VERSION "AgOpen Rate CAN ECU DBC with S0-S3 banks, 16 nodes, and service CAN"

NS_ :

BS_:

BU_: MASTER TOOL NODE1 NODE2 NODE3 NODE4 NODE5 NODE6 NODE7 NODE8 NODE9 NODE10 NODE11 NODE12 NODE13 NODE14 NODE15 NODE16

VAL_TABLE_ VT_system_mode 0 "OFF" 1 "MANUAL" 2 "AUTO" 3 "CALIBRATION" 4 "FAULT_HOLD";
VAL_TABLE_ VT_node_command 0 "NOP" 1 "ENABLE" 2 "DISABLE" 3 "ZERO_POS" 4 "CLEAR_FAULT";
VAL_TABLE_ VT_estop_cmd 165 "EMERGENCY_STOP";
VAL_TABLE_ VT_estop_reason 0 "manual" 1 "comm_fault" 2 "master_fault";
VAL_TABLE_ VT_srv_ack_result 0 "OK" 1 "unknown_command" 2 "bad_payload" 3 "wrong_uid" 4 "busy" 5 "save_failed" 6 "not_supported";
VAL_TABLE_ VT_srv_ident_mode 0 "LED_BLINK" 1 "SHORT_JOG";
VAL_TABLE_ VT_srv_test_mode 0 "RUN" 1 "COAST" 2 "BRAKE";

BO_ 128 S0_GLOBAL_CONTROL: 8 MASTER
 SG_ system_mode : 0|8@1+ (1,0) [0|255] ""  MASTER,NODE1,NODE2,NODE3,NODE4,NODE5,NODE6,NODE7,NODE8,NODE9,NODE10,NODE11,NODE12,NODE13,NODE14,NODE15,NODE16,TOOL
 SG_ control_flags : 8|8@1+ (1,0) [0|255] "bitfield"  MASTER,NODE1,NODE2,NODE3,NODE4,NODE5,NODE6,NODE7,NODE8,NODE9,NODE10,NODE11,NODE12,NODE13,NODE14,NODE15,NODE16,TOOL
 SG_ base_rpm : 16|16@1- (0.1,0) [-3276.8|3276.7] "rpm"  MASTER,NODE1,NODE2,NODE3,NODE4,NODE5,NODE6,NODE7,NODE8,NODE9,NODE10,NODE11,NODE12,NODE13,NODE14,NODE15,NODE16,TOOL
 SG_ sync_pos : 32|16@1+ (1.52587890625e-05,0) [0|0.9999847412109375] "rev"  MASTER,NODE1,NODE2,NODE3,NODE4,NODE5,NODE6,NODE7,NODE8,NODE9,NODE10,NODE11,NODE12,NODE13,NODE14,NODE15,NODE16,TOOL
 SG_ sequence : 48|8@1+ (1,0) [0|255] ""  MASTER,NODE1,NODE2,NODE3,NODE4,NODE5,NODE6,NODE7,NODE8,NODE9,NODE10,NODE11,NODE12,NODE13,NODE14,NODE15,NODE16,TOOL
 SG_ reserved : 56|8@1+ (1,0) [0|255] ""  MASTER,NODE1,NODE2,NODE3,NODE4,NODE5,NODE6,NODE7,NODE8,NODE9,NODE10,NODE11,NODE12,NODE13,NODE14,NODE15,NODE16,TOOL

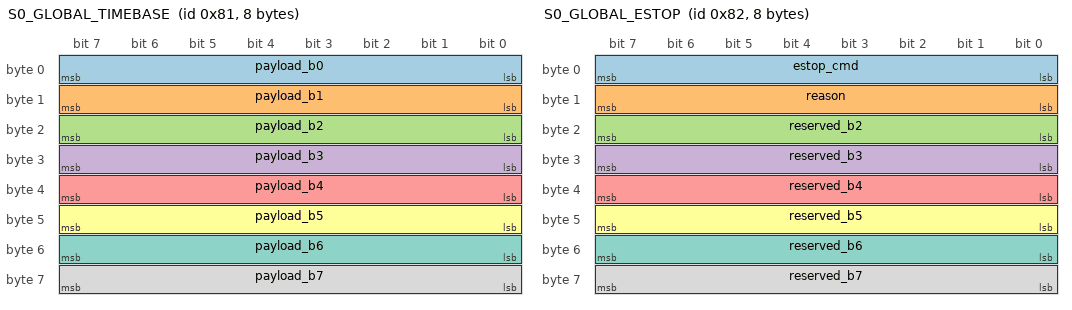
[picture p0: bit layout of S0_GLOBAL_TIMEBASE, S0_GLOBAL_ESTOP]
BO_ 129 S0_GLOBAL_TIMEBASE: 8 MASTER
 SG_ payload_b0 : 0|8@1+ (1,0) [0|255] "raw"  MASTER,NODE1,NODE2,NODE3,NODE4,NODE5,NODE6,NODE7,NODE8,NODE9,NODE10,NODE11,NODE12,NODE13,NODE14,NODE15,NODE16,TOOL
 SG_ payload_b1 : 8|8@1+ (1,0) [0|255] "raw"  MASTER,NODE1,NODE2,NODE3,NODE4,NODE5,NODE6,NODE7,NODE8,NODE9,NODE10,NODE11,NODE12,NODE13,NODE14,NODE15,NODE16,TOOL
 SG_ payload_b2 : 16|8@1+ (1,0) [0|255] "raw"  MASTER,NODE1,NODE2,NODE3,NODE4,NODE5,NODE6,NODE7,NODE8,NODE9,NODE10,NODE11,NODE12,NODE13,NODE14,NODE15,NODE16,TOOL
 SG_ payload_b3 : 24|8@1+ (1,0) [0|255] "raw"  MASTER,NODE1,NODE2,NODE3,NODE4,NODE5,NODE6,NODE7,NODE8,NODE9,NODE10,NODE11,NODE12,NODE13,NODE14,NODE15,NODE16,TOOL
 SG_ payload_b4 : 32|8@1+ (1,0) [0|255] "raw"  MASTER,NODE1,NODE2,NODE3,NODE4,NODE5,NODE6,NODE7,NODE8,NODE9,NODE10,NODE11,NODE12,NODE13,NODE14,NODE15,NODE16,TOOL
 SG_ payload_b5 : 40|8@1+ (1,0) [0|255] "raw"  MASTER,NODE1,NODE2,NODE3,NODE4,NODE5,NODE6,NODE7,NODE8,NODE9,NODE10,NODE11,NODE12,NODE13,NODE14,NODE15,NODE16,TOOL
 SG_ payload_b6 : 48|8@1+ (1,0) [0|255] "raw"  MASTER,NODE1,NODE2,NODE3,NODE4,NODE5,NODE6,NODE7,NODE8,NODE9,NODE10,NODE11,NODE12,NODE13,NODE14,NODE15,NODE16,TOOL
 SG_ payload_b7 : 56|8@1+ (1,0) [0|255] "raw"  MASTER,NODE1,NODE2,NODE3,NODE4,NODE5,NODE6,NODE7,NODE8,NODE9,NODE10,NODE11,NODE12,NODE13,NODE14,NODE15,NODE16,TOOL

BO_ 130 S0_GLOBAL_ESTOP: 8 MASTER
 SG_ estop_cmd : 0|8@1+ (1,0) [0|255] ""  MASTER,NODE1,NODE2,NODE3,NODE4,NODE5,NODE6,NODE7,NODE8,NODE9,NODE10,NODE11,NODE12,NODE13,NODE14,NODE15,NODE16,TOOL
 SG_ reason : 8|8@1+ (1,0) [0|255] ""  MASTER,NODE1,NODE2,NODE3,NODE4,NODE5,NODE6,NODE7,NODE8,NODE9,NODE10,NODE11,NODE12,NODE13,NODE14,NODE15,NODE16,TOOL
 SG_ reserved_b2 : 16|8@1+ (1,0) [0|255] ""  MASTER,NODE1,NODE2,NODE3,NODE4,NODE5,NODE6,NODE7,NODE8,NODE9,NODE10,NODE11,NODE12,NODE13,NODE14,NODE15,NODE16,TOOL
 SG_ reserved_b3 : 24|8@1+ (1,0) [0|255] ""  MASTER,NODE1,NODE2,NODE3,NODE4,NODE5,NODE6,NODE7,NODE8,NODE9,NODE10,NODE11,NODE12,NODE13,NODE14,NODE15,NODE16,TOOL
 SG_ reserved_b4 : 32|8@1+ (1,0) [0|255] ""  MASTER,NODE1,NODE2,NODE3,NODE4,NODE5,NODE6,NODE7,NODE8,NODE9,NODE10,NODE11,NODE12,NODE13,NODE14,NODE15,NODE16,TOOL
 SG_ reserved_b5 : 40|8@1+ (1,0) [0|255] ""  MASTER,NODE1,NODE2,NODE3,NODE4,NODE5,NODE6,NODE7,NODE8,NODE9,NODE10,NODE11,NODE12,NODE13,NODE14,NODE15,NODE16,TOOL
 SG_ reserved_b6 : 48|8@1+ (1,0) [0|255] ""  MASTER,NODE1,NODE2,NODE3,NODE4,NODE5,NODE6,NODE7,NODE8,NODE9,NODE10,NODE11,NODE12,NODE13,NODE14,NODE15,NODE16,TOOL
 SG_ reserved_b7 : 56|8@1+ (1,0) [0|255] ""  MASTER,NODE1,NODE2,NODE3,NODE4,NODE5,NODE6,NODE7,NODE8,NODE9,NODE10,NODE11,NODE12,NODE13,NODE14,NODE15,NODE16,TOOL

BO_ 257 S0_NODE_CMD_1: 8 MASTER
 SG_ node_command : 0|8@1+ (1,0) [0|255] ""  MASTER,NODE1,NODE2,NODE3,NODE4,NODE5,NODE6,NODE7,NODE8,NODE9,NODE10,NODE11,NODE12,NODE13,NODE14,NODE15,NODE16,TOOL
 SG_ node_flags : 8|8@1+ (1,0) [0|255] "bitfield"  MASTER,NODE1,NODE2,NODE3,NODE4,NODE5,NODE6,NODE7,NODE8,NODE9,NODE10,NODE11,NODE12,NODE13,NODE14,NODE15,NODE16,TOOL
 SG_ trim_rpm : 16|16@1- (0.1,0) [-3276.8|3276.7] "rpm"  MASTER,NODE1,NODE2,NODE3,NODE4,NODE5,NODE6,NODE7,NODE8,NODE9,NODE10,NODE11,NODE12,NODE13,NODE14,NODE15,NODE16,TOOL
 SG_ section_mask : 32|16@1+ (1,0) [0|65535] "bitmask"  MASTER,NODE1,NODE2,NODE3,NODE4,NODE5,NODE6,NODE7,NODE8,NODE9,NODE10,NODE11,NODE12,NODE13,NODE14,NODE15,NODE16,TOOL
 SG_ seq : 48|8@1+ (1,0) [0|255] ""  MASTER,NODE1,NODE2,NODE3,NODE4,NODE5,NODE6,NODE7,NODE8,NODE9,NODE10,NODE11,NODE12,NODE13,NODE14,NODE15,NODE16,TOOL
 SG_ reserved : 56|8@1+ (1,0) [0|255] ""  MASTER,NODE1,NODE2,NODE3,NODE4,NODE5,NODE6,NODE7,NODE8,NODE9,NODE10,NODE11,NODE12,NODE13,NODE14,NODE15,NODE16,TOOL

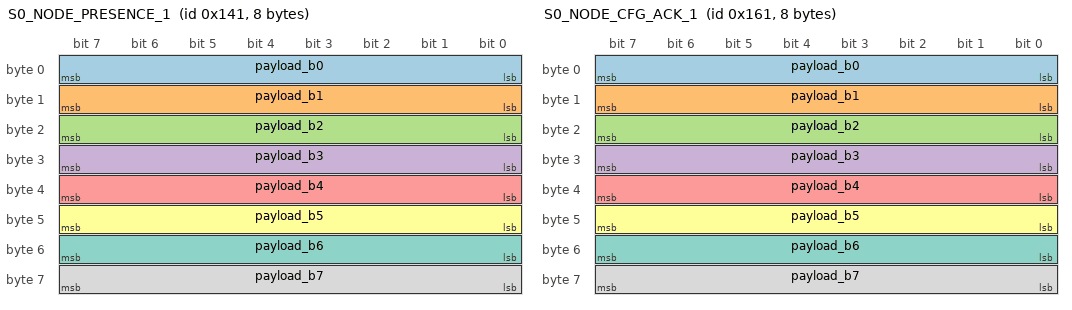
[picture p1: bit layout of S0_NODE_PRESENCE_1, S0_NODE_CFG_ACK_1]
BO_ 321 S0_NODE_PRESENCE_1: 8 NODE1
 SG_ payload_b0 : 0|8@1+ (1,0) [0|255] "raw"  MASTER,NODE1,NODE2,NODE3,NODE4,NODE5,NODE6,NODE7,NODE8,NODE9,NODE10,NODE11,NODE12,NODE13,NODE14,NODE15,NODE16,TOOL
 SG_ payload_b1 : 8|8@1+ (1,0) [0|255] "raw"  MASTER,NODE1,NODE2,NODE3,NODE4,NODE5,NODE6,NODE7,NODE8,NODE9,NODE10,NODE11,NODE12,NODE13,NODE14,NODE15,NODE16,TOOL
 SG_ payload_b2 : 16|8@1+ (1,0) [0|255] "raw"  MASTER,NODE1,NODE2,NODE3,NODE4,NODE5,NODE6,NODE7,NODE8,NODE9,NODE10,NODE11,NODE12,NODE13,NODE14,NODE15,NODE16,TOOL
 SG_ payload_b3 : 24|8@1+ (1,0) [0|255] "raw"  MASTER,NODE1,NODE2,NODE3,NODE4,NODE5,NODE6,NODE7,NODE8,NODE9,NODE10,NODE11,NODE12,NODE13,NODE14,NODE15,NODE16,TOOL
 SG_ payload_b4 : 32|8@1+ (1,0) [0|255] "raw"  MASTER,NODE1,NODE2,NODE3,NODE4,NODE5,NODE6,NODE7,NODE8,NODE9,NODE10,NODE11,NODE12,NODE13,NODE14,NODE15,NODE16,TOOL
 SG_ payload_b5 : 40|8@1+ (1,0) [0|255] "raw"  MASTER,NODE1,NODE2,NODE3,NODE4,NODE5,NODE6,NODE7,NODE8,NODE9,NODE10,NODE11,NODE12,NODE13,NODE14,NODE15,NODE16,TOOL
 SG_ payload_b6 : 48|8@1+ (1,0) [0|255] "raw"  MASTER,NODE1,NODE2,NODE3,NODE4,NODE5,NODE6,NODE7,NODE8,NODE9,NODE10,NODE11,NODE12,NODE13,NODE14,NODE15,NODE16,TOOL
 SG_ payload_b7 : 56|8@1+ (1,0) [0|255] "raw"  MASTER,NODE1,NODE2,NODE3,NODE4,NODE5,NODE6,NODE7,NODE8,NODE9,NODE10,NODE11,NODE12,NODE13,NODE14,NODE15,NODE16,TOOL

BO_ 353 S0_NODE_CFG_ACK_1: 8 NODE1
 SG_ payload_b0 : 0|8@1+ (1,0) [0|255] "raw"  MASTER,NODE1,NODE2,NODE3,NODE4,NODE5,NODE6,NODE7,NODE8,NODE9,NODE10,NODE11,NODE12,NODE13,NODE14,NODE15,NODE16,TOOL
 SG_ payload_b1 : 8|8@1+ (1,0) [0|255] "raw"  MASTER,NODE1,NODE2,NODE3,NODE4,NODE5,NODE6,NODE7,NODE8,NODE9,NODE10,NODE11,NODE12,NODE13,NODE14,NODE15,NODE16,TOOL
 SG_ payload_b2 : 16|8@1+ (1,0) [0|255] "raw"  MASTER,NODE1,NODE2,NODE3,NODE4,NODE5,NODE6,NODE7,NODE8,NODE9,NODE10,NODE11,NODE12,NODE13,NODE14,NODE15,NODE16,TOOL
 SG_ payload_b3 : 24|8@1+ (1,0) [0|255] "raw"  MASTER,NODE1,NODE2,NODE3,NODE4,NODE5,NODE6,NODE7,NODE8,NODE9,NODE10,NODE11,NODE12,NODE13,NODE14,NODE15,NODE16,TOOL
 SG_ payload_b4 : 32|8@1+ (1,0) [0|255] "raw"  MASTER,NODE1,NODE2,NODE3,NODE4,NODE5,NODE6,NODE7,NODE8,NODE9,NODE10,NODE11,NODE12,NODE13,NODE14,NODE15,NODE16,TOOL
 SG_ payload_b5 : 40|8@1+ (1,0) [0|255] "raw"  MASTER,NODE1,NODE2,NODE3,NODE4,NODE5,NODE6,NODE7,NODE8,NODE9,NODE10,NODE11,NODE12,NODE13,NODE14,NODE15,NODE16,TOOL
 SG_ payload_b6 : 48|8@1+ (1,0) [0|255] "raw"  MASTER,NODE1,NODE2,NODE3,NODE4,NODE5,NODE6,NODE7,NODE8,NODE9,NODE10,NODE11,NODE12,NODE13,NODE14,NODE15,NODE16,TOOL
 SG_ payload_b7 : 56|8@1+ (1,0) [0|255] "raw"  MASTER,NODE1,NODE2,NODE3,NODE4,NODE5,NODE6,NODE7,NODE8,NODE9,NODE10,NODE11,NODE12,NODE13,NODE14,NODE15,NODE16,TOOL

BO_ 385 S0_NODE_STATUS_FAST_1: 8 NODE1
 SG_ status_flags : 0|8@1+ (1,0) [0|255] "bitfield"  MASTER,NODE1,NODE2,NODE3,NODE4,NODE5,NODE6,NODE7,NODE8,NODE9,NODE10,NODE11,NODE12,NODE13,NODE14,NODE15,NODE16,TOOL
 SG_ error_code : 8|8@1+ (1,0) [0|255] ""  MASTER,NODE1,NODE2,NODE3,NODE4,NODE5,NODE6,NODE7,NODE8,NODE9,NODE10,NODE11,NODE12,NODE13,NODE14,NODE15,NODE16,TOOL
 SG_ actual_rpm : 16|16@1- (0.1,0) [-3276.8|3276.7] "rpm"  MASTER,NODE1,NODE2,NODE3,NODE4,NODE5,NODE6,NODE7,NODE8,NODE9,NODE10,NODE11,NODE12,NODE13,NODE14,NODE15,NODE16,TOOL
 SG_ actual_pos : 32|16@1+ (1.52587890625e-05,0) [0|0.9999847412109375] "rev"  MASTER,NODE1,NODE2,NODE3,NODE4,NODE5,NODE6,NODE7,NODE8,NODE9,NODE10,NODE11,NODE12,NODE13,NODE14,NODE15,NODE16,TOOL
 SG_ alive_counter : 48|8@1+ (1,0) [0|255] ""  MASTER,NODE1,NODE2,NODE3,NODE4,NODE5,NODE6,NODE7,NODE8,NODE9,NODE10,NODE11,NODE12,NODE13,NODE14,NODE15,NODE16,TOOL
 SG_ sync_error : 56|8@1- (0.00390625,0) [-0.5|0.49609375] "rev"  MASTER,NODE1,NODE2,NODE3,NODE4,NODE5,NODE6,NODE7,NODE8,NODE9,NODE10,NODE11,NODE12,NODE13,NODE14,NODE15,NODE16,TOOL

BO_ 449 S0_NODE_DIAG_1: 8 NODE1
 SG_ bus_voltage : 0|16@1+ (0.1,0) [0|6553.5] "V"  MASTER,NODE1,NODE2,NODE3,NODE4,NODE5,NODE6,NODE7,NODE8,NODE9,NODE10,NODE11,NODE12,NODE13,NODE14,NODE15,NODE16,TOOL
 SG_ motor_current : 16|16@1- (0.1,0) [-3276.8|3276.7] "A"  MASTER,NODE1,NODE2,NODE3,NODE4,NODE5,NODE6,NODE7,NODE8,NODE9,NODE10,NODE11,NODE12,NODE13,NODE14,NODE15,NODE16,TOOL
 SG_ controller_temp : 32|8@1- (1,0) [-128|127] "degC"  MASTER,NODE1,NODE2,NODE3,NODE4,NODE5,NODE6,NODE7,NODE8,NODE9,NODE10,NODE11,NODE12,NODE13,NODE14,NODE15,NODE16,TOOL
 SG_ motor_temp : 40|8@1- (1,0) [-128|127] "degC"  MASTER,NODE1,NODE2,NODE3,NODE4,NODE5,NODE6,NODE7,NODE8,NODE9,NODE10,NODE11,NODE12,NODE13,NODE14,NODE15,NODE16,TOOL
 SG_ fault_flags : 48|8@1+ (1,0) [0|255] "bitfield"  MASTER,NODE1,NODE2,NODE3,NODE4,NODE5,NODE6,NODE7,NODE8,NODE9,NODE10,NODE11,NODE12,NODE13,NODE14,NODE15,NODE16,TOOL
 SG_ warning_flags : 56|8@1+ (1,0) [0|255] "bitfield"  MASTER,NODE1,NODE2,NODE3,NODE4,NODE5,NODE6,NODE7,NODE8,NODE9,NODE10,NODE11,NODE12,NODE13,NODE14,NODE15,NODE16,TOOL

BO_ 258 S0_NODE_CMD_2: 8 MASTER
 SG_ node_command : 0|8@1+ (1,0) [0|255] ""  MASTER,NODE1,NODE2,NODE3,NODE4,NODE5,NODE6,NODE7,NODE8,NODE9,NODE10,NODE11,NODE12,NODE13,NODE14,NODE15,NODE16,TOOL
 SG_ node_flags : 8|8@1+ (1,0) [0|255] "bitfield"  MASTER,NODE1,NODE2,NODE3,NODE4,NODE5,NODE6,NODE7,NODE8,NODE9,NODE10,NODE11,NODE12,NODE13,NODE14,NODE15,NODE16,TOOL
 SG_ trim_rpm : 16|16@1- (0.1,0) [-3276.8|3276.7] "rpm"  MASTER,NODE1,NODE2,NODE3,NODE4,NODE5,NODE6,NODE7,NODE8,NODE9,NODE10,NODE11,NODE12,NODE13,NODE14,NODE15,NODE16,TOOL
 SG_ section_mask : 32|16@1+ (1,0) [0|65535] "bitmask"  MASTER,NODE1,NODE2,NODE3,NODE4,NODE5,NODE6,NODE7,NODE8,NODE9,NODE10,NODE11,NODE12,NODE13,NODE14,NODE15,NODE16,TOOL
 SG_ seq : 48|8@1+ (1,0) [0|255] ""  MASTER,NODE1,NODE2,NODE3,NODE4,NODE5,NODE6,NODE7,NODE8,NODE9,NODE10,NODE11,NODE12,NODE13,NODE14,NODE15,NODE16,TOOL
 SG_ reserved : 56|8@1+ (1,0) [0|255] ""  MASTER,NODE1,NODE2,NODE3,NODE4,NODE5,NODE6,NODE7,NODE8,NODE9,NODE10,NODE11,NODE12,NODE13,NODE14,NODE15,NODE16,TOOL

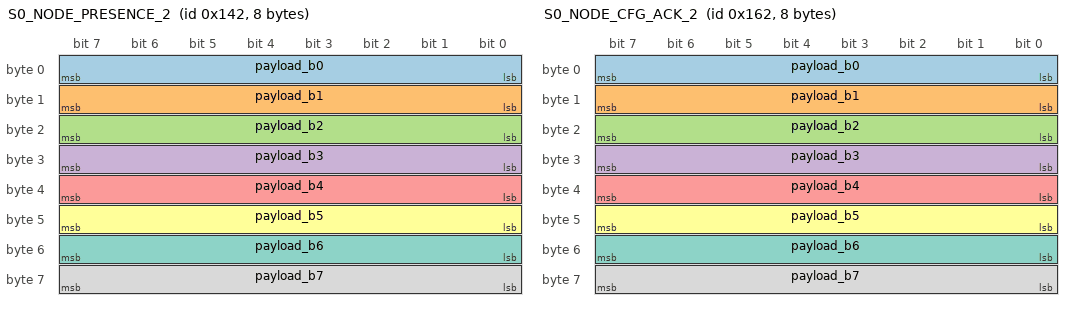
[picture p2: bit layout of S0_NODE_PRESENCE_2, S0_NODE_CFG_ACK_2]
BO_ 322 S0_NODE_PRESENCE_2: 8 NODE2
 SG_ payload_b0 : 0|8@1+ (1,0) [0|255] "raw"  MASTER,NODE1,NODE2,NODE3,NODE4,NODE5,NODE6,NODE7,NODE8,NODE9,NODE10,NODE11,NODE12,NODE13,NODE14,NODE15,NODE16,TOOL
 SG_ payload_b1 : 8|8@1+ (1,0) [0|255] "raw"  MASTER,NODE1,NODE2,NODE3,NODE4,NODE5,NODE6,NODE7,NODE8,NODE9,NODE10,NODE11,NODE12,NODE13,NODE14,NODE15,NODE16,TOOL
 SG_ payload_b2 : 16|8@1+ (1,0) [0|255] "raw"  MASTER,NODE1,NODE2,NODE3,NODE4,NODE5,NODE6,NODE7,NODE8,NODE9,NODE10,NODE11,NODE12,NODE13,NODE14,NODE15,NODE16,TOOL
 SG_ payload_b3 : 24|8@1+ (1,0) [0|255] "raw"  MASTER,NODE1,NODE2,NODE3,NODE4,NODE5,NODE6,NODE7,NODE8,NODE9,NODE10,NODE11,NODE12,NODE13,NODE14,NODE15,NODE16,TOOL
 SG_ payload_b4 : 32|8@1+ (1,0) [0|255] "raw"  MASTER,NODE1,NODE2,NODE3,NODE4,NODE5,NODE6,NODE7,NODE8,NODE9,NODE10,NODE11,NODE12,NODE13,NODE14,NODE15,NODE16,TOOL
 SG_ payload_b5 : 40|8@1+ (1,0) [0|255] "raw"  MASTER,NODE1,NODE2,NODE3,NODE4,NODE5,NODE6,NODE7,NODE8,NODE9,NODE10,NODE11,NODE12,NODE13,NODE14,NODE15,NODE16,TOOL
 SG_ payload_b6 : 48|8@1+ (1,0) [0|255] "raw"  MASTER,NODE1,NODE2,NODE3,NODE4,NODE5,NODE6,NODE7,NODE8,NODE9,NODE10,NODE11,NODE12,NODE13,NODE14,NODE15,NODE16,TOOL
 SG_ payload_b7 : 56|8@1+ (1,0) [0|255] "raw"  MASTER,NODE1,NODE2,NODE3,NODE4,NODE5,NODE6,NODE7,NODE8,NODE9,NODE10,NODE11,NODE12,NODE13,NODE14,NODE15,NODE16,TOOL

BO_ 354 S0_NODE_CFG_ACK_2: 8 NODE2
 SG_ payload_b0 : 0|8@1+ (1,0) [0|255] "raw"  MASTER,NODE1,NODE2,NODE3,NODE4,NODE5,NODE6,NODE7,NODE8,NODE9,NODE10,NODE11,NODE12,NODE13,NODE14,NODE15,NODE16,TOOL
 SG_ payload_b1 : 8|8@1+ (1,0) [0|255] "raw"  MASTER,NODE1,NODE2,NODE3,NODE4,NODE5,NODE6,NODE7,NODE8,NODE9,NODE10,NODE11,NODE12,NODE13,NODE14,NODE15,NODE16,TOOL
 SG_ payload_b2 : 16|8@1+ (1,0) [0|255] "raw"  MASTER,NODE1,NODE2,NODE3,NODE4,NODE5,NODE6,NODE7,NODE8,NODE9,NODE10,NODE11,NODE12,NODE13,NODE14,NODE15,NODE16,TOOL
 SG_ payload_b3 : 24|8@1+ (1,0) [0|255] "raw"  MASTER,NODE1,NODE2,NODE3,NODE4,NODE5,NODE6,NODE7,NODE8,NODE9,NODE10,NODE11,NODE12,NODE13,NODE14,NODE15,NODE16,TOOL
 SG_ payload_b4 : 32|8@1+ (1,0) [0|255] "raw"  MASTER,NODE1,NODE2,NODE3,NODE4,NODE5,NODE6,NODE7,NODE8,NODE9,NODE10,NODE11,NODE12,NODE13,NODE14,NODE15,NODE16,TOOL
 SG_ payload_b5 : 40|8@1+ (1,0) [0|255] "raw"  MASTER,NODE1,NODE2,NODE3,NODE4,NODE5,NODE6,NODE7,NODE8,NODE9,NODE10,NODE11,NODE12,NODE13,NODE14,NODE15,NODE16,TOOL
 SG_ payload_b6 : 48|8@1+ (1,0) [0|255] "raw"  MASTER,NODE1,NODE2,NODE3,NODE4,NODE5,NODE6,NODE7,NODE8,NODE9,NODE10,NODE11,NODE12,NODE13,NODE14,NODE15,NODE16,TOOL
 SG_ payload_b7 : 56|8@1+ (1,0) [0|255] "raw"  MASTER,NODE1,NODE2,NODE3,NODE4,NODE5,NODE6,NODE7,NODE8,NODE9,NODE10,NODE11,NODE12,NODE13,NODE14,NODE15,NODE16,TOOL

BO_ 386 S0_NODE_STATUS_FAST_2: 8 NODE2
 SG_ status_flags : 0|8@1+ (1,0) [0|255] "bitfield"  MASTER,NODE1,NODE2,NODE3,NODE4,NODE5,NODE6,NODE7,NODE8,NODE9,NODE10,NODE11,NODE12,NODE13,NODE14,NODE15,NODE16,TOOL
 SG_ error_code : 8|8@1+ (1,0) [0|255] ""  MASTER,NODE1,NODE2,NODE3,NODE4,NODE5,NODE6,NODE7,NODE8,NODE9,NODE10,NODE11,NODE12,NODE13,NODE14,NODE15,NODE16,TOOL
 SG_ actual_rpm : 16|16@1- (0.1,0) [-3276.8|3276.7] "rpm"  MASTER,NODE1,NODE2,NODE3,NODE4,NODE5,NODE6,NODE7,NODE8,NODE9,NODE10,NODE11,NODE12,NODE13,NODE14,NODE15,NODE16,TOOL
 SG_ actual_pos : 32|16@1+ (1.52587890625e-05,0) [0|0.9999847412109375] "rev"  MASTER,NODE1,NODE2,NODE3,NODE4,NODE5,NODE6,NODE7,NODE8,NODE9,NODE10,NODE11,NODE12,NODE13,NODE14,NODE15,NODE16,TOOL
 SG_ alive_counter : 48|8@1+ (1,0) [0|255] ""  MASTER,NODE1,NODE2,NODE3,NODE4,NODE5,NODE6,NODE7,NODE8,NODE9,NODE10,NODE11,NODE12,NODE13,NODE14,NODE15,NODE16,TOOL
 SG_ sync_error : 56|8@1- (0.00390625,0) [-0.5|0.49609375] "rev"  MASTER,NODE1,NODE2,NODE3,NODE4,NODE5,NODE6,NODE7,NODE8,NODE9,NODE10,NODE11,NODE12,NODE13,NODE14,NODE15,NODE16,TOOL

BO_ 450 S0_NODE_DIAG_2: 8 NODE2
 SG_ bus_voltage : 0|16@1+ (0.1,0) [0|6553.5] "V"  MASTER,NODE1,NODE2,NODE3,NODE4,NODE5,NODE6,NODE7,NODE8,NODE9,NODE10,NODE11,NODE12,NODE13,NODE14,NODE15,NODE16,TOOL
 SG_ motor_current : 16|16@1- (0.1,0) [-3276.8|3276.7] "A"  MASTER,NODE1,NODE2,NODE3,NODE4,NODE5,NODE6,NODE7,NODE8,NODE9,NODE10,NODE11,NODE12,NODE13,NODE14,NODE15,NODE16,TOOL
 SG_ controller_temp : 32|8@1- (1,0) [-128|127] "degC"  MASTER,NODE1,NODE2,NODE3,NODE4,NODE5,NODE6,NODE7,NODE8,NODE9,NODE10,NODE11,NODE12,NODE13,NODE14,NODE15,NODE16,TOOL
 SG_ motor_temp : 40|8@1- (1,0) [-128|127] "degC"  MASTER,NODE1,NODE2,NODE3,NODE4,NODE5,NODE6,NODE7,NODE8,NODE9,NODE10,NODE11,NODE12,NODE13,NODE14,NODE15,NODE16,TOOL
 SG_ fault_flags : 48|8@1+ (1,0) [0|255] "bitfield"  MASTER,NODE1,NODE2,NODE3,NODE4,NODE5,NODE6,NODE7,NODE8,NODE9,NODE10,NODE11,NODE12,NODE13,NODE14,NODE15,NODE16,TOOL
 SG_ warning_flags : 56|8@1+ (1,0) [0|255] "bitfield"  MASTER,NODE1,NODE2,NODE3,NODE4,NODE5,NODE6,NODE7,NODE8,NODE9,NODE10,NODE11,NODE12,NODE13,NODE14,NODE15,NODE16,TOOL

BO_ 259 S0_NODE_CMD_3: 8 MASTER
 SG_ node_command : 0|8@1+ (1,0) [0|255] ""  MASTER,NODE1,NODE2,NODE3,NODE4,NODE5,NODE6,NODE7,NODE8,NODE9,NODE10,NODE11,NODE12,NODE13,NODE14,NODE15,NODE16,TOOL
 SG_ node_flags : 8|8@1+ (1,0) [0|255] "bitfield"  MASTER,NODE1,NODE2,NODE3,NODE4,NODE5,NODE6,NODE7,NODE8,NODE9,NODE10,NODE11,NODE12,NODE13,NODE14,NODE15,NODE16,TOOL
 SG_ trim_rpm : 16|16@1- (0.1,0) [-3276.8|3276.7] "rpm"  MASTER,NODE1,NODE2,NODE3,NODE4,NODE5,NODE6,NODE7,NODE8,NODE9,NODE10,NODE11,NODE12,NODE13,NODE14,NODE15,NODE16,TOOL
 SG_ section_mask : 32|16@1+ (1,0) [0|65535] "bitmask"  MASTER,NODE1,NODE2,NODE3,NODE4,NODE5,NODE6,NODE7,NODE8,NODE9,NODE10,NODE11,NODE12,NODE13,NODE14,NODE15,NODE16,TOOL
 SG_ seq : 48|8@1+ (1,0) [0|255] ""  MASTER,NODE1,NODE2,NODE3,NODE4,NODE5,NODE6,NODE7,NODE8,NODE9,NODE10,NODE11,NODE12,NODE13,NODE14,NODE15,NODE16,TOOL
 SG_ reserved : 56|8@1+ (1,0) [0|255] ""  MASTER,NODE1,NODE2,NODE3,NODE4,NODE5,NODE6,NODE7,NODE8,NODE9,NODE10,NODE11,NODE12,NODE13,NODE14,NODE15,NODE16,TOOL

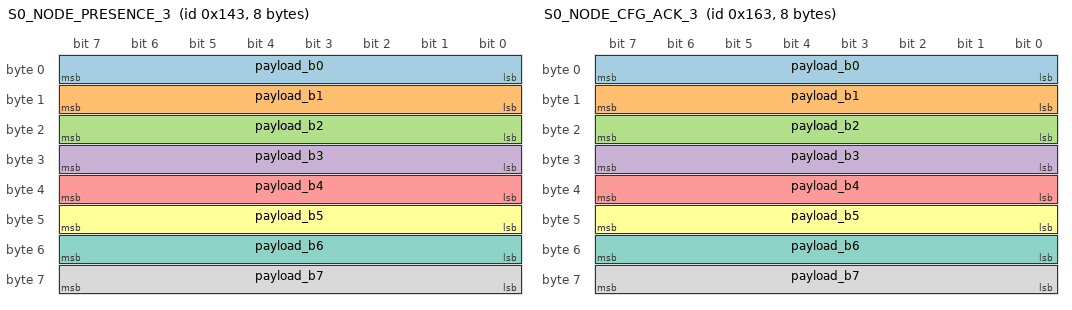
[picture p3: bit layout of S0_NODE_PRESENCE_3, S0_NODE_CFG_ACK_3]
BO_ 323 S0_NODE_PRESENCE_3: 8 NODE3
 SG_ payload_b0 : 0|8@1+ (1,0) [0|255] "raw"  MASTER,NODE1,NODE2,NODE3,NODE4,NODE5,NODE6,NODE7,NODE8,NODE9,NODE10,NODE11,NODE12,NODE13,NODE14,NODE15,NODE16,TOOL
 SG_ payload_b1 : 8|8@1+ (1,0) [0|255] "raw"  MASTER,NODE1,NODE2,NODE3,NODE4,NODE5,NODE6,NODE7,NODE8,NODE9,NODE10,NODE11,NODE12,NODE13,NODE14,NODE15,NODE16,TOOL
 SG_ payload_b2 : 16|8@1+ (1,0) [0|255] "raw"  MASTER,NODE1,NODE2,NODE3,NODE4,NODE5,NODE6,NODE7,NODE8,NODE9,NODE10,NODE11,NODE12,NODE13,NODE14,NODE15,NODE16,TOOL
 SG_ payload_b3 : 24|8@1+ (1,0) [0|255] "raw"  MASTER,NODE1,NODE2,NODE3,NODE4,NODE5,NODE6,NODE7,NODE8,NODE9,NODE10,NODE11,NODE12,NODE13,NODE14,NODE15,NODE16,TOOL
 SG_ payload_b4 : 32|8@1+ (1,0) [0|255] "raw"  MASTER,NODE1,NODE2,NODE3,NODE4,NODE5,NODE6,NODE7,NODE8,NODE9,NODE10,NODE11,NODE12,NODE13,NODE14,NODE15,NODE16,TOOL
 SG_ payload_b5 : 40|8@1+ (1,0) [0|255] "raw"  MASTER,NODE1,NODE2,NODE3,NODE4,NODE5,NODE6,NODE7,NODE8,NODE9,NODE10,NODE11,NODE12,NODE13,NODE14,NODE15,NODE16,TOOL
 SG_ payload_b6 : 48|8@1+ (1,0) [0|255] "raw"  MASTER,NODE1,NODE2,NODE3,NODE4,NODE5,NODE6,NODE7,NODE8,NODE9,NODE10,NODE11,NODE12,NODE13,NODE14,NODE15,NODE16,TOOL
 SG_ payload_b7 : 56|8@1+ (1,0) [0|255] "raw"  MASTER,NODE1,NODE2,NODE3,NODE4,NODE5,NODE6,NODE7,NODE8,NODE9,NODE10,NODE11,NODE12,NODE13,NODE14,NODE15,NODE16,TOOL

BO_ 355 S0_NODE_CFG_ACK_3: 8 NODE3
 SG_ payload_b0 : 0|8@1+ (1,0) [0|255] "raw"  MASTER,NODE1,NODE2,NODE3,NODE4,NODE5,NODE6,NODE7,NODE8,NODE9,NODE10,NODE11,NODE12,NODE13,NODE14,NODE15,NODE16,TOOL
 SG_ payload_b1 : 8|8@1+ (1,0) [0|255] "raw"  MASTER,NODE1,NODE2,NODE3,NODE4,NODE5,NODE6,NODE7,NODE8,NODE9,NODE10,NODE11,NODE12,NODE13,NODE14,NODE15,NODE16,TOOL
 SG_ payload_b2 : 16|8@1+ (1,0) [0|255] "raw"  MASTER,NODE1,NODE2,NODE3,NODE4,NODE5,NODE6,NODE7,NODE8,NODE9,NODE10,NODE11,NODE12,NODE13,NODE14,NODE15,NODE16,TOOL
 SG_ payload_b3 : 24|8@1+ (1,0) [0|255] "raw"  MASTER,NODE1,NODE2,NODE3,NODE4,NODE5,NODE6,NODE7,NODE8,NODE9,NODE10,NODE11,NODE12,NODE13,NODE14,NODE15,NODE16,TOOL
 SG_ payload_b4 : 32|8@1+ (1,0) [0|255] "raw"  MASTER,NODE1,NODE2,NODE3,NODE4,NODE5,NODE6,NODE7,NODE8,NODE9,NODE10,NODE11,NODE12,NODE13,NODE14,NODE15,NODE16,TOOL
 SG_ payload_b5 : 40|8@1+ (1,0) [0|255] "raw"  MASTER,NODE1,NODE2,NODE3,NODE4,NODE5,NODE6,NODE7,NODE8,NODE9,NODE10,NODE11,NODE12,NODE13,NODE14,NODE15,NODE16,TOOL
 SG_ payload_b6 : 48|8@1+ (1,0) [0|255] "raw"  MASTER,NODE1,NODE2,NODE3,NODE4,NODE5,NODE6,NODE7,NODE8,NODE9,NODE10,NODE11,NODE12,NODE13,NODE14,NODE15,NODE16,TOOL
 SG_ payload_b7 : 56|8@1+ (1,0) [0|255] "raw"  MASTER,NODE1,NODE2,NODE3,NODE4,NODE5,NODE6,NODE7,NODE8,NODE9,NODE10,NODE11,NODE12,NODE13,NODE14,NODE15,NODE16,TOOL

BO_ 387 S0_NODE_STATUS_FAST_3: 8 NODE3
 SG_ status_flags : 0|8@1+ (1,0) [0|255] "bitfield"  MASTER,NODE1,NODE2,NODE3,NODE4,NODE5,NODE6,NODE7,NODE8,NODE9,NODE10,NODE11,NODE12,NODE13,NODE14,NODE15,NODE16,TOOL
 SG_ error_code : 8|8@1+ (1,0) [0|255] ""  MASTER,NODE1,NODE2,NODE3,NODE4,NODE5,NODE6,NODE7,NODE8,NODE9,NODE10,NODE11,NODE12,NODE13,NODE14,NODE15,NODE16,TOOL
 SG_ actual_rpm : 16|16@1- (0.1,0) [-3276.8|3276.7] "rpm"  MASTER,NODE1,NODE2,NODE3,NODE4,NODE5,NODE6,NODE7,NODE8,NODE9,NODE10,NODE11,NODE12,NODE13,NODE14,NODE15,NODE16,TOOL
 SG_ actual_pos : 32|16@1+ (1.52587890625e-05,0) [0|0.9999847412109375] "rev"  MASTER,NODE1,NODE2,NODE3,NODE4,NODE5,NODE6,NODE7,NODE8,NODE9,NODE10,NODE11,NODE12,NODE13,NODE14,NODE15,NODE16,TOOL
 SG_ alive_counter : 48|8@1+ (1,0) [0|255] ""  MASTER,NODE1,NODE2,NODE3,NODE4,NODE5,NODE6,NODE7,NODE8,NODE9,NODE10,NODE11,NODE12,NODE13,NODE14,NODE15,NODE16,TOOL
 SG_ sync_error : 56|8@1- (0.00390625,0) [-0.5|0.49609375] "rev"  MASTER,NODE1,NODE2,NODE3,NODE4,NODE5,NODE6,NODE7,NODE8,NODE9,NODE10,NODE11,NODE12,NODE13,NODE14,NODE15,NODE16,TOOL

BO_ 451 S0_NODE_DIAG_3: 8 NODE3
 SG_ bus_voltage : 0|16@1+ (0.1,0) [0|6553.5] "V"  MASTER,NODE1,NODE2,NODE3,NODE4,NODE5,NODE6,NODE7,NODE8,NODE9,NODE10,NODE11,NODE12,NODE13,NODE14,NODE15,NODE16,TOOL
 SG_ motor_current : 16|16@1- (0.1,0) [-3276.8|3276.7] "A"  MASTER,NODE1,NODE2,NODE3,NODE4,NODE5,NODE6,NODE7,NODE8,NODE9,NODE10,NODE11,NODE12,NODE13,NODE14,NODE15,NODE16,TOOL
 SG_ controller_temp : 32|8@1- (1,0) [-128|127] "degC"  MASTER,NODE1,NODE2,NODE3,NODE4,NODE5,NODE6,NODE7,NODE8,NODE9,NODE10,NODE11,NODE12,NODE13,NODE14,NODE15,NODE16,TOOL
 SG_ motor_temp : 40|8@1- (1,0) [-128|127] "degC"  MASTER,NODE1,NODE2,NODE3,NODE4,NODE5,NODE6,NODE7,NODE8,NODE9,NODE10,NODE11,NODE12,NODE13,NODE14,NODE15,NODE16,TOOL
 SG_ fault_flags : 48|8@1+ (1,0) [0|255] "bitfield"  MASTER,NODE1,NODE2,NODE3,NODE4,NODE5,NODE6,NODE7,NODE8,NODE9,NODE10,NODE11,NODE12,NODE13,NODE14,NODE15,NODE16,TOOL
 SG_ warning_flags : 56|8@1+ (1,0) [0|255] "bitfield"  MASTER,NODE1,NODE2,NODE3,NODE4,NODE5,NODE6,NODE7,NODE8,NODE9,NODE10,NODE11,NODE12,NODE13,NODE14,NODE15,NODE16,TOOL

BO_ 260 S0_NODE_CMD_4: 8 MASTER
 SG_ node_command : 0|8@1+ (1,0) [0|255] ""  MASTER,NODE1,NODE2,NODE3,NODE4,NODE5,NODE6,NODE7,NODE8,NODE9,NODE10,NODE11,NODE12,NODE13,NODE14,NODE15,NODE16,TOOL
 SG_ node_flags : 8|8@1+ (1,0) [0|255] "bitfield"  MASTER,NODE1,NODE2,NODE3,NODE4,NODE5,NODE6,NODE7,NODE8,NODE9,NODE10,NODE11,NODE12,NODE13,NODE14,NODE15,NODE16,TOOL
 SG_ trim_rpm : 16|16@1- (0.1,0) [-3276.8|3276.7] "rpm"  MASTER,NODE1,NODE2,NODE3,NODE4,NODE5,NODE6,NODE7,NODE8,NODE9,NODE10,NODE11,NODE12,NODE13,NODE14,NODE15,NODE16,TOOL
 SG_ section_mask : 32|16@1+ (1,0) [0|65535] "bitmask"  MASTER,NODE1,NODE2,NODE3,NODE4,NODE5,NODE6,NODE7,NODE8,NODE9,NODE10,NODE11,NODE12,NODE13,NODE14,NODE15,NODE16,TOOL
 SG_ seq : 48|8@1+ (1,0) [0|255] ""  MASTER,NODE1,NODE2,NODE3,NODE4,NODE5,NODE6,NODE7,NODE8,NODE9,NODE10,NODE11,NODE12,NODE13,NODE14,NODE15,NODE16,TOOL
 SG_ reserved : 56|8@1+ (1,0) [0|255] ""  MASTER,NODE1,NODE2,NODE3,NODE4,NODE5,NODE6,NODE7,NODE8,NODE9,NODE10,NODE11,NODE12,NODE13,NODE14,NODE15,NODE16,TOOL

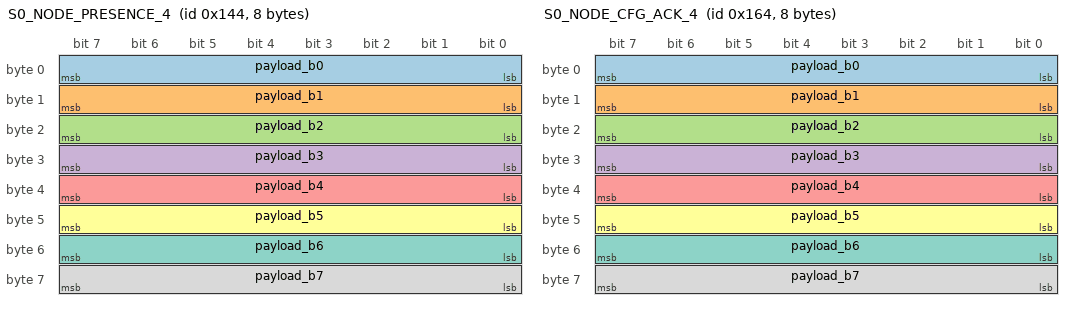
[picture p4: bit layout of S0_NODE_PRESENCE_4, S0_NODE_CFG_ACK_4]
BO_ 324 S0_NODE_PRESENCE_4: 8 NODE4
 SG_ payload_b0 : 0|8@1+ (1,0) [0|255] "raw"  MASTER,NODE1,NODE2,NODE3,NODE4,NODE5,NODE6,NODE7,NODE8,NODE9,NODE10,NODE11,NODE12,NODE13,NODE14,NODE15,NODE16,TOOL
 SG_ payload_b1 : 8|8@1+ (1,0) [0|255] "raw"  MASTER,NODE1,NODE2,NODE3,NODE4,NODE5,NODE6,NODE7,NODE8,NODE9,NODE10,NODE11,NODE12,NODE13,NODE14,NODE15,NODE16,TOOL
 SG_ payload_b2 : 16|8@1+ (1,0) [0|255] "raw"  MASTER,NODE1,NODE2,NODE3,NODE4,NODE5,NODE6,NODE7,NODE8,NODE9,NODE10,NODE11,NODE12,NODE13,NODE14,NODE15,NODE16,TOOL
 SG_ payload_b3 : 24|8@1+ (1,0) [0|255] "raw"  MASTER,NODE1,NODE2,NODE3,NODE4,NODE5,NODE6,NODE7,NODE8,NODE9,NODE10,NODE11,NODE12,NODE13,NODE14,NODE15,NODE16,TOOL
 SG_ payload_b4 : 32|8@1+ (1,0) [0|255] "raw"  MASTER,NODE1,NODE2,NODE3,NODE4,NODE5,NODE6,NODE7,NODE8,NODE9,NODE10,NODE11,NODE12,NODE13,NODE14,NODE15,NODE16,TOOL
 SG_ payload_b5 : 40|8@1+ (1,0) [0|255] "raw"  MASTER,NODE1,NODE2,NODE3,NODE4,NODE5,NODE6,NODE7,NODE8,NODE9,NODE10,NODE11,NODE12,NODE13,NODE14,NODE15,NODE16,TOOL
 SG_ payload_b6 : 48|8@1+ (1,0) [0|255] "raw"  MASTER,NODE1,NODE2,NODE3,NODE4,NODE5,NODE6,NODE7,NODE8,NODE9,NODE10,NODE11,NODE12,NODE13,NODE14,NODE15,NODE16,TOOL
 SG_ payload_b7 : 56|8@1+ (1,0) [0|255] "raw"  MASTER,NODE1,NODE2,NODE3,NODE4,NODE5,NODE6,NODE7,NODE8,NODE9,NODE10,NODE11,NODE12,NODE13,NODE14,NODE15,NODE16,TOOL

BO_ 356 S0_NODE_CFG_ACK_4: 8 NODE4
 SG_ payload_b0 : 0|8@1+ (1,0) [0|255] "raw"  MASTER,NODE1,NODE2,NODE3,NODE4,NODE5,NODE6,NODE7,NODE8,NODE9,NODE10,NODE11,NODE12,NODE13,NODE14,NODE15,NODE16,TOOL
 SG_ payload_b1 : 8|8@1+ (1,0) [0|255] "raw"  MASTER,NODE1,NODE2,NODE3,NODE4,NODE5,NODE6,NODE7,NODE8,NODE9,NODE10,NODE11,NODE12,NODE13,NODE14,NODE15,NODE16,TOOL
 SG_ payload_b2 : 16|8@1+ (1,0) [0|255] "raw"  MASTER,NODE1,NODE2,NODE3,NODE4,NODE5,NODE6,NODE7,NODE8,NODE9,NODE10,NODE11,NODE12,NODE13,NODE14,NODE15,NODE16,TOOL
 SG_ payload_b3 : 24|8@1+ (1,0) [0|255] "raw"  MASTER,NODE1,NODE2,NODE3,NODE4,NODE5,NODE6,NODE7,NODE8,NODE9,NODE10,NODE11,NODE12,NODE13,NODE14,NODE15,NODE16,TOOL
 SG_ payload_b4 : 32|8@1+ (1,0) [0|255] "raw"  MASTER,NODE1,NODE2,NODE3,NODE4,NODE5,NODE6,NODE7,NODE8,NODE9,NODE10,NODE11,NODE12,NODE13,NODE14,NODE15,NODE16,TOOL
 SG_ payload_b5 : 40|8@1+ (1,0) [0|255] "raw"  MASTER,NODE1,NODE2,NODE3,NODE4,NODE5,NODE6,NODE7,NODE8,NODE9,NODE10,NODE11,NODE12,NODE13,NODE14,NODE15,NODE16,TOOL
 SG_ payload_b6 : 48|8@1+ (1,0) [0|255] "raw"  MASTER,NODE1,NODE2,NODE3,NODE4,NODE5,NODE6,NODE7,NODE8,NODE9,NODE10,NODE11,NODE12,NODE13,NODE14,NODE15,NODE16,TOOL
 SG_ payload_b7 : 56|8@1+ (1,0) [0|255] "raw"  MASTER,NODE1,NODE2,NODE3,NODE4,NODE5,NODE6,NODE7,NODE8,NODE9,NODE10,NODE11,NODE12,NODE13,NODE14,NODE15,NODE16,TOOL

BO_ 388 S0_NODE_STATUS_FAST_4: 8 NODE4
 SG_ status_flags : 0|8@1+ (1,0) [0|255] "bitfield"  MASTER,NODE1,NODE2,NODE3,NODE4,NODE5,NODE6,NODE7,NODE8,NODE9,NODE10,NODE11,NODE12,NODE13,NODE14,NODE15,NODE16,TOOL
 SG_ error_code : 8|8@1+ (1,0) [0|255] ""  MASTER,NODE1,NODE2,NODE3,NODE4,NODE5,NODE6,NODE7,NODE8,NODE9,NODE10,NODE11,NODE12,NODE13,NODE14,NODE15,NODE16,TOOL
 SG_ actual_rpm : 16|16@1- (0.1,0) [-3276.8|3276.7] "rpm"  MASTER,NODE1,NODE2,NODE3,NODE4,NODE5,NODE6,NODE7,NODE8,NODE9,NODE10,NODE11,NODE12,NODE13,NODE14,NODE15,NODE16,TOOL
 SG_ actual_pos : 32|16@1+ (1.52587890625e-05,0) [0|0.9999847412109375] "rev"  MASTER,NODE1,NODE2,NODE3,NODE4,NODE5,NODE6,NODE7,NODE8,NODE9,NODE10,NODE11,NODE12,NODE13,NODE14,NODE15,NODE16,TOOL
 SG_ alive_counter : 48|8@1+ (1,0) [0|255] ""  MASTER,NODE1,NODE2,NODE3,NODE4,NODE5,NODE6,NODE7,NODE8,NODE9,NODE10,NODE11,NODE12,NODE13,NODE14,NODE15,NODE16,TOOL
 SG_ sync_error : 56|8@1- (0.00390625,0) [-0.5|0.49609375] "rev"  MASTER,NODE1,NODE2,NODE3,NODE4,NODE5,NODE6,NODE7,NODE8,NODE9,NODE10,NODE11,NODE12,NODE13,NODE14,NODE15,NODE16,TOOL

BO_ 452 S0_NODE_DIAG_4: 8 NODE4
 SG_ bus_voltage : 0|16@1+ (0.1,0) [0|6553.5] "V"  MASTER,NODE1,NODE2,NODE3,NODE4,NODE5,NODE6,NODE7,NODE8,NODE9,NODE10,NODE11,NODE12,NODE13,NODE14,NODE15,NODE16,TOOL
 SG_ motor_current : 16|16@1- (0.1,0) [-3276.8|3276.7] "A"  MASTER,NODE1,NODE2,NODE3,NODE4,NODE5,NODE6,NODE7,NODE8,NODE9,NODE10,NODE11,NODE12,NODE13,NODE14,NODE15,NODE16,TOOL
 SG_ controller_temp : 32|8@1- (1,0) [-128|127] "degC"  MASTER,NODE1,NODE2,NODE3,NODE4,NODE5,NODE6,NODE7,NODE8,NODE9,NODE10,NODE11,NODE12,NODE13,NODE14,NODE15,NODE16,TOOL
 SG_ motor_temp : 40|8@1- (1,0) [-128|127] "degC"  MASTER,NODE1,NODE2,NODE3,NODE4,NODE5,NODE6,NODE7,NODE8,NODE9,NODE10,NODE11,NODE12,NODE13,NODE14,NODE15,NODE16,TOOL
 SG_ fault_flags : 48|8@1+ (1,0) [0|255] "bitfield"  MASTER,NODE1,NODE2,NODE3,NODE4,NODE5,NODE6,NODE7,NODE8,NODE9,NODE10,NODE11,NODE12,NODE13,NODE14,NODE15,NODE16,TOOL
 SG_ warning_flags : 56|8@1+ (1,0) [0|255] "bitfield"  MASTER,NODE1,NODE2,NODE3,NODE4,NODE5,NODE6,NODE7,NODE8,NODE9,NODE10,NODE11,NODE12,NODE13,NODE14,NODE15,NODE16,TOOL

BO_ 261 S0_NODE_CMD_5: 8 MASTER
 SG_ node_command : 0|8@1+ (1,0) [0|255] ""  MASTER,NODE1,NODE2,NODE3,NODE4,NODE5,NODE6,NODE7,NODE8,NODE9,NODE10,NODE11,NODE12,NODE13,NODE14,NODE15,NODE16,TOOL
 SG_ node_flags : 8|8@1+ (1,0) [0|255] "bitfield"  MASTER,NODE1,NODE2,NODE3,NODE4,NODE5,NODE6,NODE7,NODE8,NODE9,NODE10,NODE11,NODE12,NODE13,NODE14,NODE15,NODE16,TOOL
 SG_ trim_rpm : 16|16@1- (0.1,0) [-3276.8|3276.7] "rpm"  MASTER,NODE1,NODE2,NODE3,NODE4,NODE5,NODE6,NODE7,NODE8,NODE9,NODE10,NODE11,NODE12,NODE13,NODE14,NODE15,NODE16,TOOL
 SG_ section_mask : 32|16@1+ (1,0) [0|65535] "bitmask"  MASTER,NODE1,NODE2,NODE3,NODE4,NODE5,NODE6,NODE7,NODE8,NODE9,NODE10,NODE11,NODE12,NODE13,NODE14,NODE15,NODE16,TOOL
 SG_ seq : 48|8@1+ (1,0) [0|255] ""  MASTER,NODE1,NODE2,NODE3,NODE4,NODE5,NODE6,NODE7,NODE8,NODE9,NODE10,NODE11,NODE12,NODE13,NODE14,NODE15,NODE16,TOOL
 SG_ reserved : 56|8@1+ (1,0) [0|255] ""  MASTER,NODE1,NODE2,NODE3,NODE4,NODE5,NODE6,NODE7,NODE8,NODE9,NODE10,NODE11,NODE12,NODE13,NODE14,NODE15,NODE16,TOOL

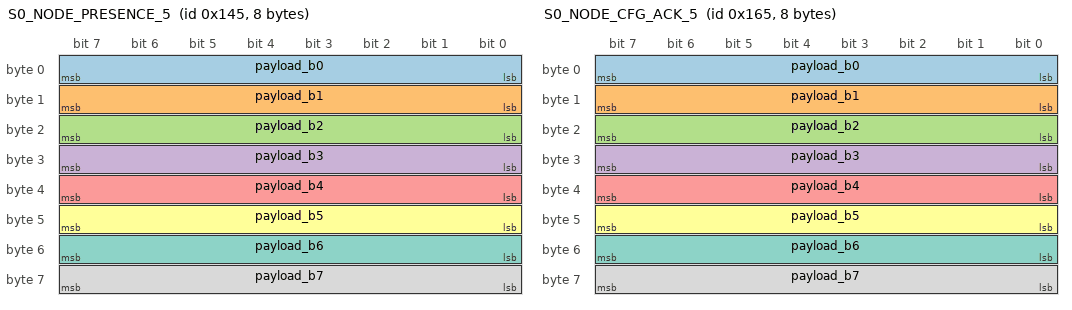
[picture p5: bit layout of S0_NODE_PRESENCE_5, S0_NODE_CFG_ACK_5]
BO_ 325 S0_NODE_PRESENCE_5: 8 NODE5
 SG_ payload_b0 : 0|8@1+ (1,0) [0|255] "raw"  MASTER,NODE1,NODE2,NODE3,NODE4,NODE5,NODE6,NODE7,NODE8,NODE9,NODE10,NODE11,NODE12,NODE13,NODE14,NODE15,NODE16,TOOL
 SG_ payload_b1 : 8|8@1+ (1,0) [0|255] "raw"  MASTER,NODE1,NODE2,NODE3,NODE4,NODE5,NODE6,NODE7,NODE8,NODE9,NODE10,NODE11,NODE12,NODE13,NODE14,NODE15,NODE16,TOOL
 SG_ payload_b2 : 16|8@1+ (1,0) [0|255] "raw"  MASTER,NODE1,NODE2,NODE3,NODE4,NODE5,NODE6,NODE7,NODE8,NODE9,NODE10,NODE11,NODE12,NODE13,NODE14,NODE15,NODE16,TOOL
 SG_ payload_b3 : 24|8@1+ (1,0) [0|255] "raw"  MASTER,NODE1,NODE2,NODE3,NODE4,NODE5,NODE6,NODE7,NODE8,NODE9,NODE10,NODE11,NODE12,NODE13,NODE14,NODE15,NODE16,TOOL
 SG_ payload_b4 : 32|8@1+ (1,0) [0|255] "raw"  MASTER,NODE1,NODE2,NODE3,NODE4,NODE5,NODE6,NODE7,NODE8,NODE9,NODE10,NODE11,NODE12,NODE13,NODE14,NODE15,NODE16,TOOL
 SG_ payload_b5 : 40|8@1+ (1,0) [0|255] "raw"  MASTER,NODE1,NODE2,NODE3,NODE4,NODE5,NODE6,NODE7,NODE8,NODE9,NODE10,NODE11,NODE12,NODE13,NODE14,NODE15,NODE16,TOOL
 SG_ payload_b6 : 48|8@1+ (1,0) [0|255] "raw"  MASTER,NODE1,NODE2,NODE3,NODE4,NODE5,NODE6,NODE7,NODE8,NODE9,NODE10,NODE11,NODE12,NODE13,NODE14,NODE15,NODE16,TOOL
 SG_ payload_b7 : 56|8@1+ (1,0) [0|255] "raw"  MASTER,NODE1,NODE2,NODE3,NODE4,NODE5,NODE6,NODE7,NODE8,NODE9,NODE10,NODE11,NODE12,NODE13,NODE14,NODE15,NODE16,TOOL

BO_ 357 S0_NODE_CFG_ACK_5: 8 NODE5
 SG_ payload_b0 : 0|8@1+ (1,0) [0|255] "raw"  MASTER,NODE1,NODE2,NODE3,NODE4,NODE5,NODE6,NODE7,NODE8,NODE9,NODE10,NODE11,NODE12,NODE13,NODE14,NODE15,NODE16,TOOL
 SG_ payload_b1 : 8|8@1+ (1,0) [0|255] "raw"  MASTER,NODE1,NODE2,NODE3,NODE4,NODE5,NODE6,NODE7,NODE8,NODE9,NODE10,NODE11,NODE12,NODE13,NODE14,NODE15,NODE16,TOOL
 SG_ payload_b2 : 16|8@1+ (1,0) [0|255] "raw"  MASTER,NODE1,NODE2,NODE3,NODE4,NODE5,NODE6,NODE7,NODE8,NODE9,NODE10,NODE11,NODE12,NODE13,NODE14,NODE15,NODE16,TOOL
 SG_ payload_b3 : 24|8@1+ (1,0) [0|255] "raw"  MASTER,NODE1,NODE2,NODE3,NODE4,NODE5,NODE6,NODE7,NODE8,NODE9,NODE10,NODE11,NODE12,NODE13,NODE14,NODE15,NODE16,TOOL
 SG_ payload_b4 : 32|8@1+ (1,0) [0|255] "raw"  MASTER,NODE1,NODE2,NODE3,NODE4,NODE5,NODE6,NODE7,NODE8,NODE9,NODE10,NODE11,NODE12,NODE13,NODE14,NODE15,NODE16,TOOL
 SG_ payload_b5 : 40|8@1+ (1,0) [0|255] "raw"  MASTER,NODE1,NODE2,NODE3,NODE4,NODE5,NODE6,NODE7,NODE8,NODE9,NODE10,NODE11,NODE12,NODE13,NODE14,NODE15,NODE16,TOOL
 SG_ payload_b6 : 48|8@1+ (1,0) [0|255] "raw"  MASTER,NODE1,NODE2,NODE3,NODE4,NODE5,NODE6,NODE7,NODE8,NODE9,NODE10,NODE11,NODE12,NODE13,NODE14,NODE15,NODE16,TOOL
 SG_ payload_b7 : 56|8@1+ (1,0) [0|255] "raw"  MASTER,NODE1,NODE2,NODE3,NODE4,NODE5,NODE6,NODE7,NODE8,NODE9,NODE10,NODE11,NODE12,NODE13,NODE14,NODE15,NODE16,TOOL

BO_ 389 S0_NODE_STATUS_FAST_5: 8 NODE5
 SG_ status_flags : 0|8@1+ (1,0) [0|255] "bitfield"  MASTER,NODE1,NODE2,NODE3,NODE4,NODE5,NODE6,NODE7,NODE8,NODE9,NODE10,NODE11,NODE12,NODE13,NODE14,NODE15,NODE16,TOOL
 SG_ error_code : 8|8@1+ (1,0) [0|255] ""  MASTER,NODE1,NODE2,NODE3,NODE4,NODE5,NODE6,NODE7,NODE8,NODE9,NODE10,NODE11,NODE12,NODE13,NODE14,NODE15,NODE16,TOOL
 SG_ actual_rpm : 16|16@1- (0.1,0) [-3276.8|3276.7] "rpm"  MASTER,NODE1,NODE2,NODE3,NODE4,NODE5,NODE6,NODE7,NODE8,NODE9,NODE10,NODE11,NODE12,NODE13,NODE14,NODE15,NODE16,TOOL
 SG_ actual_pos : 32|16@1+ (1.52587890625e-05,0) [0|0.9999847412109375] "rev"  MASTER,NODE1,NODE2,NODE3,NODE4,NODE5,NODE6,NODE7,NODE8,NODE9,NODE10,NODE11,NODE12,NODE13,NODE14,NODE15,NODE16,TOOL
 SG_ alive_counter : 48|8@1+ (1,0) [0|255] ""  MASTER,NODE1,NODE2,NODE3,NODE4,NODE5,NODE6,NODE7,NODE8,NODE9,NODE10,NODE11,NODE12,NODE13,NODE14,NODE15,NODE16,TOOL
 SG_ sync_error : 56|8@1- (0.00390625,0) [-0.5|0.49609375] "rev"  MASTER,NODE1,NODE2,NODE3,NODE4,NODE5,NODE6,NODE7,NODE8,NODE9,NODE10,NODE11,NODE12,NODE13,NODE14,NODE15,NODE16,TOOL

BO_ 453 S0_NODE_DIAG_5: 8 NODE5
 SG_ bus_voltage : 0|16@1+ (0.1,0) [0|6553.5] "V"  MASTER,NODE1,NODE2,NODE3,NODE4,NODE5,NODE6,NODE7,NODE8,NODE9,NODE10,NODE11,NODE12,NODE13,NODE14,NODE15,NODE16,TOOL
 SG_ motor_current : 16|16@1- (0.1,0) [-3276.8|3276.7] "A"  MASTER,NODE1,NODE2,NODE3,NODE4,NODE5,NODE6,NODE7,NODE8,NODE9,NODE10,NODE11,NODE12,NODE13,NODE14,NODE15,NODE16,TOOL
 SG_ controller_temp : 32|8@1- (1,0) [-128|127] "degC"  MASTER,NODE1,NODE2,NODE3,NODE4,NODE5,NODE6,NODE7,NODE8,NODE9,NODE10,NODE11,NODE12,NODE13,NODE14,NODE15,NODE16,TOOL
 SG_ motor_temp : 40|8@1- (1,0) [-128|127] "degC"  MASTER,NODE1,NODE2,NODE3,NODE4,NODE5,NODE6,NODE7,NODE8,NODE9,NODE10,NODE11,NODE12,NODE13,NODE14,NODE15,NODE16,TOOL
 SG_ fault_flags : 48|8@1+ (1,0) [0|255] "bitfield"  MASTER,NODE1,NODE2,NODE3,NODE4,NODE5,NODE6,NODE7,NODE8,NODE9,NODE10,NODE11,NODE12,NODE13,NODE14,NODE15,NODE16,TOOL
 SG_ warning_flags : 56|8@1+ (1,0) [0|255] "bitfield"  MASTER,NODE1,NODE2,NODE3,NODE4,NODE5,NODE6,NODE7,NODE8,NODE9,NODE10,NODE11,NODE12,NODE13,NODE14,NODE15,NODE16,TOOL

BO_ 262 S0_NODE_CMD_6: 8 MASTER
 SG_ node_command : 0|8@1+ (1,0) [0|255] ""  MASTER,NODE1,NODE2,NODE3,NODE4,NODE5,NODE6,NODE7,NODE8,NODE9,NODE10,NODE11,NODE12,NODE13,NODE14,NODE15,NODE16,TOOL
 SG_ node_flags : 8|8@1+ (1,0) [0|255] "bitfield"  MASTER,NODE1,NODE2,NODE3,NODE4,NODE5,NODE6,NODE7,NODE8,NODE9,NODE10,NODE11,NODE12,NODE13,NODE14,NODE15,NODE16,TOOL
 SG_ trim_rpm : 16|16@1- (0.1,0) [-3276.8|3276.7] "rpm"  MASTER,NODE1,NODE2,NODE3,NODE4,NODE5,NODE6,NODE7,NODE8,NODE9,NODE10,NODE11,NODE12,NODE13,NODE14,NODE15,NODE16,TOOL
 SG_ section_mask : 32|16@1+ (1,0) [0|65535] "bitmask"  MASTER,NODE1,NODE2,NODE3,NODE4,NODE5,NODE6,NODE7,NODE8,NODE9,NODE10,NODE11,NODE12,NODE13,NODE14,NODE15,NODE16,TOOL
 SG_ seq : 48|8@1+ (1,0) [0|255] ""  MASTER,NODE1,NODE2,NODE3,NODE4,NODE5,NODE6,NODE7,NODE8,NODE9,NODE10,NODE11,NODE12,NODE13,NODE14,NODE15,NODE16,TOOL
 SG_ reserved : 56|8@1+ (1,0) [0|255] ""  MASTER,NODE1,NODE2,NODE3,NODE4,NODE5,NODE6,NODE7,NODE8,NODE9,NODE10,NODE11,NODE12,NODE13,NODE14,NODE15,NODE16,TOOL

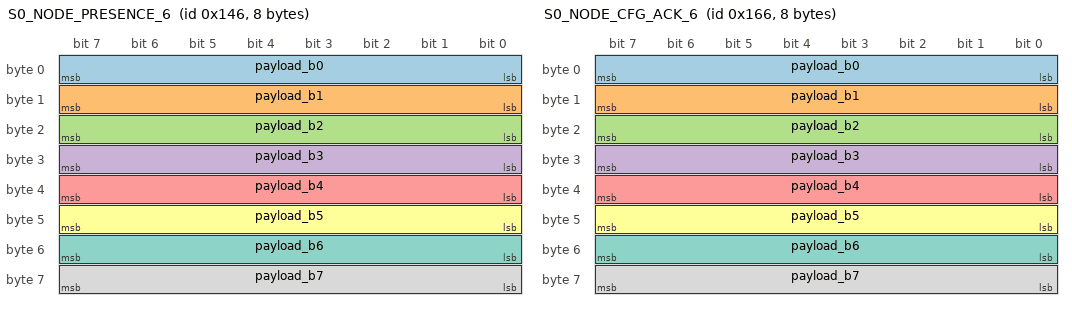
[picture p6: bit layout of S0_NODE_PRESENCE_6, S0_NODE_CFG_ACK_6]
BO_ 326 S0_NODE_PRESENCE_6: 8 NODE6
 SG_ payload_b0 : 0|8@1+ (1,0) [0|255] "raw"  MASTER,NODE1,NODE2,NODE3,NODE4,NODE5,NODE6,NODE7,NODE8,NODE9,NODE10,NODE11,NODE12,NODE13,NODE14,NODE15,NODE16,TOOL
 SG_ payload_b1 : 8|8@1+ (1,0) [0|255] "raw"  MASTER,NODE1,NODE2,NODE3,NODE4,NODE5,NODE6,NODE7,NODE8,NODE9,NODE10,NODE11,NODE12,NODE13,NODE14,NODE15,NODE16,TOOL
 SG_ payload_b2 : 16|8@1+ (1,0) [0|255] "raw"  MASTER,NODE1,NODE2,NODE3,NODE4,NODE5,NODE6,NODE7,NODE8,NODE9,NODE10,NODE11,NODE12,NODE13,NODE14,NODE15,NODE16,TOOL
 SG_ payload_b3 : 24|8@1+ (1,0) [0|255] "raw"  MASTER,NODE1,NODE2,NODE3,NODE4,NODE5,NODE6,NODE7,NODE8,NODE9,NODE10,NODE11,NODE12,NODE13,NODE14,NODE15,NODE16,TOOL
 SG_ payload_b4 : 32|8@1+ (1,0) [0|255] "raw"  MASTER,NODE1,NODE2,NODE3,NODE4,NODE5,NODE6,NODE7,NODE8,NODE9,NODE10,NODE11,NODE12,NODE13,NODE14,NODE15,NODE16,TOOL
 SG_ payload_b5 : 40|8@1+ (1,0) [0|255] "raw"  MASTER,NODE1,NODE2,NODE3,NODE4,NODE5,NODE6,NODE7,NODE8,NODE9,NODE10,NODE11,NODE12,NODE13,NODE14,NODE15,NODE16,TOOL
 SG_ payload_b6 : 48|8@1+ (1,0) [0|255] "raw"  MASTER,NODE1,NODE2,NODE3,NODE4,NODE5,NODE6,NODE7,NODE8,NODE9,NODE10,NODE11,NODE12,NODE13,NODE14,NODE15,NODE16,TOOL
 SG_ payload_b7 : 56|8@1+ (1,0) [0|255] "raw"  MASTER,NODE1,NODE2,NODE3,NODE4,NODE5,NODE6,NODE7,NODE8,NODE9,NODE10,NODE11,NODE12,NODE13,NODE14,NODE15,NODE16,TOOL

BO_ 358 S0_NODE_CFG_ACK_6: 8 NODE6
 SG_ payload_b0 : 0|8@1+ (1,0) [0|255] "raw"  MASTER,NODE1,NODE2,NODE3,NODE4,NODE5,NODE6,NODE7,NODE8,NODE9,NODE10,NODE11,NODE12,NODE13,NODE14,NODE15,NODE16,TOOL
 SG_ payload_b1 : 8|8@1+ (1,0) [0|255] "raw"  MASTER,NODE1,NODE2,NODE3,NODE4,NODE5,NODE6,NODE7,NODE8,NODE9,NODE10,NODE11,NODE12,NODE13,NODE14,NODE15,NODE16,TOOL
 SG_ payload_b2 : 16|8@1+ (1,0) [0|255] "raw"  MASTER,NODE1,NODE2,NODE3,NODE4,NODE5,NODE6,NODE7,NODE8,NODE9,NODE10,NODE11,NODE12,NODE13,NODE14,NODE15,NODE16,TOOL
 SG_ payload_b3 : 24|8@1+ (1,0) [0|255] "raw"  MASTER,NODE1,NODE2,NODE3,NODE4,NODE5,NODE6,NODE7,NODE8,NODE9,NODE10,NODE11,NODE12,NODE13,NODE14,NODE15,NODE16,TOOL
 SG_ payload_b4 : 32|8@1+ (1,0) [0|255] "raw"  MASTER,NODE1,NODE2,NODE3,NODE4,NODE5,NODE6,NODE7,NODE8,NODE9,NODE10,NODE11,NODE12,NODE13,NODE14,NODE15,NODE16,TOOL
 SG_ payload_b5 : 40|8@1+ (1,0) [0|255] "raw"  MASTER,NODE1,NODE2,NODE3,NODE4,NODE5,NODE6,NODE7,NODE8,NODE9,NODE10,NODE11,NODE12,NODE13,NODE14,NODE15,NODE16,TOOL
 SG_ payload_b6 : 48|8@1+ (1,0) [0|255] "raw"  MASTER,NODE1,NODE2,NODE3,NODE4,NODE5,NODE6,NODE7,NODE8,NODE9,NODE10,NODE11,NODE12,NODE13,NODE14,NODE15,NODE16,TOOL
 SG_ payload_b7 : 56|8@1+ (1,0) [0|255] "raw"  MASTER,NODE1,NODE2,NODE3,NODE4,NODE5,NODE6,NODE7,NODE8,NODE9,NODE10,NODE11,NODE12,NODE13,NODE14,NODE15,NODE16,TOOL

BO_ 390 S0_NODE_STATUS_FAST_6: 8 NODE6
 SG_ status_flags : 0|8@1+ (1,0) [0|255] "bitfield"  MASTER,NODE1,NODE2,NODE3,NODE4,NODE5,NODE6,NODE7,NODE8,NODE9,NODE10,NODE11,NODE12,NODE13,NODE14,NODE15,NODE16,TOOL
 SG_ error_code : 8|8@1+ (1,0) [0|255] ""  MASTER,NODE1,NODE2,NODE3,NODE4,NODE5,NODE6,NODE7,NODE8,NODE9,NODE10,NODE11,NODE12,NODE13,NODE14,NODE15,NODE16,TOOL
 SG_ actual_rpm : 16|16@1- (0.1,0) [-3276.8|3276.7] "rpm"  MASTER,NODE1,NODE2,NODE3,NODE4,NODE5,NODE6,NODE7,NODE8,NODE9,NODE10,NODE11,NODE12,NODE13,NODE14,NODE15,NODE16,TOOL
 SG_ actual_pos : 32|16@1+ (1.52587890625e-05,0) [0|0.9999847412109375] "rev"  MASTER,NODE1,NODE2,NODE3,NODE4,NODE5,NODE6,NODE7,NODE8,NODE9,NODE10,NODE11,NODE12,NODE13,NODE14,NODE15,NODE16,TOOL
 SG_ alive_counter : 48|8@1+ (1,0) [0|255] ""  MASTER,NODE1,NODE2,NODE3,NODE4,NODE5,NODE6,NODE7,NODE8,NODE9,NODE10,NODE11,NODE12,NODE13,NODE14,NODE15,NODE16,TOOL
 SG_ sync_error : 56|8@1- (0.00390625,0) [-0.5|0.49609375] "rev"  MASTER,NODE1,NODE2,NODE3,NODE4,NODE5,NODE6,NODE7,NODE8,NODE9,NODE10,NODE11,NODE12,NODE13,NODE14,NODE15,NODE16,TOOL

BO_ 454 S0_NODE_DIAG_6: 8 NODE6
 SG_ bus_voltage : 0|16@1+ (0.1,0) [0|6553.5] "V"  MASTER,NODE1,NODE2,NODE3,NODE4,NODE5,NODE6,NODE7,NODE8,NODE9,NODE10,NODE11,NODE12,NODE13,NODE14,NODE15,NODE16,TOOL
 SG_ motor_current : 16|16@1- (0.1,0) [-3276.8|3276.7] "A"  MASTER,NODE1,NODE2,NODE3,NODE4,NODE5,NODE6,NODE7,NODE8,NODE9,NODE10,NODE11,NODE12,NODE13,NODE14,NODE15,NODE16,TOOL
 SG_ controller_temp : 32|8@1- (1,0) [-128|127] "degC"  MASTER,NODE1,NODE2,NODE3,NODE4,NODE5,NODE6,NODE7,NODE8,NODE9,NODE10,NODE11,NODE12,NODE13,NODE14,NODE15,NODE16,TOOL
 SG_ motor_temp : 40|8@1- (1,0) [-128|127] "degC"  MASTER,NODE1,NODE2,NODE3,NODE4,NODE5,NODE6,NODE7,NODE8,NODE9,NODE10,NODE11,NODE12,NODE13,NODE14,NODE15,NODE16,TOOL
 SG_ fault_flags : 48|8@1+ (1,0) [0|255] "bitfield"  MASTER,NODE1,NODE2,NODE3,NODE4,NODE5,NODE6,NODE7,NODE8,NODE9,NODE10,NODE11,NODE12,NODE13,NODE14,NODE15,NODE16,TOOL
 SG_ warning_flags : 56|8@1+ (1,0) [0|255] "bitfield"  MASTER,NODE1,NODE2,NODE3,NODE4,NODE5,NODE6,NODE7,NODE8,NODE9,NODE10,NODE11,NODE12,NODE13,NODE14,NODE15,NODE16,TOOL

BO_ 263 S0_NODE_CMD_7: 8 MASTER
 SG_ node_command : 0|8@1+ (1,0) [0|255] ""  MASTER,NODE1,NODE2,NODE3,NODE4,NODE5,NODE6,NODE7,NODE8,NODE9,NODE10,NODE11,NODE12,NODE13,NODE14,NODE15,NODE16,TOOL
 SG_ node_flags : 8|8@1+ (1,0) [0|255] "bitfield"  MASTER,NODE1,NODE2,NODE3,NODE4,NODE5,NODE6,NODE7,NODE8,NODE9,NODE10,NODE11,NODE12,NODE13,NODE14,NODE15,NODE16,TOOL
 SG_ trim_rpm : 16|16@1- (0.1,0) [-3276.8|3276.7] "rpm"  MASTER,NODE1,NODE2,NODE3,NODE4,NODE5,NODE6,NODE7,NODE8,NODE9,NODE10,NODE11,NODE12,NODE13,NODE14,NODE15,NODE16,TOOL
 SG_ section_mask : 32|16@1+ (1,0) [0|65535] "bitmask"  MASTER,NODE1,NODE2,NODE3,NODE4,NODE5,NODE6,NODE7,NODE8,NODE9,NODE10,NODE11,NODE12,NODE13,NODE14,NODE15,NODE16,TOOL
 SG_ seq : 48|8@1+ (1,0) [0|255] ""  MASTER,NODE1,NODE2,NODE3,NODE4,NODE5,NODE6,NODE7,NODE8,NODE9,NODE10,NODE11,NODE12,NODE13,NODE14,NODE15,NODE16,TOOL
 SG_ reserved : 56|8@1+ (1,0) [0|255] ""  MASTER,NODE1,NODE2,NODE3,NODE4,NODE5,NODE6,NODE7,NODE8,NODE9,NODE10,NODE11,NODE12,NODE13,NODE14,NODE15,NODE16,TOOL

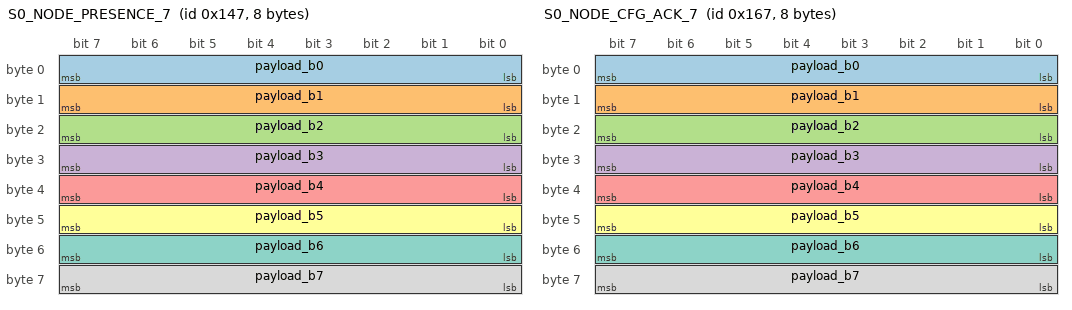
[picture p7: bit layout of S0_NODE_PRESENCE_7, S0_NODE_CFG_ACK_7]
BO_ 327 S0_NODE_PRESENCE_7: 8 NODE7
 SG_ payload_b0 : 0|8@1+ (1,0) [0|255] "raw"  MASTER,NODE1,NODE2,NODE3,NODE4,NODE5,NODE6,NODE7,NODE8,NODE9,NODE10,NODE11,NODE12,NODE13,NODE14,NODE15,NODE16,TOOL
 SG_ payload_b1 : 8|8@1+ (1,0) [0|255] "raw"  MASTER,NODE1,NODE2,NODE3,NODE4,NODE5,NODE6,NODE7,NODE8,NODE9,NODE10,NODE11,NODE12,NODE13,NODE14,NODE15,NODE16,TOOL
 SG_ payload_b2 : 16|8@1+ (1,0) [0|255] "raw"  MASTER,NODE1,NODE2,NODE3,NODE4,NODE5,NODE6,NODE7,NODE8,NODE9,NODE10,NODE11,NODE12,NODE13,NODE14,NODE15,NODE16,TOOL
 SG_ payload_b3 : 24|8@1+ (1,0) [0|255] "raw"  MASTER,NODE1,NODE2,NODE3,NODE4,NODE5,NODE6,NODE7,NODE8,NODE9,NODE10,NODE11,NODE12,NODE13,NODE14,NODE15,NODE16,TOOL
 SG_ payload_b4 : 32|8@1+ (1,0) [0|255] "raw"  MASTER,NODE1,NODE2,NODE3,NODE4,NODE5,NODE6,NODE7,NODE8,NODE9,NODE10,NODE11,NODE12,NODE13,NODE14,NODE15,NODE16,TOOL
 SG_ payload_b5 : 40|8@1+ (1,0) [0|255] "raw"  MASTER,NODE1,NODE2,NODE3,NODE4,NODE5,NODE6,NODE7,NODE8,NODE9,NODE10,NODE11,NODE12,NODE13,NODE14,NODE15,NODE16,TOOL
 SG_ payload_b6 : 48|8@1+ (1,0) [0|255] "raw"  MASTER,NODE1,NODE2,NODE3,NODE4,NODE5,NODE6,NODE7,NODE8,NODE9,NODE10,NODE11,NODE12,NODE13,NODE14,NODE15,NODE16,TOOL
 SG_ payload_b7 : 56|8@1+ (1,0) [0|255] "raw"  MASTER,NODE1,NODE2,NODE3,NODE4,NODE5,NODE6,NODE7,NODE8,NODE9,NODE10,NODE11,NODE12,NODE13,NODE14,NODE15,NODE16,TOOL

BO_ 359 S0_NODE_CFG_ACK_7: 8 NODE7
 SG_ payload_b0 : 0|8@1+ (1,0) [0|255] "raw"  MASTER,NODE1,NODE2,NODE3,NODE4,NODE5,NODE6,NODE7,NODE8,NODE9,NODE10,NODE11,NODE12,NODE13,NODE14,NODE15,NODE16,TOOL
 SG_ payload_b1 : 8|8@1+ (1,0) [0|255] "raw"  MASTER,NODE1,NODE2,NODE3,NODE4,NODE5,NODE6,NODE7,NODE8,NODE9,NODE10,NODE11,NODE12,NODE13,NODE14,NODE15,NODE16,TOOL
 SG_ payload_b2 : 16|8@1+ (1,0) [0|255] "raw"  MASTER,NODE1,NODE2,NODE3,NODE4,NODE5,NODE6,NODE7,NODE8,NODE9,NODE10,NODE11,NODE12,NODE13,NODE14,NODE15,NODE16,TOOL
 SG_ payload_b3 : 24|8@1+ (1,0) [0|255] "raw"  MASTER,NODE1,NODE2,NODE3,NODE4,NODE5,NODE6,NODE7,NODE8,NODE9,NODE10,NODE11,NODE12,NODE13,NODE14,NODE15,NODE16,TOOL
 SG_ payload_b4 : 32|8@1+ (1,0) [0|255] "raw"  MASTER,NODE1,NODE2,NODE3,NODE4,NODE5,NODE6,NODE7,NODE8,NODE9,NODE10,NODE11,NODE12,NODE13,NODE14,NODE15,NODE16,TOOL
 SG_ payload_b5 : 40|8@1+ (1,0) [0|255] "raw"  MASTER,NODE1,NODE2,NODE3,NODE4,NODE5,NODE6,NODE7,NODE8,NODE9,NODE10,NODE11,NODE12,NODE13,NODE14,NODE15,NODE16,TOOL
 SG_ payload_b6 : 48|8@1+ (1,0) [0|255] "raw"  MASTER,NODE1,NODE2,NODE3,NODE4,NODE5,NODE6,NODE7,NODE8,NODE9,NODE10,NODE11,NODE12,NODE13,NODE14,NODE15,NODE16,TOOL
 SG_ payload_b7 : 56|8@1+ (1,0) [0|255] "raw"  MASTER,NODE1,NODE2,NODE3,NODE4,NODE5,NODE6,NODE7,NODE8,NODE9,NODE10,NODE11,NODE12,NODE13,NODE14,NODE15,NODE16,TOOL

BO_ 391 S0_NODE_STATUS_FAST_7: 8 NODE7
 SG_ status_flags : 0|8@1+ (1,0) [0|255] "bitfield"  MASTER,NODE1,NODE2,NODE3,NODE4,NODE5,NODE6,NODE7,NODE8,NODE9,NODE10,NODE11,NODE12,NODE13,NODE14,NODE15,NODE16,TOOL
 SG_ error_code : 8|8@1+ (1,0) [0|255] ""  MASTER,NODE1,NODE2,NODE3,NODE4,NODE5,NODE6,NODE7,NODE8,NODE9,NODE10,NODE11,NODE12,NODE13,NODE14,NODE15,NODE16,TOOL
 SG_ actual_rpm : 16|16@1- (0.1,0) [-3276.8|3276.7] "rpm"  MASTER,NODE1,NODE2,NODE3,NODE4,NODE5,NODE6,NODE7,NODE8,NODE9,NODE10,NODE11,NODE12,NODE13,NODE14,NODE15,NODE16,TOOL
 SG_ actual_pos : 32|16@1+ (1.52587890625e-05,0) [0|0.9999847412109375] "rev"  MASTER,NODE1,NODE2,NODE3,NODE4,NODE5,NODE6,NODE7,NODE8,NODE9,NODE10,NODE11,NODE12,NODE13,NODE14,NODE15,NODE16,TOOL
 SG_ alive_counter : 48|8@1+ (1,0) [0|255] ""  MASTER,NODE1,NODE2,NODE3,NODE4,NODE5,NODE6,NODE7,NODE8,NODE9,NODE10,NODE11,NODE12,NODE13,NODE14,NODE15,NODE16,TOOL
 SG_ sync_error : 56|8@1- (0.00390625,0) [-0.5|0.49609375] "rev"  MASTER,NODE1,NODE2,NODE3,NODE4,NODE5,NODE6,NODE7,NODE8,NODE9,NODE10,NODE11,NODE12,NODE13,NODE14,NODE15,NODE16,TOOL

BO_ 455 S0_NODE_DIAG_7: 8 NODE7
 SG_ bus_voltage : 0|16@1+ (0.1,0) [0|6553.5] "V"  MASTER,NODE1,NODE2,NODE3,NODE4,NODE5,NODE6,NODE7,NODE8,NODE9,NODE10,NODE11,NODE12,NODE13,NODE14,NODE15,NODE16,TOOL
 SG_ motor_current : 16|16@1- (0.1,0) [-3276.8|3276.7] "A"  MASTER,NODE1,NODE2,NODE3,NODE4,NODE5,NODE6,NODE7,NODE8,NODE9,NODE10,NODE11,NODE12,NODE13,NODE14,NODE15,NODE16,TOOL
 SG_ controller_temp : 32|8@1- (1,0) [-128|127] "degC"  MASTER,NODE1,NODE2,NODE3,NODE4,NODE5,NODE6,NODE7,NODE8,NODE9,NODE10,NODE11,NODE12,NODE13,NODE14,NODE15,NODE16,TOOL
 SG_ motor_temp : 40|8@1- (1,0) [-128|127] "degC"  MASTER,NODE1,NODE2,NODE3,NODE4,NODE5,NODE6,NODE7,NODE8,NODE9,NODE10,NODE11,NODE12,NODE13,NODE14,NODE15,NODE16,TOOL
 SG_ fault_flags : 48|8@1+ (1,0) [0|255] "bitfield"  MASTER,NODE1,NODE2,NODE3,NODE4,NODE5,NODE6,NODE7,NODE8,NODE9,NODE10,NODE11,NODE12,NODE13,NODE14,NODE15,NODE16,TOOL
 SG_ warning_flags : 56|8@1+ (1,0) [0|255] "bitfield"  MASTER,NODE1,NODE2,NODE3,NODE4,NODE5,NODE6,NODE7,NODE8,NODE9,NODE10,NODE11,NODE12,NODE13,NODE14,NODE15,NODE16,TOOL

BO_ 264 S0_NODE_CMD_8: 8 MASTER
 SG_ node_command : 0|8@1+ (1,0) [0|255] ""  MASTER,NODE1,NODE2,NODE3,NODE4,NODE5,NODE6,NODE7,NODE8,NODE9,NODE10,NODE11,NODE12,NODE13,NODE14,NODE15,NODE16,TOOL
 SG_ node_flags : 8|8@1+ (1,0) [0|255] "bitfield"  MASTER,NODE1,NODE2,NODE3,NODE4,NODE5,NODE6,NODE7,NODE8,NODE9,NODE10,NODE11,NODE12,NODE13,NODE14,NODE15,NODE16,TOOL
 SG_ trim_rpm : 16|16@1- (0.1,0) [-3276.8|3276.7] "rpm"  MASTER,NODE1,NODE2,NODE3,NODE4,NODE5,NODE6,NODE7,NODE8,NODE9,NODE10,NODE11,NODE12,NODE13,NODE14,NODE15,NODE16,TOOL
 SG_ section_mask : 32|16@1+ (1,0) [0|65535] "bitmask"  MASTER,NODE1,NODE2,NODE3,NODE4,NODE5,NODE6,NODE7,NODE8,NODE9,NODE10,NODE11,NODE12,NODE13,NODE14,NODE15,NODE16,TOOL
 SG_ seq : 48|8@1+ (1,0) [0|255] ""  MASTER,NODE1,NODE2,NODE3,NODE4,NODE5,NODE6,NODE7,NODE8,NODE9,NODE10,NODE11,NODE12,NODE13,NODE14,NODE15,NODE16,TOOL
 SG_ reserved : 56|8@1+ (1,0) [0|255] ""  MASTER,NODE1,NODE2,NODE3,NODE4,NODE5,NODE6,NODE7,NODE8,NODE9,NODE10,NODE11,NODE12,NODE13,NODE14,NODE15,NODE16,TOOL

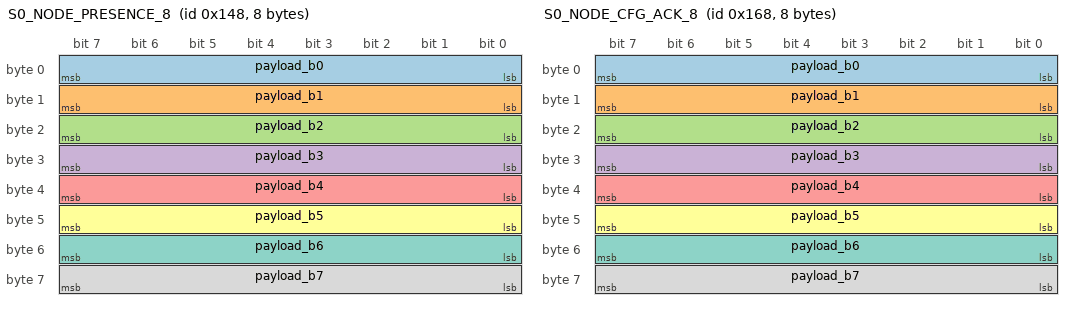
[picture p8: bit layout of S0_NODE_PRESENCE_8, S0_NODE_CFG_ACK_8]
BO_ 328 S0_NODE_PRESENCE_8: 8 NODE8
 SG_ payload_b0 : 0|8@1+ (1,0) [0|255] "raw"  MASTER,NODE1,NODE2,NODE3,NODE4,NODE5,NODE6,NODE7,NODE8,NODE9,NODE10,NODE11,NODE12,NODE13,NODE14,NODE15,NODE16,TOOL
 SG_ payload_b1 : 8|8@1+ (1,0) [0|255] "raw"  MASTER,NODE1,NODE2,NODE3,NODE4,NODE5,NODE6,NODE7,NODE8,NODE9,NODE10,NODE11,NODE12,NODE13,NODE14,NODE15,NODE16,TOOL
 SG_ payload_b2 : 16|8@1+ (1,0) [0|255] "raw"  MASTER,NODE1,NODE2,NODE3,NODE4,NODE5,NODE6,NODE7,NODE8,NODE9,NODE10,NODE11,NODE12,NODE13,NODE14,NODE15,NODE16,TOOL
 SG_ payload_b3 : 24|8@1+ (1,0) [0|255] "raw"  MASTER,NODE1,NODE2,NODE3,NODE4,NODE5,NODE6,NODE7,NODE8,NODE9,NODE10,NODE11,NODE12,NODE13,NODE14,NODE15,NODE16,TOOL
 SG_ payload_b4 : 32|8@1+ (1,0) [0|255] "raw"  MASTER,NODE1,NODE2,NODE3,NODE4,NODE5,NODE6,NODE7,NODE8,NODE9,NODE10,NODE11,NODE12,NODE13,NODE14,NODE15,NODE16,TOOL
 SG_ payload_b5 : 40|8@1+ (1,0) [0|255] "raw"  MASTER,NODE1,NODE2,NODE3,NODE4,NODE5,NODE6,NODE7,NODE8,NODE9,NODE10,NODE11,NODE12,NODE13,NODE14,NODE15,NODE16,TOOL
 SG_ payload_b6 : 48|8@1+ (1,0) [0|255] "raw"  MASTER,NODE1,NODE2,NODE3,NODE4,NODE5,NODE6,NODE7,NODE8,NODE9,NODE10,NODE11,NODE12,NODE13,NODE14,NODE15,NODE16,TOOL
 SG_ payload_b7 : 56|8@1+ (1,0) [0|255] "raw"  MASTER,NODE1,NODE2,NODE3,NODE4,NODE5,NODE6,NODE7,NODE8,NODE9,NODE10,NODE11,NODE12,NODE13,NODE14,NODE15,NODE16,TOOL

BO_ 360 S0_NODE_CFG_ACK_8: 8 NODE8
 SG_ payload_b0 : 0|8@1+ (1,0) [0|255] "raw"  MASTER,NODE1,NODE2,NODE3,NODE4,NODE5,NODE6,NODE7,NODE8,NODE9,NODE10,NODE11,NODE12,NODE13,NODE14,NODE15,NODE16,TOOL
 SG_ payload_b1 : 8|8@1+ (1,0) [0|255] "raw"  MASTER,NODE1,NODE2,NODE3,NODE4,NODE5,NODE6,NODE7,NODE8,NODE9,NODE10,NODE11,NODE12,NODE13,NODE14,NODE15,NODE16,TOOL
 SG_ payload_b2 : 16|8@1+ (1,0) [0|255] "raw"  MASTER,NODE1,NODE2,NODE3,NODE4,NODE5,NODE6,NODE7,NODE8,NODE9,NODE10,NODE11,NODE12,NODE13,NODE14,NODE15,NODE16,TOOL
 SG_ payload_b3 : 24|8@1+ (1,0) [0|255] "raw"  MASTER,NODE1,NODE2,NODE3,NODE4,NODE5,NODE6,NODE7,NODE8,NODE9,NODE10,NODE11,NODE12,NODE13,NODE14,NODE15,NODE16,TOOL
 SG_ payload_b4 : 32|8@1+ (1,0) [0|255] "raw"  MASTER,NODE1,NODE2,NODE3,NODE4,NODE5,NODE6,NODE7,NODE8,NODE9,NODE10,NODE11,NODE12,NODE13,NODE14,NODE15,NODE16,TOOL
 SG_ payload_b5 : 40|8@1+ (1,0) [0|255] "raw"  MASTER,NODE1,NODE2,NODE3,NODE4,NODE5,NODE6,NODE7,NODE8,NODE9,NODE10,NODE11,NODE12,NODE13,NODE14,NODE15,NODE16,TOOL
 SG_ payload_b6 : 48|8@1+ (1,0) [0|255] "raw"  MASTER,NODE1,NODE2,NODE3,NODE4,NODE5,NODE6,NODE7,NODE8,NODE9,NODE10,NODE11,NODE12,NODE13,NODE14,NODE15,NODE16,TOOL
 SG_ payload_b7 : 56|8@1+ (1,0) [0|255] "raw"  MASTER,NODE1,NODE2,NODE3,NODE4,NODE5,NODE6,NODE7,NODE8,NODE9,NODE10,NODE11,NODE12,NODE13,NODE14,NODE15,NODE16,TOOL

BO_ 392 S0_NODE_STATUS_FAST_8: 8 NODE8
 SG_ status_flags : 0|8@1+ (1,0) [0|255] "bitfield"  MASTER,NODE1,NODE2,NODE3,NODE4,NODE5,NODE6,NODE7,NODE8,NODE9,NODE10,NODE11,NODE12,NODE13,NODE14,NODE15,NODE16,TOOL
 SG_ error_code : 8|8@1+ (1,0) [0|255] ""  MASTER,NODE1,NODE2,NODE3,NODE4,NODE5,NODE6,NODE7,NODE8,NODE9,NODE10,NODE11,NODE12,NODE13,NODE14,NODE15,NODE16,TOOL
 SG_ actual_rpm : 16|16@1- (0.1,0) [-3276.8|3276.7] "rpm"  MASTER,NODE1,NODE2,NODE3,NODE4,NODE5,NODE6,NODE7,NODE8,NODE9,NODE10,NODE11,NODE12,NODE13,NODE14,NODE15,NODE16,TOOL
 SG_ actual_pos : 32|16@1+ (1.52587890625e-05,0) [0|0.9999847412109375] "rev"  MASTER,NODE1,NODE2,NODE3,NODE4,NODE5,NODE6,NODE7,NODE8,NODE9,NODE10,NODE11,NODE12,NODE13,NODE14,NODE15,NODE16,TOOL
 SG_ alive_counter : 48|8@1+ (1,0) [0|255] ""  MASTER,NODE1,NODE2,NODE3,NODE4,NODE5,NODE6,NODE7,NODE8,NODE9,NODE10,NODE11,NODE12,NODE13,NODE14,NODE15,NODE16,TOOL
 SG_ sync_error : 56|8@1- (0.00390625,0) [-0.5|0.49609375] "rev"  MASTER,NODE1,NODE2,NODE3,NODE4,NODE5,NODE6,NODE7,NODE8,NODE9,NODE10,NODE11,NODE12,NODE13,NODE14,NODE15,NODE16,TOOL

BO_ 456 S0_NODE_DIAG_8: 8 NODE8
 SG_ bus_voltage : 0|16@1+ (0.1,0) [0|6553.5] "V"  MASTER,NODE1,NODE2,NODE3,NODE4,NODE5,NODE6,NODE7,NODE8,NODE9,NODE10,NODE11,NODE12,NODE13,NODE14,NODE15,NODE16,TOOL
 SG_ motor_current : 16|16@1- (0.1,0) [-3276.8|3276.7] "A"  MASTER,NODE1,NODE2,NODE3,NODE4,NODE5,NODE6,NODE7,NODE8,NODE9,NODE10,NODE11,NODE12,NODE13,NODE14,NODE15,NODE16,TOOL
 SG_ controller_temp : 32|8@1- (1,0) [-128|127] "degC"  MASTER,NODE1,NODE2,NODE3,NODE4,NODE5,NODE6,NODE7,NODE8,NODE9,NODE10,NODE11,NODE12,NODE13,NODE14,NODE15,NODE16,TOOL
 SG_ motor_temp : 40|8@1- (1,0) [-128|127] "degC"  MASTER,NODE1,NODE2,NODE3,NODE4,NODE5,NODE6,NODE7,NODE8,NODE9,NODE10,NODE11,NODE12,NODE13,NODE14,NODE15,NODE16,TOOL
 SG_ fault_flags : 48|8@1+ (1,0) [0|255] "bitfield"  MASTER,NODE1,NODE2,NODE3,NODE4,NODE5,NODE6,NODE7,NODE8,NODE9,NODE10,NODE11,NODE12,NODE13,NODE14,NODE15,NODE16,TOOL
 SG_ warning_flags : 56|8@1+ (1,0) [0|255] "bitfield"  MASTER,NODE1,NODE2,NODE3,NODE4,NODE5,NODE6,NODE7,NODE8,NODE9,NODE10,NODE11,NODE12,NODE13,NODE14,NODE15,NODE16,TOOL

BO_ 265 S0_NODE_CMD_9: 8 MASTER
 SG_ node_command : 0|8@1+ (1,0) [0|255] ""  MASTER,NODE1,NODE2,NODE3,NODE4,NODE5,NODE6,NODE7,NODE8,NODE9,NODE10,NODE11,NODE12,NODE13,NODE14,NODE15,NODE16,TOOL
 SG_ node_flags : 8|8@1+ (1,0) [0|255] "bitfield"  MASTER,NODE1,NODE2,NODE3,NODE4,NODE5,NODE6,NODE7,NODE8,NODE9,NODE10,NODE11,NODE12,NODE13,NODE14,NODE15,NODE16,TOOL
 SG_ trim_rpm : 16|16@1- (0.1,0) [-3276.8|3276.7] "rpm"  MASTER,NODE1,NODE2,NODE3,NODE4,NODE5,NODE6,NODE7,NODE8,NODE9,NODE10,NODE11,NODE12,NODE13,NODE14,NODE15,NODE16,TOOL
 SG_ section_mask : 32|16@1+ (1,0) [0|65535] "bitmask"  MASTER,NODE1,NODE2,NODE3,NODE4,NODE5,NODE6,NODE7,NODE8,NODE9,NODE10,NODE11,NODE12,NODE13,NODE14,NODE15,NODE16,TOOL
 SG_ seq : 48|8@1+ (1,0) [0|255] ""  MASTER,NODE1,NODE2,NODE3,NODE4,NODE5,NODE6,NODE7,NODE8,NODE9,NODE10,NODE11,NODE12,NODE13,NODE14,NODE15,NODE16,TOOL
 SG_ reserved : 56|8@1+ (1,0) [0|255] ""  MASTER,NODE1,NODE2,NODE3,NODE4,NODE5,NODE6,NODE7,NODE8,NODE9,NODE10,NODE11,NODE12,NODE13,NODE14,NODE15,NODE16,TOOL

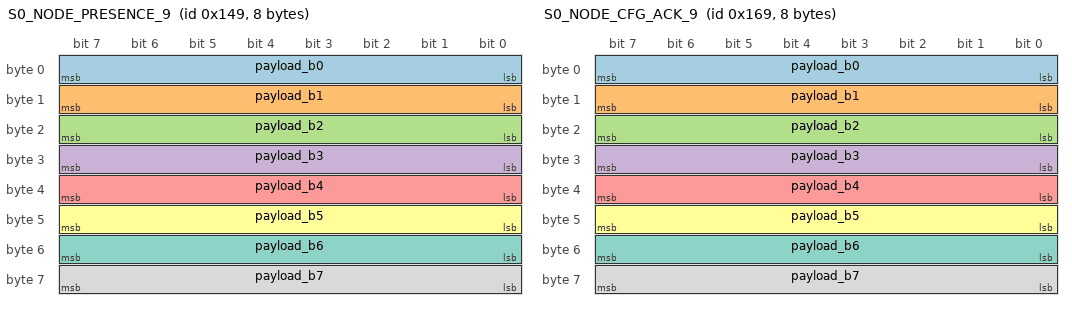
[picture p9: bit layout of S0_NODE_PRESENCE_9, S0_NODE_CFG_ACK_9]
BO_ 329 S0_NODE_PRESENCE_9: 8 NODE9
 SG_ payload_b0 : 0|8@1+ (1,0) [0|255] "raw"  MASTER,NODE1,NODE2,NODE3,NODE4,NODE5,NODE6,NODE7,NODE8,NODE9,NODE10,NODE11,NODE12,NODE13,NODE14,NODE15,NODE16,TOOL
 SG_ payload_b1 : 8|8@1+ (1,0) [0|255] "raw"  MASTER,NODE1,NODE2,NODE3,NODE4,NODE5,NODE6,NODE7,NODE8,NODE9,NODE10,NODE11,NODE12,NODE13,NODE14,NODE15,NODE16,TOOL
 SG_ payload_b2 : 16|8@1+ (1,0) [0|255] "raw"  MASTER,NODE1,NODE2,NODE3,NODE4,NODE5,NODE6,NODE7,NODE8,NODE9,NODE10,NODE11,NODE12,NODE13,NODE14,NODE15,NODE16,TOOL
 SG_ payload_b3 : 24|8@1+ (1,0) [0|255] "raw"  MASTER,NODE1,NODE2,NODE3,NODE4,NODE5,NODE6,NODE7,NODE8,NODE9,NODE10,NODE11,NODE12,NODE13,NODE14,NODE15,NODE16,TOOL
 SG_ payload_b4 : 32|8@1+ (1,0) [0|255] "raw"  MASTER,NODE1,NODE2,NODE3,NODE4,NODE5,NODE6,NODE7,NODE8,NODE9,NODE10,NODE11,NODE12,NODE13,NODE14,NODE15,NODE16,TOOL
 SG_ payload_b5 : 40|8@1+ (1,0) [0|255] "raw"  MASTER,NODE1,NODE2,NODE3,NODE4,NODE5,NODE6,NODE7,NODE8,NODE9,NODE10,NODE11,NODE12,NODE13,NODE14,NODE15,NODE16,TOOL
 SG_ payload_b6 : 48|8@1+ (1,0) [0|255] "raw"  MASTER,NODE1,NODE2,NODE3,NODE4,NODE5,NODE6,NODE7,NODE8,NODE9,NODE10,NODE11,NODE12,NODE13,NODE14,NODE15,NODE16,TOOL
 SG_ payload_b7 : 56|8@1+ (1,0) [0|255] "raw"  MASTER,NODE1,NODE2,NODE3,NODE4,NODE5,NODE6,NODE7,NODE8,NODE9,NODE10,NODE11,NODE12,NODE13,NODE14,NODE15,NODE16,TOOL

BO_ 361 S0_NODE_CFG_ACK_9: 8 NODE9
 SG_ payload_b0 : 0|8@1+ (1,0) [0|255] "raw"  MASTER,NODE1,NODE2,NODE3,NODE4,NODE5,NODE6,NODE7,NODE8,NODE9,NODE10,NODE11,NODE12,NODE13,NODE14,NODE15,NODE16,TOOL
 SG_ payload_b1 : 8|8@1+ (1,0) [0|255] "raw"  MASTER,NODE1,NODE2,NODE3,NODE4,NODE5,NODE6,NODE7,NODE8,NODE9,NODE10,NODE11,NODE12,NODE13,NODE14,NODE15,NODE16,TOOL
 SG_ payload_b2 : 16|8@1+ (1,0) [0|255] "raw"  MASTER,NODE1,NODE2,NODE3,NODE4,NODE5,NODE6,NODE7,NODE8,NODE9,NODE10,NODE11,NODE12,NODE13,NODE14,NODE15,NODE16,TOOL
 SG_ payload_b3 : 24|8@1+ (1,0) [0|255] "raw"  MASTER,NODE1,NODE2,NODE3,NODE4,NODE5,NODE6,NODE7,NODE8,NODE9,NODE10,NODE11,NODE12,NODE13,NODE14,NODE15,NODE16,TOOL
 SG_ payload_b4 : 32|8@1+ (1,0) [0|255] "raw"  MASTER,NODE1,NODE2,NODE3,NODE4,NODE5,NODE6,NODE7,NODE8,NODE9,NODE10,NODE11,NODE12,NODE13,NODE14,NODE15,NODE16,TOOL
 SG_ payload_b5 : 40|8@1+ (1,0) [0|255] "raw"  MASTER,NODE1,NODE2,NODE3,NODE4,NODE5,NODE6,NODE7,NODE8,NODE9,NODE10,NODE11,NODE12,NODE13,NODE14,NODE15,NODE16,TOOL
 SG_ payload_b6 : 48|8@1+ (1,0) [0|255] "raw"  MASTER,NODE1,NODE2,NODE3,NODE4,NODE5,NODE6,NODE7,NODE8,NODE9,NODE10,NODE11,NODE12,NODE13,NODE14,NODE15,NODE16,TOOL
 SG_ payload_b7 : 56|8@1+ (1,0) [0|255] "raw"  MASTER,NODE1,NODE2,NODE3,NODE4,NODE5,NODE6,NODE7,NODE8,NODE9,NODE10,NODE11,NODE12,NODE13,NODE14,NODE15,NODE16,TOOL

BO_ 393 S0_NODE_STATUS_FAST_9: 8 NODE9
 SG_ status_flags : 0|8@1+ (1,0) [0|255] "bitfield"  MASTER,NODE1,NODE2,NODE3,NODE4,NODE5,NODE6,NODE7,NODE8,NODE9,NODE10,NODE11,NODE12,NODE13,NODE14,NODE15,NODE16,TOOL
 SG_ error_code : 8|8@1+ (1,0) [0|255] ""  MASTER,NODE1,NODE2,NODE3,NODE4,NODE5,NODE6,NODE7,NODE8,NODE9,NODE10,NODE11,NODE12,NODE13,NODE14,NODE15,NODE16,TOOL
 SG_ actual_rpm : 16|16@1- (0.1,0) [-3276.8|3276.7] "rpm"  MASTER,NODE1,NODE2,NODE3,NODE4,NODE5,NODE6,NODE7,NODE8,NODE9,NODE10,NODE11,NODE12,NODE13,NODE14,NODE15,NODE16,TOOL
 SG_ actual_pos : 32|16@1+ (1.52587890625e-05,0) [0|0.9999847412109375] "rev"  MASTER,NODE1,NODE2,NODE3,NODE4,NODE5,NODE6,NODE7,NODE8,NODE9,NODE10,NODE11,NODE12,NODE13,NODE14,NODE15,NODE16,TOOL
 SG_ alive_counter : 48|8@1+ (1,0) [0|255] ""  MASTER,NODE1,NODE2,NODE3,NODE4,NODE5,NODE6,NODE7,NODE8,NODE9,NODE10,NODE11,NODE12,NODE13,NODE14,NODE15,NODE16,TOOL
 SG_ sync_error : 56|8@1- (0.00390625,0) [-0.5|0.49609375] "rev"  MASTER,NODE1,NODE2,NODE3,NODE4,NODE5,NODE6,NODE7,NODE8,NODE9,NODE10,NODE11,NODE12,NODE13,NODE14,NODE15,NODE16,TOOL

BO_ 457 S0_NODE_DIAG_9: 8 NODE9
 SG_ bus_voltage : 0|16@1+ (0.1,0) [0|6553.5] "V"  MASTER,NODE1,NODE2,NODE3,NODE4,NODE5,NODE6,NODE7,NODE8,NODE9,NODE10,NODE11,NODE12,NODE13,NODE14,NODE15,NODE16,TOOL
 SG_ motor_current : 16|16@1- (0.1,0) [-3276.8|3276.7] "A"  MASTER,NODE1,NODE2,NODE3,NODE4,NODE5,NODE6,NODE7,NODE8,NODE9,NODE10,NODE11,NODE12,NODE13,NODE14,NODE15,NODE16,TOOL
 SG_ controller_temp : 32|8@1- (1,0) [-128|127] "degC"  MASTER,NODE1,NODE2,NODE3,NODE4,NODE5,NODE6,NODE7,NODE8,NODE9,NODE10,NODE11,NODE12,NODE13,NODE14,NODE15,NODE16,TOOL
 SG_ motor_temp : 40|8@1- (1,0) [-128|127] "degC"  MASTER,NODE1,NODE2,NODE3,NODE4,NODE5,NODE6,NODE7,NODE8,NODE9,NODE10,NODE11,NODE12,NODE13,NODE14,NODE15,NODE16,TOOL
 SG_ fault_flags : 48|8@1+ (1,0) [0|255] "bitfield"  MASTER,NODE1,NODE2,NODE3,NODE4,NODE5,NODE6,NODE7,NODE8,NODE9,NODE10,NODE11,NODE12,NODE13,NODE14,NODE15,NODE16,TOOL
 SG_ warning_flags : 56|8@1+ (1,0) [0|255] "bitfield"  MASTER,NODE1,NODE2,NODE3,NODE4,NODE5,NODE6,NODE7,NODE8,NODE9,NODE10,NODE11,NODE12,NODE13,NODE14,NODE15,NODE16,TOOL

BO_ 266 S0_NODE_CMD_10: 8 MASTER
 SG_ node_command : 0|8@1+ (1,0) [0|255] ""  MASTER,NODE1,NODE2,NODE3,NODE4,NODE5,NODE6,NODE7,NODE8,NODE9,NODE10,NODE11,NODE12,NODE13,NODE14,NODE15,NODE16,TOOL
 SG_ node_flags : 8|8@1+ (1,0) [0|255] "bitfield"  MASTER,NODE1,NODE2,NODE3,NODE4,NODE5,NODE6,NODE7,NODE8,NODE9,NODE10,NODE11,NODE12,NODE13,NODE14,NODE15,NODE16,TOOL
 SG_ trim_rpm : 16|16@1- (0.1,0) [-3276.8|3276.7] "rpm"  MASTER,NODE1,NODE2,NODE3,NODE4,NODE5,NODE6,NODE7,NODE8,NODE9,NODE10,NODE11,NODE12,NODE13,NODE14,NODE15,NODE16,TOOL
 SG_ section_mask : 32|16@1+ (1,0) [0|65535] "bitmask"  MASTER,NODE1,NODE2,NODE3,NODE4,NODE5,NODE6,NODE7,NODE8,NODE9,NODE10,NODE11,NODE12,NODE13,NODE14,NODE15,NODE16,TOOL
 SG_ seq : 48|8@1+ (1,0) [0|255] ""  MASTER,NODE1,NODE2,NODE3,NODE4,NODE5,NODE6,NODE7,NODE8,NODE9,NODE10,NODE11,NODE12,NODE13,NODE14,NODE15,NODE16,TOOL
 SG_ reserved : 56|8@1+ (1,0) [0|255] ""  MASTER,NODE1,NODE2,NODE3,NODE4,NODE5,NODE6,NODE7,NODE8,NODE9,NODE10,NODE11,NODE12,NODE13,NODE14,NODE15,NODE16,TOOL

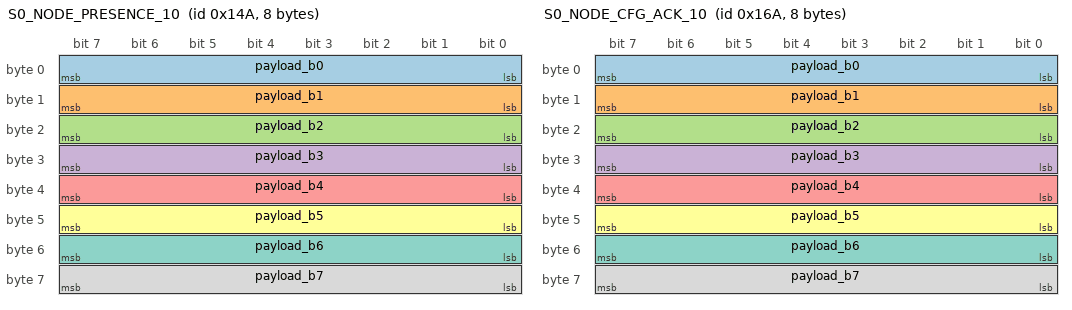
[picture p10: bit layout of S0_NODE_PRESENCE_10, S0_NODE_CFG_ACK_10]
BO_ 330 S0_NODE_PRESENCE_10: 8 NODE10
 SG_ payload_b0 : 0|8@1+ (1,0) [0|255] "raw"  MASTER,NODE1,NODE2,NODE3,NODE4,NODE5,NODE6,NODE7,NODE8,NODE9,NODE10,NODE11,NODE12,NODE13,NODE14,NODE15,NODE16,TOOL
 SG_ payload_b1 : 8|8@1+ (1,0) [0|255] "raw"  MASTER,NODE1,NODE2,NODE3,NODE4,NODE5,NODE6,NODE7,NODE8,NODE9,NODE10,NODE11,NODE12,NODE13,NODE14,NODE15,NODE16,TOOL
 SG_ payload_b2 : 16|8@1+ (1,0) [0|255] "raw"  MASTER,NODE1,NODE2,NODE3,NODE4,NODE5,NODE6,NODE7,NODE8,NODE9,NODE10,NODE11,NODE12,NODE13,NODE14,NODE15,NODE16,TOOL
 SG_ payload_b3 : 24|8@1+ (1,0) [0|255] "raw"  MASTER,NODE1,NODE2,NODE3,NODE4,NODE5,NODE6,NODE7,NODE8,NODE9,NODE10,NODE11,NODE12,NODE13,NODE14,NODE15,NODE16,TOOL
 SG_ payload_b4 : 32|8@1+ (1,0) [0|255] "raw"  MASTER,NODE1,NODE2,NODE3,NODE4,NODE5,NODE6,NODE7,NODE8,NODE9,NODE10,NODE11,NODE12,NODE13,NODE14,NODE15,NODE16,TOOL
 SG_ payload_b5 : 40|8@1+ (1,0) [0|255] "raw"  MASTER,NODE1,NODE2,NODE3,NODE4,NODE5,NODE6,NODE7,NODE8,NODE9,NODE10,NODE11,NODE12,NODE13,NODE14,NODE15,NODE16,TOOL
 SG_ payload_b6 : 48|8@1+ (1,0) [0|255] "raw"  MASTER,NODE1,NODE2,NODE3,NODE4,NODE5,NODE6,NODE7,NODE8,NODE9,NODE10,NODE11,NODE12,NODE13,NODE14,NODE15,NODE16,TOOL
 SG_ payload_b7 : 56|8@1+ (1,0) [0|255] "raw"  MASTER,NODE1,NODE2,NODE3,NODE4,NODE5,NODE6,NODE7,NODE8,NODE9,NODE10,NODE11,NODE12,NODE13,NODE14,NODE15,NODE16,TOOL

BO_ 362 S0_NODE_CFG_ACK_10: 8 NODE10
 SG_ payload_b0 : 0|8@1+ (1,0) [0|255] "raw"  MASTER,NODE1,NODE2,NODE3,NODE4,NODE5,NODE6,NODE7,NODE8,NODE9,NODE10,NODE11,NODE12,NODE13,NODE14,NODE15,NODE16,TOOL
 SG_ payload_b1 : 8|8@1+ (1,0) [0|255] "raw"  MASTER,NODE1,NODE2,NODE3,NODE4,NODE5,NODE6,NODE7,NODE8,NODE9,NODE10,NODE11,NODE12,NODE13,NODE14,NODE15,NODE16,TOOL
 SG_ payload_b2 : 16|8@1+ (1,0) [0|255] "raw"  MASTER,NODE1,NODE2,NODE3,NODE4,NODE5,NODE6,NODE7,NODE8,NODE9,NODE10,NODE11,NODE12,NODE13,NODE14,NODE15,NODE16,TOOL
 SG_ payload_b3 : 24|8@1+ (1,0) [0|255] "raw"  MASTER,NODE1,NODE2,NODE3,NODE4,NODE5,NODE6,NODE7,NODE8,NODE9,NODE10,NODE11,NODE12,NODE13,NODE14,NODE15,NODE16,TOOL
 SG_ payload_b4 : 32|8@1+ (1,0) [0|255] "raw"  MASTER,NODE1,NODE2,NODE3,NODE4,NODE5,NODE6,NODE7,NODE8,NODE9,NODE10,NODE11,NODE12,NODE13,NODE14,NODE15,NODE16,TOOL
 SG_ payload_b5 : 40|8@1+ (1,0) [0|255] "raw"  MASTER,NODE1,NODE2,NODE3,NODE4,NODE5,NODE6,NODE7,NODE8,NODE9,NODE10,NODE11,NODE12,NODE13,NODE14,NODE15,NODE16,TOOL
 SG_ payload_b6 : 48|8@1+ (1,0) [0|255] "raw"  MASTER,NODE1,NODE2,NODE3,NODE4,NODE5,NODE6,NODE7,NODE8,NODE9,NODE10,NODE11,NODE12,NODE13,NODE14,NODE15,NODE16,TOOL
 SG_ payload_b7 : 56|8@1+ (1,0) [0|255] "raw"  MASTER,NODE1,NODE2,NODE3,NODE4,NODE5,NODE6,NODE7,NODE8,NODE9,NODE10,NODE11,NODE12,NODE13,NODE14,NODE15,NODE16,TOOL

BO_ 394 S0_NODE_STATUS_FAST_10: 8 NODE10
 SG_ status_flags : 0|8@1+ (1,0) [0|255] "bitfield"  MASTER,NODE1,NODE2,NODE3,NODE4,NODE5,NODE6,NODE7,NODE8,NODE9,NODE10,NODE11,NODE12,NODE13,NODE14,NODE15,NODE16,TOOL
 SG_ error_code : 8|8@1+ (1,0) [0|255] ""  MASTER,NODE1,NODE2,NODE3,NODE4,NODE5,NODE6,NODE7,NODE8,NODE9,NODE10,NODE11,NODE12,NODE13,NODE14,NODE15,NODE16,TOOL
 SG_ actual_rpm : 16|16@1- (0.1,0) [-3276.8|3276.7] "rpm"  MASTER,NODE1,NODE2,NODE3,NODE4,NODE5,NODE6,NODE7,NODE8,NODE9,NODE10,NODE11,NODE12,NODE13,NODE14,NODE15,NODE16,TOOL
 SG_ actual_pos : 32|16@1+ (1.52587890625e-05,0) [0|0.9999847412109375] "rev"  MASTER,NODE1,NODE2,NODE3,NODE4,NODE5,NODE6,NODE7,NODE8,NODE9,NODE10,NODE11,NODE12,NODE13,NODE14,NODE15,NODE16,TOOL
 SG_ alive_counter : 48|8@1+ (1,0) [0|255] ""  MASTER,NODE1,NODE2,NODE3,NODE4,NODE5,NODE6,NODE7,NODE8,NODE9,NODE10,NODE11,NODE12,NODE13,NODE14,NODE15,NODE16,TOOL
 SG_ sync_error : 56|8@1- (0.00390625,0) [-0.5|0.49609375] "rev"  MASTER,NODE1,NODE2,NODE3,NODE4,NODE5,NODE6,NODE7,NODE8,NODE9,NODE10,NODE11,NODE12,NODE13,NODE14,NODE15,NODE16,TOOL

BO_ 458 S0_NODE_DIAG_10: 8 NODE10
 SG_ bus_voltage : 0|16@1+ (0.1,0) [0|6553.5] "V"  MASTER,NODE1,NODE2,NODE3,NODE4,NODE5,NODE6,NODE7,NODE8,NODE9,NODE10,NODE11,NODE12,NODE13,NODE14,NODE15,NODE16,TOOL
 SG_ motor_current : 16|16@1- (0.1,0) [-3276.8|3276.7] "A"  MASTER,NODE1,NODE2,NODE3,NODE4,NODE5,NODE6,NODE7,NODE8,NODE9,NODE10,NODE11,NODE12,NODE13,NODE14,NODE15,NODE16,TOOL
 SG_ controller_temp : 32|8@1- (1,0) [-128|127] "degC"  MASTER,NODE1,NODE2,NODE3,NODE4,NODE5,NODE6,NODE7,NODE8,NODE9,NODE10,NODE11,NODE12,NODE13,NODE14,NODE15,NODE16,TOOL
 SG_ motor_temp : 40|8@1- (1,0) [-128|127] "degC"  MASTER,NODE1,NODE2,NODE3,NODE4,NODE5,NODE6,NODE7,NODE8,NODE9,NODE10,NODE11,NODE12,NODE13,NODE14,NODE15,NODE16,TOOL
 SG_ fault_flags : 48|8@1+ (1,0) [0|255] "bitfield"  MASTER,NODE1,NODE2,NODE3,NODE4,NODE5,NODE6,NODE7,NODE8,NODE9,NODE10,NODE11,NODE12,NODE13,NODE14,NODE15,NODE16,TOOL
 SG_ warning_flags : 56|8@1+ (1,0) [0|255] "bitfield"  MASTER,NODE1,NODE2,NODE3,NODE4,NODE5,NODE6,NODE7,NODE8,NODE9,NODE10,NODE11,NODE12,NODE13,NODE14,NODE15,NODE16,TOOL

BO_ 267 S0_NODE_CMD_11: 8 MASTER
 SG_ node_command : 0|8@1+ (1,0) [0|255] ""  MASTER,NODE1,NODE2,NODE3,NODE4,NODE5,NODE6,NODE7,NODE8,NODE9,NODE10,NODE11,NODE12,NODE13,NODE14,NODE15,NODE16,TOOL
 SG_ node_flags : 8|8@1+ (1,0) [0|255] "bitfield"  MASTER,NODE1,NODE2,NODE3,NODE4,NODE5,NODE6,NODE7,NODE8,NODE9,NODE10,NODE11,NODE12,NODE13,NODE14,NODE15,NODE16,TOOL
 SG_ trim_rpm : 16|16@1- (0.1,0) [-3276.8|3276.7] "rpm"  MASTER,NODE1,NODE2,NODE3,NODE4,NODE5,NODE6,NODE7,NODE8,NODE9,NODE10,NODE11,NODE12,NODE13,NODE14,NODE15,NODE16,TOOL
 SG_ section_mask : 32|16@1+ (1,0) [0|65535] "bitmask"  MASTER,NODE1,NODE2,NODE3,NODE4,NODE5,NODE6,NODE7,NODE8,NODE9,NODE10,NODE11,NODE12,NODE13,NODE14,NODE15,NODE16,TOOL
 SG_ seq : 48|8@1+ (1,0) [0|255] ""  MASTER,NODE1,NODE2,NODE3,NODE4,NODE5,NODE6,NODE7,NODE8,NODE9,NODE10,NODE11,NODE12,NODE13,NODE14,NODE15,NODE16,TOOL
 SG_ reserved : 56|8@1+ (1,0) [0|255] ""  MASTER,NODE1,NODE2,NODE3,NODE4,NODE5,NODE6,NODE7,NODE8,NODE9,NODE10,NODE11,NODE12,NODE13,NODE14,NODE15,NODE16,TOOL

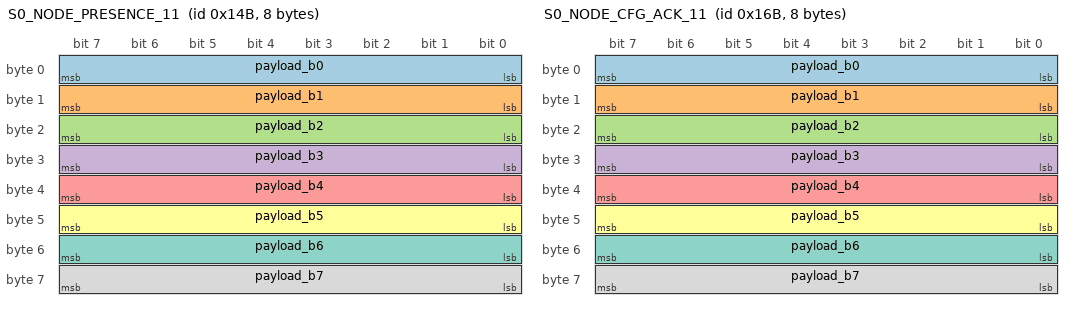
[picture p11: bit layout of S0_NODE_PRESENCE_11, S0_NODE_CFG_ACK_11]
BO_ 331 S0_NODE_PRESENCE_11: 8 NODE11
 SG_ payload_b0 : 0|8@1+ (1,0) [0|255] "raw"  MASTER,NODE1,NODE2,NODE3,NODE4,NODE5,NODE6,NODE7,NODE8,NODE9,NODE10,NODE11,NODE12,NODE13,NODE14,NODE15,NODE16,TOOL
 SG_ payload_b1 : 8|8@1+ (1,0) [0|255] "raw"  MASTER,NODE1,NODE2,NODE3,NODE4,NODE5,NODE6,NODE7,NODE8,NODE9,NODE10,NODE11,NODE12,NODE13,NODE14,NODE15,NODE16,TOOL
 SG_ payload_b2 : 16|8@1+ (1,0) [0|255] "raw"  MASTER,NODE1,NODE2,NODE3,NODE4,NODE5,NODE6,NODE7,NODE8,NODE9,NODE10,NODE11,NODE12,NODE13,NODE14,NODE15,NODE16,TOOL
 SG_ payload_b3 : 24|8@1+ (1,0) [0|255] "raw"  MASTER,NODE1,NODE2,NODE3,NODE4,NODE5,NODE6,NODE7,NODE8,NODE9,NODE10,NODE11,NODE12,NODE13,NODE14,NODE15,NODE16,TOOL
 SG_ payload_b4 : 32|8@1+ (1,0) [0|255] "raw"  MASTER,NODE1,NODE2,NODE3,NODE4,NODE5,NODE6,NODE7,NODE8,NODE9,NODE10,NODE11,NODE12,NODE13,NODE14,NODE15,NODE16,TOOL
 SG_ payload_b5 : 40|8@1+ (1,0) [0|255] "raw"  MASTER,NODE1,NODE2,NODE3,NODE4,NODE5,NODE6,NODE7,NODE8,NODE9,NODE10,NODE11,NODE12,NODE13,NODE14,NODE15,NODE16,TOOL
 SG_ payload_b6 : 48|8@1+ (1,0) [0|255] "raw"  MASTER,NODE1,NODE2,NODE3,NODE4,NODE5,NODE6,NODE7,NODE8,NODE9,NODE10,NODE11,NODE12,NODE13,NODE14,NODE15,NODE16,TOOL
 SG_ payload_b7 : 56|8@1+ (1,0) [0|255] "raw"  MASTER,NODE1,NODE2,NODE3,NODE4,NODE5,NODE6,NODE7,NODE8,NODE9,NODE10,NODE11,NODE12,NODE13,NODE14,NODE15,NODE16,TOOL

BO_ 363 S0_NODE_CFG_ACK_11: 8 NODE11
 SG_ payload_b0 : 0|8@1+ (1,0) [0|255] "raw"  MASTER,NODE1,NODE2,NODE3,NODE4,NODE5,NODE6,NODE7,NODE8,NODE9,NODE10,NODE11,NODE12,NODE13,NODE14,NODE15,NODE16,TOOL
 SG_ payload_b1 : 8|8@1+ (1,0) [0|255] "raw"  MASTER,NODE1,NODE2,NODE3,NODE4,NODE5,NODE6,NODE7,NODE8,NODE9,NODE10,NODE11,NODE12,NODE13,NODE14,NODE15,NODE16,TOOL
 SG_ payload_b2 : 16|8@1+ (1,0) [0|255] "raw"  MASTER,NODE1,NODE2,NODE3,NODE4,NODE5,NODE6,NODE7,NODE8,NODE9,NODE10,NODE11,NODE12,NODE13,NODE14,NODE15,NODE16,TOOL
 SG_ payload_b3 : 24|8@1+ (1,0) [0|255] "raw"  MASTER,NODE1,NODE2,NODE3,NODE4,NODE5,NODE6,NODE7,NODE8,NODE9,NODE10,NODE11,NODE12,NODE13,NODE14,NODE15,NODE16,TOOL
 SG_ payload_b4 : 32|8@1+ (1,0) [0|255] "raw"  MASTER,NODE1,NODE2,NODE3,NODE4,NODE5,NODE6,NODE7,NODE8,NODE9,NODE10,NODE11,NODE12,NODE13,NODE14,NODE15,NODE16,TOOL
 SG_ payload_b5 : 40|8@1+ (1,0) [0|255] "raw"  MASTER,NODE1,NODE2,NODE3,NODE4,NODE5,NODE6,NODE7,NODE8,NODE9,NODE10,NODE11,NODE12,NODE13,NODE14,NODE15,NODE16,TOOL
 SG_ payload_b6 : 48|8@1+ (1,0) [0|255] "raw"  MASTER,NODE1,NODE2,NODE3,NODE4,NODE5,NODE6,NODE7,NODE8,NODE9,NODE10,NODE11,NODE12,NODE13,NODE14,NODE15,NODE16,TOOL
 SG_ payload_b7 : 56|8@1+ (1,0) [0|255] "raw"  MASTER,NODE1,NODE2,NODE3,NODE4,NODE5,NODE6,NODE7,NODE8,NODE9,NODE10,NODE11,NODE12,NODE13,NODE14,NODE15,NODE16,TOOL

BO_ 395 S0_NODE_STATUS_FAST_11: 8 NODE11
 SG_ status_flags : 0|8@1+ (1,0) [0|255] "bitfield"  MASTER,NODE1,NODE2,NODE3,NODE4,NODE5,NODE6,NODE7,NODE8,NODE9,NODE10,NODE11,NODE12,NODE13,NODE14,NODE15,NODE16,TOOL
 SG_ error_code : 8|8@1+ (1,0) [0|255] ""  MASTER,NODE1,NODE2,NODE3,NODE4,NODE5,NODE6,NODE7,NODE8,NODE9,NODE10,NODE11,NODE12,NODE13,NODE14,NODE15,NODE16,TOOL
 SG_ actual_rpm : 16|16@1- (0.1,0) [-3276.8|3276.7] "rpm"  MASTER,NODE1,NODE2,NODE3,NODE4,NODE5,NODE6,NODE7,NODE8,NODE9,NODE10,NODE11,NODE12,NODE13,NODE14,NODE15,NODE16,TOOL
 SG_ actual_pos : 32|16@1+ (1.52587890625e-05,0) [0|0.9999847412109375] "rev"  MASTER,NODE1,NODE2,NODE3,NODE4,NODE5,NODE6,NODE7,NODE8,NODE9,NODE10,NODE11,NODE12,NODE13,NODE14,NODE15,NODE16,TOOL
 SG_ alive_counter : 48|8@1+ (1,0) [0|255] ""  MASTER,NODE1,NODE2,NODE3,NODE4,NODE5,NODE6,NODE7,NODE8,NODE9,NODE10,NODE11,NODE12,NODE13,NODE14,NODE15,NODE16,TOOL
 SG_ sync_error : 56|8@1- (0.00390625,0) [-0.5|0.49609375] "rev"  MASTER,NODE1,NODE2,NODE3,NODE4,NODE5,NODE6,NODE7,NODE8,NODE9,NODE10,NODE11,NODE12,NODE13,NODE14,NODE15,NODE16,TOOL

BO_ 459 S0_NODE_DIAG_11: 8 NODE11
 SG_ bus_voltage : 0|16@1+ (0.1,0) [0|6553.5] "V"  MASTER,NODE1,NODE2,NODE3,NODE4,NODE5,NODE6,NODE7,NODE8,NODE9,NODE10,NODE11,NODE12,NODE13,NODE14,NODE15,NODE16,TOOL
 SG_ motor_current : 16|16@1- (0.1,0) [-3276.8|3276.7] "A"  MASTER,NODE1,NODE2,NODE3,NODE4,NODE5,NODE6,NODE7,NODE8,NODE9,NODE10,NODE11,NODE12,NODE13,NODE14,NODE15,NODE16,TOOL
 SG_ controller_temp : 32|8@1- (1,0) [-128|127] "degC"  MASTER,NODE1,NODE2,NODE3,NODE4,NODE5,NODE6,NODE7,NODE8,NODE9,NODE10,NODE11,NODE12,NODE13,NODE14,NODE15,NODE16,TOOL
 SG_ motor_temp : 40|8@1- (1,0) [-128|127] "degC"  MASTER,NODE1,NODE2,NODE3,NODE4,NODE5,NODE6,NODE7,NODE8,NODE9,NODE10,NODE11,NODE12,NODE13,NODE14,NODE15,NODE16,TOOL
 SG_ fault_flags : 48|8@1+ (1,0) [0|255] "bitfield"  MASTER,NODE1,NODE2,NODE3,NODE4,NODE5,NODE6,NODE7,NODE8,NODE9,NODE10,NODE11,NODE12,NODE13,NODE14,NODE15,NODE16,TOOL
 SG_ warning_flags : 56|8@1+ (1,0) [0|255] "bitfield"  MASTER,NODE1,NODE2,NODE3,NODE4,NODE5,NODE6,NODE7,NODE8,NODE9,NODE10,NODE11,NODE12,NODE13,NODE14,NODE15,NODE16,TOOL

BO_ 268 S0_NODE_CMD_12: 8 MASTER
 SG_ node_command : 0|8@1+ (1,0) [0|255] ""  MASTER,NODE1,NODE2,NODE3,NODE4,NODE5,NODE6,NODE7,NODE8,NODE9,NODE10,NODE11,NODE12,NODE13,NODE14,NODE15,NODE16,TOOL
 SG_ node_flags : 8|8@1+ (1,0) [0|255] "bitfield"  MASTER,NODE1,NODE2,NODE3,NODE4,NODE5,NODE6,NODE7,NODE8,NODE9,NODE10,NODE11,NODE12,NODE13,NODE14,NODE15,NODE16,TOOL
 SG_ trim_rpm : 16|16@1- (0.1,0) [-3276.8|3276.7] "rpm"  MASTER,NODE1,NODE2,NODE3,NODE4,NODE5,NODE6,NODE7,NODE8,NODE9,NODE10,NODE11,NODE12,NODE13,NODE14,NODE15,NODE16,TOOL
 SG_ section_mask : 32|16@1+ (1,0) [0|65535] "bitmask"  MASTER,NODE1,NODE2,NODE3,NODE4,NODE5,NODE6,NODE7,NODE8,NODE9,NODE10,NODE11,NODE12,NODE13,NODE14,NODE15,NODE16,TOOL
 SG_ seq : 48|8@1+ (1,0) [0|255] ""  MASTER,NODE1,NODE2,NODE3,NODE4,NODE5,NODE6,NODE7,NODE8,NODE9,NODE10,NODE11,NODE12,NODE13,NODE14,NODE15,NODE16,TOOL
 SG_ reserved : 56|8@1+ (1,0) [0|255] ""  MASTER,NODE1,NODE2,NODE3,NODE4,NODE5,NODE6,NODE7,NODE8,NODE9,NODE10,NODE11,NODE12,NODE13,NODE14,NODE15,NODE16,TOOL

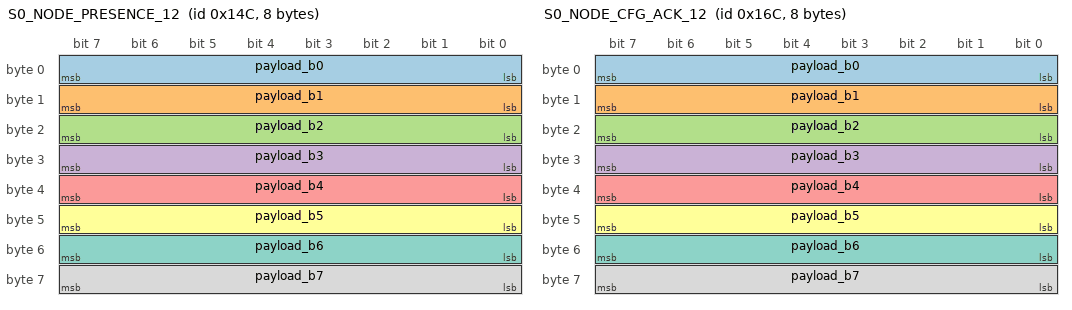
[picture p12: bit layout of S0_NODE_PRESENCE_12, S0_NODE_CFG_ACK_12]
BO_ 332 S0_NODE_PRESENCE_12: 8 NODE12
 SG_ payload_b0 : 0|8@1+ (1,0) [0|255] "raw"  MASTER,NODE1,NODE2,NODE3,NODE4,NODE5,NODE6,NODE7,NODE8,NODE9,NODE10,NODE11,NODE12,NODE13,NODE14,NODE15,NODE16,TOOL
 SG_ payload_b1 : 8|8@1+ (1,0) [0|255] "raw"  MASTER,NODE1,NODE2,NODE3,NODE4,NODE5,NODE6,NODE7,NODE8,NODE9,NODE10,NODE11,NODE12,NODE13,NODE14,NODE15,NODE16,TOOL
 SG_ payload_b2 : 16|8@1+ (1,0) [0|255] "raw"  MASTER,NODE1,NODE2,NODE3,NODE4,NODE5,NODE6,NODE7,NODE8,NODE9,NODE10,NODE11,NODE12,NODE13,NODE14,NODE15,NODE16,TOOL
 SG_ payload_b3 : 24|8@1+ (1,0) [0|255] "raw"  MASTER,NODE1,NODE2,NODE3,NODE4,NODE5,NODE6,NODE7,NODE8,NODE9,NODE10,NODE11,NODE12,NODE13,NODE14,NODE15,NODE16,TOOL
 SG_ payload_b4 : 32|8@1+ (1,0) [0|255] "raw"  MASTER,NODE1,NODE2,NODE3,NODE4,NODE5,NODE6,NODE7,NODE8,NODE9,NODE10,NODE11,NODE12,NODE13,NODE14,NODE15,NODE16,TOOL
 SG_ payload_b5 : 40|8@1+ (1,0) [0|255] "raw"  MASTER,NODE1,NODE2,NODE3,NODE4,NODE5,NODE6,NODE7,NODE8,NODE9,NODE10,NODE11,NODE12,NODE13,NODE14,NODE15,NODE16,TOOL
 SG_ payload_b6 : 48|8@1+ (1,0) [0|255] "raw"  MASTER,NODE1,NODE2,NODE3,NODE4,NODE5,NODE6,NODE7,NODE8,NODE9,NODE10,NODE11,NODE12,NODE13,NODE14,NODE15,NODE16,TOOL
 SG_ payload_b7 : 56|8@1+ (1,0) [0|255] "raw"  MASTER,NODE1,NODE2,NODE3,NODE4,NODE5,NODE6,NODE7,NODE8,NODE9,NODE10,NODE11,NODE12,NODE13,NODE14,NODE15,NODE16,TOOL

BO_ 364 S0_NODE_CFG_ACK_12: 8 NODE12
 SG_ payload_b0 : 0|8@1+ (1,0) [0|255] "raw"  MASTER,NODE1,NODE2,NODE3,NODE4,NODE5,NODE6,NODE7,NODE8,NODE9,NODE10,NODE11,NODE12,NODE13,NODE14,NODE15,NODE16,TOOL
 SG_ payload_b1 : 8|8@1+ (1,0) [0|255] "raw"  MASTER,NODE1,NODE2,NODE3,NODE4,NODE5,NODE6,NODE7,NODE8,NODE9,NODE10,NODE11,NODE12,NODE13,NODE14,NODE15,NODE16,TOOL
 SG_ payload_b2 : 16|8@1+ (1,0) [0|255] "raw"  MASTER,NODE1,NODE2,NODE3,NODE4,NODE5,NODE6,NODE7,NODE8,NODE9,NODE10,NODE11,NODE12,NODE13,NODE14,NODE15,NODE16,TOOL
 SG_ payload_b3 : 24|8@1+ (1,0) [0|255] "raw"  MASTER,NODE1,NODE2,NODE3,NODE4,NODE5,NODE6,NODE7,NODE8,NODE9,NODE10,NODE11,NODE12,NODE13,NODE14,NODE15,NODE16,TOOL
 SG_ payload_b4 : 32|8@1+ (1,0) [0|255] "raw"  MASTER,NODE1,NODE2,NODE3,NODE4,NODE5,NODE6,NODE7,NODE8,NODE9,NODE10,NODE11,NODE12,NODE13,NODE14,NODE15,NODE16,TOOL
 SG_ payload_b5 : 40|8@1+ (1,0) [0|255] "raw"  MASTER,NODE1,NODE2,NODE3,NODE4,NODE5,NODE6,NODE7,NODE8,NODE9,NODE10,NODE11,NODE12,NODE13,NODE14,NODE15,NODE16,TOOL
 SG_ payload_b6 : 48|8@1+ (1,0) [0|255] "raw"  MASTER,NODE1,NODE2,NODE3,NODE4,NODE5,NODE6,NODE7,NODE8,NODE9,NODE10,NODE11,NODE12,NODE13,NODE14,NODE15,NODE16,TOOL
 SG_ payload_b7 : 56|8@1+ (1,0) [0|255] "raw"  MASTER,NODE1,NODE2,NODE3,NODE4,NODE5,NODE6,NODE7,NODE8,NODE9,NODE10,NODE11,NODE12,NODE13,NODE14,NODE15,NODE16,TOOL

BO_ 396 S0_NODE_STATUS_FAST_12: 8 NODE12
 SG_ status_flags : 0|8@1+ (1,0) [0|255] "bitfield"  MASTER,NODE1,NODE2,NODE3,NODE4,NODE5,NODE6,NODE7,NODE8,NODE9,NODE10,NODE11,NODE12,NODE13,NODE14,NODE15,NODE16,TOOL
 SG_ error_code : 8|8@1+ (1,0) [0|255] ""  MASTER,NODE1,NODE2,NODE3,NODE4,NODE5,NODE6,NODE7,NODE8,NODE9,NODE10,NODE11,NODE12,NODE13,NODE14,NODE15,NODE16,TOOL
 SG_ actual_rpm : 16|16@1- (0.1,0) [-3276.8|3276.7] "rpm"  MASTER,NODE1,NODE2,NODE3,NODE4,NODE5,NODE6,NODE7,NODE8,NODE9,NODE10,NODE11,NODE12,NODE13,NODE14,NODE15,NODE16,TOOL
 SG_ actual_pos : 32|16@1+ (1.52587890625e-05,0) [0|0.9999847412109375] "rev"  MASTER,NODE1,NODE2,NODE3,NODE4,NODE5,NODE6,NODE7,NODE8,NODE9,NODE10,NODE11,NODE12,NODE13,NODE14,NODE15,NODE16,TOOL
 SG_ alive_counter : 48|8@1+ (1,0) [0|255] ""  MASTER,NODE1,NODE2,NODE3,NODE4,NODE5,NODE6,NODE7,NODE8,NODE9,NODE10,NODE11,NODE12,NODE13,NODE14,NODE15,NODE16,TOOL
 SG_ sync_error : 56|8@1- (0.00390625,0) [-0.5|0.49609375] "rev"  MASTER,NODE1,NODE2,NODE3,NODE4,NODE5,NODE6,NODE7,NODE8,NODE9,NODE10,NODE11,NODE12,NODE13,NODE14,NODE15,NODE16,TOOL

BO_ 460 S0_NODE_DIAG_12: 8 NODE12
 SG_ bus_voltage : 0|16@1+ (0.1,0) [0|6553.5] "V"  MASTER,NODE1,NODE2,NODE3,NODE4,NODE5,NODE6,NODE7,NODE8,NODE9,NODE10,NODE11,NODE12,NODE13,NODE14,NODE15,NODE16,TOOL
 SG_ motor_current : 16|16@1- (0.1,0) [-3276.8|3276.7] "A"  MASTER,NODE1,NODE2,NODE3,NODE4,NODE5,NODE6,NODE7,NODE8,NODE9,NODE10,NODE11,NODE12,NODE13,NODE14,NODE15,NODE16,TOOL
 SG_ controller_temp : 32|8@1- (1,0) [-128|127] "degC"  MASTER,NODE1,NODE2,NODE3,NODE4,NODE5,NODE6,NODE7,NODE8,NODE9,NODE10,NODE11,NODE12,NODE13,NODE14,NODE15,NODE16,TOOL
 SG_ motor_temp : 40|8@1- (1,0) [-128|127] "degC"  MASTER,NODE1,NODE2,NODE3,NODE4,NODE5,NODE6,NODE7,NODE8,NODE9,NODE10,NODE11,NODE12,NODE13,NODE14,NODE15,NODE16,TOOL
 SG_ fault_flags : 48|8@1+ (1,0) [0|255] "bitfield"  MASTER,NODE1,NODE2,NODE3,NODE4,NODE5,NODE6,NODE7,NODE8,NODE9,NODE10,NODE11,NODE12,NODE13,NODE14,NODE15,NODE16,TOOL
 SG_ warning_flags : 56|8@1+ (1,0) [0|255] "bitfield"  MASTER,NODE1,NODE2,NODE3,NODE4,NODE5,NODE6,NODE7,NODE8,NODE9,NODE10,NODE11,NODE12,NODE13,NODE14,NODE15,NODE16,TOOL

BO_ 269 S0_NODE_CMD_13: 8 MASTER
 SG_ node_command : 0|8@1+ (1,0) [0|255] ""  MASTER,NODE1,NODE2,NODE3,NODE4,NODE5,NODE6,NODE7,NODE8,NODE9,NODE10,NODE11,NODE12,NODE13,NODE14,NODE15,NODE16,TOOL
 SG_ node_flags : 8|8@1+ (1,0) [0|255] "bitfield"  MASTER,NODE1,NODE2,NODE3,NODE4,NODE5,NODE6,NODE7,NODE8,NODE9,NODE10,NODE11,NODE12,NODE13,NODE14,NODE15,NODE16,TOOL
 SG_ trim_rpm : 16|16@1- (0.1,0) [-3276.8|3276.7] "rpm"  MASTER,NODE1,NODE2,NODE3,NODE4,NODE5,NODE6,NODE7,NODE8,NODE9,NODE10,NODE11,NODE12,NODE13,NODE14,NODE15,NODE16,TOOL
 SG_ section_mask : 32|16@1+ (1,0) [0|65535] "bitmask"  MASTER,NODE1,NODE2,NODE3,NODE4,NODE5,NODE6,NODE7,NODE8,NODE9,NODE10,NODE11,NODE12,NODE13,NODE14,NODE15,NODE16,TOOL
 SG_ seq : 48|8@1+ (1,0) [0|255] ""  MASTER,NODE1,NODE2,NODE3,NODE4,NODE5,NODE6,NODE7,NODE8,NODE9,NODE10,NODE11,NODE12,NODE13,NODE14,NODE15,NODE16,TOOL
 SG_ reserved : 56|8@1+ (1,0) [0|255] ""  MASTER,NODE1,NODE2,NODE3,NODE4,NODE5,NODE6,NODE7,NODE8,NODE9,NODE10,NODE11,NODE12,NODE13,NODE14,NODE15,NODE16,TOOL

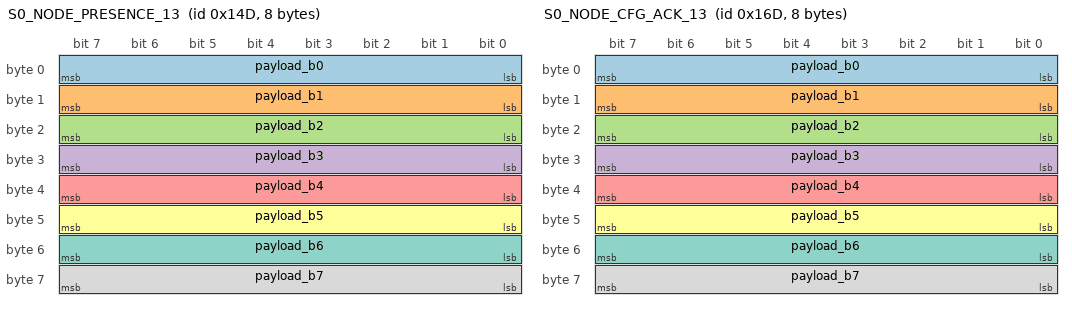
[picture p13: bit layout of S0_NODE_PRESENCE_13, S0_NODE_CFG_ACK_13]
BO_ 333 S0_NODE_PRESENCE_13: 8 NODE13
 SG_ payload_b0 : 0|8@1+ (1,0) [0|255] "raw"  MASTER,NODE1,NODE2,NODE3,NODE4,NODE5,NODE6,NODE7,NODE8,NODE9,NODE10,NODE11,NODE12,NODE13,NODE14,NODE15,NODE16,TOOL
 SG_ payload_b1 : 8|8@1+ (1,0) [0|255] "raw"  MASTER,NODE1,NODE2,NODE3,NODE4,NODE5,NODE6,NODE7,NODE8,NODE9,NODE10,NODE11,NODE12,NODE13,NODE14,NODE15,NODE16,TOOL
 SG_ payload_b2 : 16|8@1+ (1,0) [0|255] "raw"  MASTER,NODE1,NODE2,NODE3,NODE4,NODE5,NODE6,NODE7,NODE8,NODE9,NODE10,NODE11,NODE12,NODE13,NODE14,NODE15,NODE16,TOOL
 SG_ payload_b3 : 24|8@1+ (1,0) [0|255] "raw"  MASTER,NODE1,NODE2,NODE3,NODE4,NODE5,NODE6,NODE7,NODE8,NODE9,NODE10,NODE11,NODE12,NODE13,NODE14,NODE15,NODE16,TOOL
 SG_ payload_b4 : 32|8@1+ (1,0) [0|255] "raw"  MASTER,NODE1,NODE2,NODE3,NODE4,NODE5,NODE6,NODE7,NODE8,NODE9,NODE10,NODE11,NODE12,NODE13,NODE14,NODE15,NODE16,TOOL
 SG_ payload_b5 : 40|8@1+ (1,0) [0|255] "raw"  MASTER,NODE1,NODE2,NODE3,NODE4,NODE5,NODE6,NODE7,NODE8,NODE9,NODE10,NODE11,NODE12,NODE13,NODE14,NODE15,NODE16,TOOL
 SG_ payload_b6 : 48|8@1+ (1,0) [0|255] "raw"  MASTER,NODE1,NODE2,NODE3,NODE4,NODE5,NODE6,NODE7,NODE8,NODE9,NODE10,NODE11,NODE12,NODE13,NODE14,NODE15,NODE16,TOOL
 SG_ payload_b7 : 56|8@1+ (1,0) [0|255] "raw"  MASTER,NODE1,NODE2,NODE3,NODE4,NODE5,NODE6,NODE7,NODE8,NODE9,NODE10,NODE11,NODE12,NODE13,NODE14,NODE15,NODE16,TOOL

BO_ 365 S0_NODE_CFG_ACK_13: 8 NODE13
 SG_ payload_b0 : 0|8@1+ (1,0) [0|255] "raw"  MASTER,NODE1,NODE2,NODE3,NODE4,NODE5,NODE6,NODE7,NODE8,NODE9,NODE10,NODE11,NODE12,NODE13,NODE14,NODE15,NODE16,TOOL
 SG_ payload_b1 : 8|8@1+ (1,0) [0|255] "raw"  MASTER,NODE1,NODE2,NODE3,NODE4,NODE5,NODE6,NODE7,NODE8,NODE9,NODE10,NODE11,NODE12,NODE13,NODE14,NODE15,NODE16,TOOL
 SG_ payload_b2 : 16|8@1+ (1,0) [0|255] "raw"  MASTER,NODE1,NODE2,NODE3,NODE4,NODE5,NODE6,NODE7,NODE8,NODE9,NODE10,NODE11,NODE12,NODE13,NODE14,NODE15,NODE16,TOOL
 SG_ payload_b3 : 24|8@1+ (1,0) [0|255] "raw"  MASTER,NODE1,NODE2,NODE3,NODE4,NODE5,NODE6,NODE7,NODE8,NODE9,NODE10,NODE11,NODE12,NODE13,NODE14,NODE15,NODE16,TOOL
 SG_ payload_b4 : 32|8@1+ (1,0) [0|255] "raw"  MASTER,NODE1,NODE2,NODE3,NODE4,NODE5,NODE6,NODE7,NODE8,NODE9,NODE10,NODE11,NODE12,NODE13,NODE14,NODE15,NODE16,TOOL
 SG_ payload_b5 : 40|8@1+ (1,0) [0|255] "raw"  MASTER,NODE1,NODE2,NODE3,NODE4,NODE5,NODE6,NODE7,NODE8,NODE9,NODE10,NODE11,NODE12,NODE13,NODE14,NODE15,NODE16,TOOL
 SG_ payload_b6 : 48|8@1+ (1,0) [0|255] "raw"  MASTER,NODE1,NODE2,NODE3,NODE4,NODE5,NODE6,NODE7,NODE8,NODE9,NODE10,NODE11,NODE12,NODE13,NODE14,NODE15,NODE16,TOOL
 SG_ payload_b7 : 56|8@1+ (1,0) [0|255] "raw"  MASTER,NODE1,NODE2,NODE3,NODE4,NODE5,NODE6,NODE7,NODE8,NODE9,NODE10,NODE11,NODE12,NODE13,NODE14,NODE15,NODE16,TOOL

BO_ 397 S0_NODE_STATUS_FAST_13: 8 NODE13
 SG_ status_flags : 0|8@1+ (1,0) [0|255] "bitfield"  MASTER,NODE1,NODE2,NODE3,NODE4,NODE5,NODE6,NODE7,NODE8,NODE9,NODE10,NODE11,NODE12,NODE13,NODE14,NODE15,NODE16,TOOL
 SG_ error_code : 8|8@1+ (1,0) [0|255] ""  MASTER,NODE1,NODE2,NODE3,NODE4,NODE5,NODE6,NODE7,NODE8,NODE9,NODE10,NODE11,NODE12,NODE13,NODE14,NODE15,NODE16,TOOL
 SG_ actual_rpm : 16|16@1- (0.1,0) [-3276.8|3276.7] "rpm"  MASTER,NODE1,NODE2,NODE3,NODE4,NODE5,NODE6,NODE7,NODE8,NODE9,NODE10,NODE11,NODE12,NODE13,NODE14,NODE15,NODE16,TOOL
 SG_ actual_pos : 32|16@1+ (1.52587890625e-05,0) [0|0.9999847412109375] "rev"  MASTER,NODE1,NODE2,NODE3,NODE4,NODE5,NODE6,NODE7,NODE8,NODE9,NODE10,NODE11,NODE12,NODE13,NODE14,NODE15,NODE16,TOOL
 SG_ alive_counter : 48|8@1+ (1,0) [0|255] ""  MASTER,NODE1,NODE2,NODE3,NODE4,NODE5,NODE6,NODE7,NODE8,NODE9,NODE10,NODE11,NODE12,NODE13,NODE14,NODE15,NODE16,TOOL
 SG_ sync_error : 56|8@1- (0.00390625,0) [-0.5|0.49609375] "rev"  MASTER,NODE1,NODE2,NODE3,NODE4,NODE5,NODE6,NODE7,NODE8,NODE9,NODE10,NODE11,NODE12,NODE13,NODE14,NODE15,NODE16,TOOL

BO_ 461 S0_NODE_DIAG_13: 8 NODE13
 SG_ bus_voltage : 0|16@1+ (0.1,0) [0|6553.5] "V"  MASTER,NODE1,NODE2,NODE3,NODE4,NODE5,NODE6,NODE7,NODE8,NODE9,NODE10,NODE11,NODE12,NODE13,NODE14,NODE15,NODE16,TOOL
 SG_ motor_current : 16|16@1- (0.1,0) [-3276.8|3276.7] "A"  MASTER,NODE1,NODE2,NODE3,NODE4,NODE5,NODE6,NODE7,NODE8,NODE9,NODE10,NODE11,NODE12,NODE13,NODE14,NODE15,NODE16,TOOL
 SG_ controller_temp : 32|8@1- (1,0) [-128|127] "degC"  MASTER,NODE1,NODE2,NODE3,NODE4,NODE5,NODE6,NODE7,NODE8,NODE9,NODE10,NODE11,NODE12,NODE13,NODE14,NODE15,NODE16,TOOL
 SG_ motor_temp : 40|8@1- (1,0) [-128|127] "degC"  MASTER,NODE1,NODE2,NODE3,NODE4,NODE5,NODE6,NODE7,NODE8,NODE9,NODE10,NODE11,NODE12,NODE13,NODE14,NODE15,NODE16,TOOL
 SG_ fault_flags : 48|8@1+ (1,0) [0|255] "bitfield"  MASTER,NODE1,NODE2,NODE3,NODE4,NODE5,NODE6,NODE7,NODE8,NODE9,NODE10,NODE11,NODE12,NODE13,NODE14,NODE15,NODE16,TOOL
 SG_ warning_flags : 56|8@1+ (1,0) [0|255] "bitfield"  MASTER,NODE1,NODE2,NODE3,NODE4,NODE5,NODE6,NODE7,NODE8,NODE9,NODE10,NODE11,NODE12,NODE13,NODE14,NODE15,NODE16,TOOL

BO_ 270 S0_NODE_CMD_14: 8 MASTER
 SG_ node_command : 0|8@1+ (1,0) [0|255] ""  MASTER,NODE1,NODE2,NODE3,NODE4,NODE5,NODE6,NODE7,NODE8,NODE9,NODE10,NODE11,NODE12,NODE13,NODE14,NODE15,NODE16,TOOL
 SG_ node_flags : 8|8@1+ (1,0) [0|255] "bitfield"  MASTER,NODE1,NODE2,NODE3,NODE4,NODE5,NODE6,NODE7,NODE8,NODE9,NODE10,NODE11,NODE12,NODE13,NODE14,NODE15,NODE16,TOOL
 SG_ trim_rpm : 16|16@1- (0.1,0) [-3276.8|3276.7] "rpm"  MASTER,NODE1,NODE2,NODE3,NODE4,NODE5,NODE6,NODE7,NODE8,NODE9,NODE10,NODE11,NODE12,NODE13,NODE14,NODE15,NODE16,TOOL
 SG_ section_mask : 32|16@1+ (1,0) [0|65535] "bitmask"  MASTER,NODE1,NODE2,NODE3,NODE4,NODE5,NODE6,NODE7,NODE8,NODE9,NODE10,NODE11,NODE12,NODE13,NODE14,NODE15,NODE16,TOOL
 SG_ seq : 48|8@1+ (1,0) [0|255] ""  MASTER,NODE1,NODE2,NODE3,NODE4,NODE5,NODE6,NODE7,NODE8,NODE9,NODE10,NODE11,NODE12,NODE13,NODE14,NODE15,NODE16,TOOL
 SG_ reserved : 56|8@1+ (1,0) [0|255] ""  MASTER,NODE1,NODE2,NODE3,NODE4,NODE5,NODE6,NODE7,NODE8,NODE9,NODE10,NODE11,NODE12,NODE13,NODE14,NODE15,NODE16,TOOL

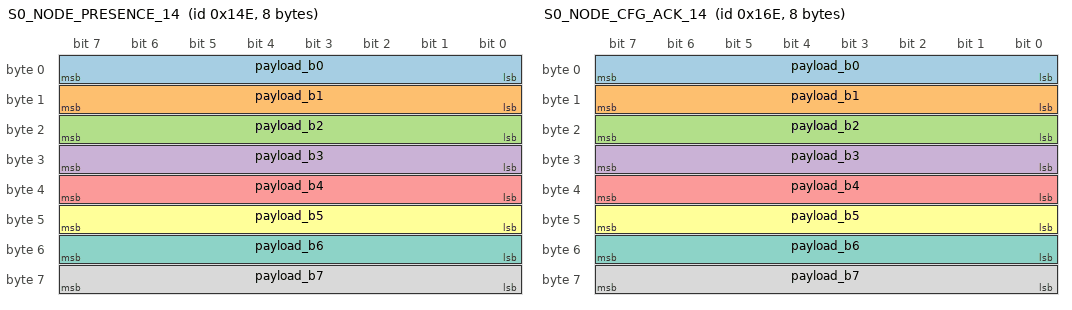
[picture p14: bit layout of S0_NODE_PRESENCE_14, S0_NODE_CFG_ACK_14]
BO_ 334 S0_NODE_PRESENCE_14: 8 NODE14
 SG_ payload_b0 : 0|8@1+ (1,0) [0|255] "raw"  MASTER,NODE1,NODE2,NODE3,NODE4,NODE5,NODE6,NODE7,NODE8,NODE9,NODE10,NODE11,NODE12,NODE13,NODE14,NODE15,NODE16,TOOL
 SG_ payload_b1 : 8|8@1+ (1,0) [0|255] "raw"  MASTER,NODE1,NODE2,NODE3,NODE4,NODE5,NODE6,NODE7,NODE8,NODE9,NODE10,NODE11,NODE12,NODE13,NODE14,NODE15,NODE16,TOOL
 SG_ payload_b2 : 16|8@1+ (1,0) [0|255] "raw"  MASTER,NODE1,NODE2,NODE3,NODE4,NODE5,NODE6,NODE7,NODE8,NODE9,NODE10,NODE11,NODE12,NODE13,NODE14,NODE15,NODE16,TOOL
 SG_ payload_b3 : 24|8@1+ (1,0) [0|255] "raw"  MASTER,NODE1,NODE2,NODE3,NODE4,NODE5,NODE6,NODE7,NODE8,NODE9,NODE10,NODE11,NODE12,NODE13,NODE14,NODE15,NODE16,TOOL
 SG_ payload_b4 : 32|8@1+ (1,0) [0|255] "raw"  MASTER,NODE1,NODE2,NODE3,NODE4,NODE5,NODE6,NODE7,NODE8,NODE9,NODE10,NODE11,NODE12,NODE13,NODE14,NODE15,NODE16,TOOL
 SG_ payload_b5 : 40|8@1+ (1,0) [0|255] "raw"  MASTER,NODE1,NODE2,NODE3,NODE4,NODE5,NODE6,NODE7,NODE8,NODE9,NODE10,NODE11,NODE12,NODE13,NODE14,NODE15,NODE16,TOOL
 SG_ payload_b6 : 48|8@1+ (1,0) [0|255] "raw"  MASTER,NODE1,NODE2,NODE3,NODE4,NODE5,NODE6,NODE7,NODE8,NODE9,NODE10,NODE11,NODE12,NODE13,NODE14,NODE15,NODE16,TOOL
 SG_ payload_b7 : 56|8@1+ (1,0) [0|255] "raw"  MASTER,NODE1,NODE2,NODE3,NODE4,NODE5,NODE6,NODE7,NODE8,NODE9,NODE10,NODE11,NODE12,NODE13,NODE14,NODE15,NODE16,TOOL

BO_ 366 S0_NODE_CFG_ACK_14: 8 NODE14
 SG_ payload_b0 : 0|8@1+ (1,0) [0|255] "raw"  MASTER,NODE1,NODE2,NODE3,NODE4,NODE5,NODE6,NODE7,NODE8,NODE9,NODE10,NODE11,NODE12,NODE13,NODE14,NODE15,NODE16,TOOL
 SG_ payload_b1 : 8|8@1+ (1,0) [0|255] "raw"  MASTER,NODE1,NODE2,NODE3,NODE4,NODE5,NODE6,NODE7,NODE8,NODE9,NODE10,NODE11,NODE12,NODE13,NODE14,NODE15,NODE16,TOOL
 SG_ payload_b2 : 16|8@1+ (1,0) [0|255] "raw"  MASTER,NODE1,NODE2,NODE3,NODE4,NODE5,NODE6,NODE7,NODE8,NODE9,NODE10,NODE11,NODE12,NODE13,NODE14,NODE15,NODE16,TOOL
 SG_ payload_b3 : 24|8@1+ (1,0) [0|255] "raw"  MASTER,NODE1,NODE2,NODE3,NODE4,NODE5,NODE6,NODE7,NODE8,NODE9,NODE10,NODE11,NODE12,NODE13,NODE14,NODE15,NODE16,TOOL
 SG_ payload_b4 : 32|8@1+ (1,0) [0|255] "raw"  MASTER,NODE1,NODE2,NODE3,NODE4,NODE5,NODE6,NODE7,NODE8,NODE9,NODE10,NODE11,NODE12,NODE13,NODE14,NODE15,NODE16,TOOL
 SG_ payload_b5 : 40|8@1+ (1,0) [0|255] "raw"  MASTER,NODE1,NODE2,NODE3,NODE4,NODE5,NODE6,NODE7,NODE8,NODE9,NODE10,NODE11,NODE12,NODE13,NODE14,NODE15,NODE16,TOOL
 SG_ payload_b6 : 48|8@1+ (1,0) [0|255] "raw"  MASTER,NODE1,NODE2,NODE3,NODE4,NODE5,NODE6,NODE7,NODE8,NODE9,NODE10,NODE11,NODE12,NODE13,NODE14,NODE15,NODE16,TOOL
 SG_ payload_b7 : 56|8@1+ (1,0) [0|255] "raw"  MASTER,NODE1,NODE2,NODE3,NODE4,NODE5,NODE6,NODE7,NODE8,NODE9,NODE10,NODE11,NODE12,NODE13,NODE14,NODE15,NODE16,TOOL

BO_ 398 S0_NODE_STATUS_FAST_14: 8 NODE14
 SG_ status_flags : 0|8@1+ (1,0) [0|255] "bitfield"  MASTER,NODE1,NODE2,NODE3,NODE4,NODE5,NODE6,NODE7,NODE8,NODE9,NODE10,NODE11,NODE12,NODE13,NODE14,NODE15,NODE16,TOOL
 SG_ error_code : 8|8@1+ (1,0) [0|255] ""  MASTER,NODE1,NODE2,NODE3,NODE4,NODE5,NODE6,NODE7,NODE8,NODE9,NODE10,NODE11,NODE12,NODE13,NODE14,NODE15,NODE16,TOOL
 SG_ actual_rpm : 16|16@1- (0.1,0) [-3276.8|3276.7] "rpm"  MASTER,NODE1,NODE2,NODE3,NODE4,NODE5,NODE6,NODE7,NODE8,NODE9,NODE10,NODE11,NODE12,NODE13,NODE14,NODE15,NODE16,TOOL
 SG_ actual_pos : 32|16@1+ (1.52587890625e-05,0) [0|0.9999847412109375] "rev"  MASTER,NODE1,NODE2,NODE3,NODE4,NODE5,NODE6,NODE7,NODE8,NODE9,NODE10,NODE11,NODE12,NODE13,NODE14,NODE15,NODE16,TOOL
 SG_ alive_counter : 48|8@1+ (1,0) [0|255] ""  MASTER,NODE1,NODE2,NODE3,NODE4,NODE5,NODE6,NODE7,NODE8,NODE9,NODE10,NODE11,NODE12,NODE13,NODE14,NODE15,NODE16,TOOL
 SG_ sync_error : 56|8@1- (0.00390625,0) [-0.5|0.49609375] "rev"  MASTER,NODE1,NODE2,NODE3,NODE4,NODE5,NODE6,NODE7,NODE8,NODE9,NODE10,NODE11,NODE12,NODE13,NODE14,NODE15,NODE16,TOOL

BO_ 462 S0_NODE_DIAG_14: 8 NODE14
 SG_ bus_voltage : 0|16@1+ (0.1,0) [0|6553.5] "V"  MASTER,NODE1,NODE2,NODE3,NODE4,NODE5,NODE6,NODE7,NODE8,NODE9,NODE10,NODE11,NODE12,NODE13,NODE14,NODE15,NODE16,TOOL
 SG_ motor_current : 16|16@1- (0.1,0) [-3276.8|3276.7] "A"  MASTER,NODE1,NODE2,NODE3,NODE4,NODE5,NODE6,NODE7,NODE8,NODE9,NODE10,NODE11,NODE12,NODE13,NODE14,NODE15,NODE16,TOOL
 SG_ controller_temp : 32|8@1- (1,0) [-128|127] "degC"  MASTER,NODE1,NODE2,NODE3,NODE4,NODE5,NODE6,NODE7,NODE8,NODE9,NODE10,NODE11,NODE12,NODE13,NODE14,NODE15,NODE16,TOOL
 SG_ motor_temp : 40|8@1- (1,0) [-128|127] "degC"  MASTER,NODE1,NODE2,NODE3,NODE4,NODE5,NODE6,NODE7,NODE8,NODE9,NODE10,NODE11,NODE12,NODE13,NODE14,NODE15,NODE16,TOOL
 SG_ fault_flags : 48|8@1+ (1,0) [0|255] "bitfield"  MASTER,NODE1,NODE2,NODE3,NODE4,NODE5,NODE6,NODE7,NODE8,NODE9,NODE10,NODE11,NODE12,NODE13,NODE14,NODE15,NODE16,TOOL
 SG_ warning_flags : 56|8@1+ (1,0) [0|255] "bitfield"  MASTER,NODE1,NODE2,NODE3,NODE4,NODE5,NODE6,NODE7,NODE8,NODE9,NODE10,NODE11,NODE12,NODE13,NODE14,NODE15,NODE16,TOOL

BO_ 271 S0_NODE_CMD_15: 8 MASTER
 SG_ node_command : 0|8@1+ (1,0) [0|255] ""  MASTER,NODE1,NODE2,NODE3,NODE4,NODE5,NODE6,NODE7,NODE8,NODE9,NODE10,NODE11,NODE12,NODE13,NODE14,NODE15,NODE16,TOOL
 SG_ node_flags : 8|8@1+ (1,0) [0|255] "bitfield"  MASTER,NODE1,NODE2,NODE3,NODE4,NODE5,NODE6,NODE7,NODE8,NODE9,NODE10,NODE11,NODE12,NODE13,NODE14,NODE15,NODE16,TOOL
 SG_ trim_rpm : 16|16@1- (0.1,0) [-3276.8|3276.7] "rpm"  MASTER,NODE1,NODE2,NODE3,NODE4,NODE5,NODE6,NODE7,NODE8,NODE9,NODE10,NODE11,NODE12,NODE13,NODE14,NODE15,NODE16,TOOL
 SG_ section_mask : 32|16@1+ (1,0) [0|65535] "bitmask"  MASTER,NODE1,NODE2,NODE3,NODE4,NODE5,NODE6,NODE7,NODE8,NODE9,NODE10,NODE11,NODE12,NODE13,NODE14,NODE15,NODE16,TOOL
 SG_ seq : 48|8@1+ (1,0) [0|255] ""  MASTER,NODE1,NODE2,NODE3,NODE4,NODE5,NODE6,NODE7,NODE8,NODE9,NODE10,NODE11,NODE12,NODE13,NODE14,NODE15,NODE16,TOOL
 SG_ reserved : 56|8@1+ (1,0) [0|255] ""  MASTER,NODE1,NODE2,NODE3,NODE4,NODE5,NODE6,NODE7,NODE8,NODE9,NODE10,NODE11,NODE12,NODE13,NODE14,NODE15,NODE16,TOOL

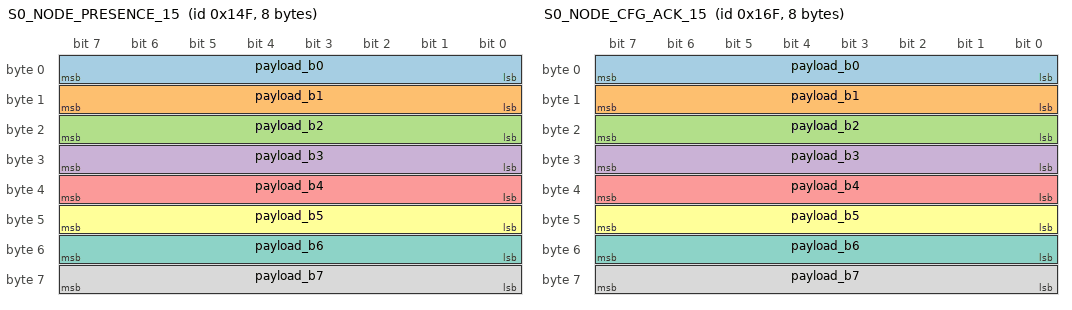
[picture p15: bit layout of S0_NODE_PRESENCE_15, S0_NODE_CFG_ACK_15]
BO_ 335 S0_NODE_PRESENCE_15: 8 NODE15
 SG_ payload_b0 : 0|8@1+ (1,0) [0|255] "raw"  MASTER,NODE1,NODE2,NODE3,NODE4,NODE5,NODE6,NODE7,NODE8,NODE9,NODE10,NODE11,NODE12,NODE13,NODE14,NODE15,NODE16,TOOL
 SG_ payload_b1 : 8|8@1+ (1,0) [0|255] "raw"  MASTER,NODE1,NODE2,NODE3,NODE4,NODE5,NODE6,NODE7,NODE8,NODE9,NODE10,NODE11,NODE12,NODE13,NODE14,NODE15,NODE16,TOOL
 SG_ payload_b2 : 16|8@1+ (1,0) [0|255] "raw"  MASTER,NODE1,NODE2,NODE3,NODE4,NODE5,NODE6,NODE7,NODE8,NODE9,NODE10,NODE11,NODE12,NODE13,NODE14,NODE15,NODE16,TOOL
 SG_ payload_b3 : 24|8@1+ (1,0) [0|255] "raw"  MASTER,NODE1,NODE2,NODE3,NODE4,NODE5,NODE6,NODE7,NODE8,NODE9,NODE10,NODE11,NODE12,NODE13,NODE14,NODE15,NODE16,TOOL
 SG_ payload_b4 : 32|8@1+ (1,0) [0|255] "raw"  MASTER,NODE1,NODE2,NODE3,NODE4,NODE5,NODE6,NODE7,NODE8,NODE9,NODE10,NODE11,NODE12,NODE13,NODE14,NODE15,NODE16,TOOL
 SG_ payload_b5 : 40|8@1+ (1,0) [0|255] "raw"  MASTER,NODE1,NODE2,NODE3,NODE4,NODE5,NODE6,NODE7,NODE8,NODE9,NODE10,NODE11,NODE12,NODE13,NODE14,NODE15,NODE16,TOOL
 SG_ payload_b6 : 48|8@1+ (1,0) [0|255] "raw"  MASTER,NODE1,NODE2,NODE3,NODE4,NODE5,NODE6,NODE7,NODE8,NODE9,NODE10,NODE11,NODE12,NODE13,NODE14,NODE15,NODE16,TOOL
 SG_ payload_b7 : 56|8@1+ (1,0) [0|255] "raw"  MASTER,NODE1,NODE2,NODE3,NODE4,NODE5,NODE6,NODE7,NODE8,NODE9,NODE10,NODE11,NODE12,NODE13,NODE14,NODE15,NODE16,TOOL

BO_ 367 S0_NODE_CFG_ACK_15: 8 NODE15
 SG_ payload_b0 : 0|8@1+ (1,0) [0|255] "raw"  MASTER,NODE1,NODE2,NODE3,NODE4,NODE5,NODE6,NODE7,NODE8,NODE9,NODE10,NODE11,NODE12,NODE13,NODE14,NODE15,NODE16,TOOL
 SG_ payload_b1 : 8|8@1+ (1,0) [0|255] "raw"  MASTER,NODE1,NODE2,NODE3,NODE4,NODE5,NODE6,NODE7,NODE8,NODE9,NODE10,NODE11,NODE12,NODE13,NODE14,NODE15,NODE16,TOOL
 SG_ payload_b2 : 16|8@1+ (1,0) [0|255] "raw"  MASTER,NODE1,NODE2,NODE3,NODE4,NODE5,NODE6,NODE7,NODE8,NODE9,NODE10,NODE11,NODE12,NODE13,NODE14,NODE15,NODE16,TOOL
 SG_ payload_b3 : 24|8@1+ (1,0) [0|255] "raw"  MASTER,NODE1,NODE2,NODE3,NODE4,NODE5,NODE6,NODE7,NODE8,NODE9,NODE10,NODE11,NODE12,NODE13,NODE14,NODE15,NODE16,TOOL
 SG_ payload_b4 : 32|8@1+ (1,0) [0|255] "raw"  MASTER,NODE1,NODE2,NODE3,NODE4,NODE5,NODE6,NODE7,NODE8,NODE9,NODE10,NODE11,NODE12,NODE13,NODE14,NODE15,NODE16,TOOL
 SG_ payload_b5 : 40|8@1+ (1,0) [0|255] "raw"  MASTER,NODE1,NODE2,NODE3,NODE4,NODE5,NODE6,NODE7,NODE8,NODE9,NODE10,NODE11,NODE12,NODE13,NODE14,NODE15,NODE16,TOOL
 SG_ payload_b6 : 48|8@1+ (1,0) [0|255] "raw"  MASTER,NODE1,NODE2,NODE3,NODE4,NODE5,NODE6,NODE7,NODE8,NODE9,NODE10,NODE11,NODE12,NODE13,NODE14,NODE15,NODE16,TOOL
 SG_ payload_b7 : 56|8@1+ (1,0) [0|255] "raw"  MASTER,NODE1,NODE2,NODE3,NODE4,NODE5,NODE6,NODE7,NODE8,NODE9,NODE10,NODE11,NODE12,NODE13,NODE14,NODE15,NODE16,TOOL

BO_ 399 S0_NODE_STATUS_FAST_15: 8 NODE15
 SG_ status_flags : 0|8@1+ (1,0) [0|255] "bitfield"  MASTER,NODE1,NODE2,NODE3,NODE4,NODE5,NODE6,NODE7,NODE8,NODE9,NODE10,NODE11,NODE12,NODE13,NODE14,NODE15,NODE16,TOOL
 SG_ error_code : 8|8@1+ (1,0) [0|255] ""  MASTER,NODE1,NODE2,NODE3,NODE4,NODE5,NODE6,NODE7,NODE8,NODE9,NODE10,NODE11,NODE12,NODE13,NODE14,NODE15,NODE16,TOOL
 SG_ actual_rpm : 16|16@1- (0.1,0) [-3276.8|3276.7] "rpm"  MASTER,NODE1,NODE2,NODE3,NODE4,NODE5,NODE6,NODE7,NODE8,NODE9,NODE10,NODE11,NODE12,NODE13,NODE14,NODE15,NODE16,TOOL
 SG_ actual_pos : 32|16@1+ (1.52587890625e-05,0) [0|0.9999847412109375] "rev"  MASTER,NODE1,NODE2,NODE3,NODE4,NODE5,NODE6,NODE7,NODE8,NODE9,NODE10,NODE11,NODE12,NODE13,NODE14,NODE15,NODE16,TOOL
 SG_ alive_counter : 48|8@1+ (1,0) [0|255] ""  MASTER,NODE1,NODE2,NODE3,NODE4,NODE5,NODE6,NODE7,NODE8,NODE9,NODE10,NODE11,NODE12,NODE13,NODE14,NODE15,NODE16,TOOL
 SG_ sync_error : 56|8@1- (0.00390625,0) [-0.5|0.49609375] "rev"  MASTER,NODE1,NODE2,NODE3,NODE4,NODE5,NODE6,NODE7,NODE8,NODE9,NODE10,NODE11,NODE12,NODE13,NODE14,NODE15,NODE16,TOOL

BO_ 463 S0_NODE_DIAG_15: 8 NODE15
 SG_ bus_voltage : 0|16@1+ (0.1,0) [0|6553.5] "V"  MASTER,NODE1,NODE2,NODE3,NODE4,NODE5,NODE6,NODE7,NODE8,NODE9,NODE10,NODE11,NODE12,NODE13,NODE14,NODE15,NODE16,TOOL
 SG_ motor_current : 16|16@1- (0.1,0) [-3276.8|3276.7] "A"  MASTER,NODE1,NODE2,NODE3,NODE4,NODE5,NODE6,NODE7,NODE8,NODE9,NODE10,NODE11,NODE12,NODE13,NODE14,NODE15,NODE16,TOOL
 SG_ controller_temp : 32|8@1- (1,0) [-128|127] "degC"  MASTER,NODE1,NODE2,NODE3,NODE4,NODE5,NODE6,NODE7,NODE8,NODE9,NODE10,NODE11,NODE12,NODE13,NODE14,NODE15,NODE16,TOOL
 SG_ motor_temp : 40|8@1- (1,0) [-128|127] "degC"  MASTER,NODE1,NODE2,NODE3,NODE4,NODE5,NODE6,NODE7,NODE8,NODE9,NODE10,NODE11,NODE12,NODE13,NODE14,NODE15,NODE16,TOOL
 SG_ fault_flags : 48|8@1+ (1,0) [0|255] "bitfield"  MASTER,NODE1,NODE2,NODE3,NODE4,NODE5,NODE6,NODE7,NODE8,NODE9,NODE10,NODE11,NODE12,NODE13,NODE14,NODE15,NODE16,TOOL
 SG_ warning_flags : 56|8@1+ (1,0) [0|255] "bitfield"  MASTER,NODE1,NODE2,NODE3,NODE4,NODE5,NODE6,NODE7,NODE8,NODE9,NODE10,NODE11,NODE12,NODE13,NODE14,NODE15,NODE16,TOOL

BO_ 272 S0_NODE_CMD_16: 8 MASTER
 SG_ node_command : 0|8@1+ (1,0) [0|255] ""  MASTER,NODE1,NODE2,NODE3,NODE4,NODE5,NODE6,NODE7,NODE8,NODE9,NODE10,NODE11,NODE12,NODE13,NODE14,NODE15,NODE16,TOOL
 SG_ node_flags : 8|8@1+ (1,0) [0|255] "bitfield"  MASTER,NODE1,NODE2,NODE3,NODE4,NODE5,NODE6,NODE7,NODE8,NODE9,NODE10,NODE11,NODE12,NODE13,NODE14,NODE15,NODE16,TOOL
 SG_ trim_rpm : 16|16@1- (0.1,0) [-3276.8|3276.7] "rpm"  MASTER,NODE1,NODE2,NODE3,NODE4,NODE5,NODE6,NODE7,NODE8,NODE9,NODE10,NODE11,NODE12,NODE13,NODE14,NODE15,NODE16,TOOL
 SG_ section_mask : 32|16@1+ (1,0) [0|65535] "bitmask"  MASTER,NODE1,NODE2,NODE3,NODE4,NODE5,NODE6,NODE7,NODE8,NODE9,NODE10,NODE11,NODE12,NODE13,NODE14,NODE15,NODE16,TOOL
 SG_ seq : 48|8@1+ (1,0) [0|255] ""  MASTER,NODE1,NODE2,NODE3,NODE4,NODE5,NODE6,NODE7,NODE8,NODE9,NODE10,NODE11,NODE12,NODE13,NODE14,NODE15,NODE16,TOOL
 SG_ reserved : 56|8@1+ (1,0) [0|255] ""  MASTER,NODE1,NODE2,NODE3,NODE4,NODE5,NODE6,NODE7,NODE8,NODE9,NODE10,NODE11,NODE12,NODE13,NODE14,NODE15,NODE16,TOOL

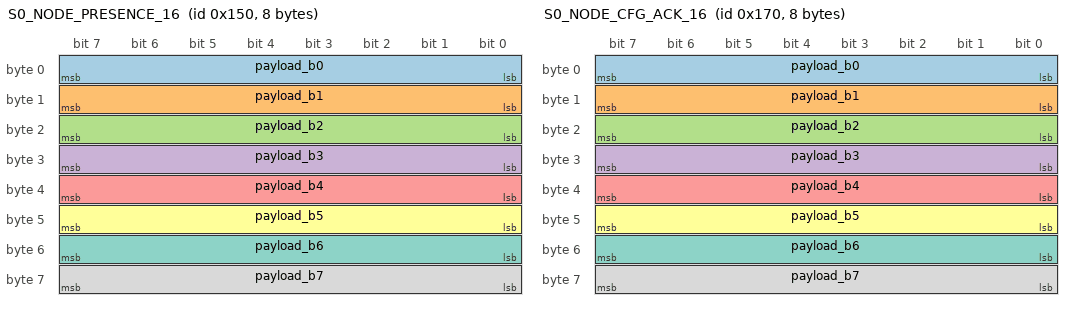
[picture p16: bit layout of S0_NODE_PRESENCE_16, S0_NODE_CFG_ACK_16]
BO_ 336 S0_NODE_PRESENCE_16: 8 NODE16
 SG_ payload_b0 : 0|8@1+ (1,0) [0|255] "raw"  MASTER,NODE1,NODE2,NODE3,NODE4,NODE5,NODE6,NODE7,NODE8,NODE9,NODE10,NODE11,NODE12,NODE13,NODE14,NODE15,NODE16,TOOL
 SG_ payload_b1 : 8|8@1+ (1,0) [0|255] "raw"  MASTER,NODE1,NODE2,NODE3,NODE4,NODE5,NODE6,NODE7,NODE8,NODE9,NODE10,NODE11,NODE12,NODE13,NODE14,NODE15,NODE16,TOOL
 SG_ payload_b2 : 16|8@1+ (1,0) [0|255] "raw"  MASTER,NODE1,NODE2,NODE3,NODE4,NODE5,NODE6,NODE7,NODE8,NODE9,NODE10,NODE11,NODE12,NODE13,NODE14,NODE15,NODE16,TOOL
 SG_ payload_b3 : 24|8@1+ (1,0) [0|255] "raw"  MASTER,NODE1,NODE2,NODE3,NODE4,NODE5,NODE6,NODE7,NODE8,NODE9,NODE10,NODE11,NODE12,NODE13,NODE14,NODE15,NODE16,TOOL
 SG_ payload_b4 : 32|8@1+ (1,0) [0|255] "raw"  MASTER,NODE1,NODE2,NODE3,NODE4,NODE5,NODE6,NODE7,NODE8,NODE9,NODE10,NODE11,NODE12,NODE13,NODE14,NODE15,NODE16,TOOL
 SG_ payload_b5 : 40|8@1+ (1,0) [0|255] "raw"  MASTER,NODE1,NODE2,NODE3,NODE4,NODE5,NODE6,NODE7,NODE8,NODE9,NODE10,NODE11,NODE12,NODE13,NODE14,NODE15,NODE16,TOOL
 SG_ payload_b6 : 48|8@1+ (1,0) [0|255] "raw"  MASTER,NODE1,NODE2,NODE3,NODE4,NODE5,NODE6,NODE7,NODE8,NODE9,NODE10,NODE11,NODE12,NODE13,NODE14,NODE15,NODE16,TOOL
 SG_ payload_b7 : 56|8@1+ (1,0) [0|255] "raw"  MASTER,NODE1,NODE2,NODE3,NODE4,NODE5,NODE6,NODE7,NODE8,NODE9,NODE10,NODE11,NODE12,NODE13,NODE14,NODE15,NODE16,TOOL

BO_ 368 S0_NODE_CFG_ACK_16: 8 NODE16
 SG_ payload_b0 : 0|8@1+ (1,0) [0|255] "raw"  MASTER,NODE1,NODE2,NODE3,NODE4,NODE5,NODE6,NODE7,NODE8,NODE9,NODE10,NODE11,NODE12,NODE13,NODE14,NODE15,NODE16,TOOL
 SG_ payload_b1 : 8|8@1+ (1,0) [0|255] "raw"  MASTER,NODE1,NODE2,NODE3,NODE4,NODE5,NODE6,NODE7,NODE8,NODE9,NODE10,NODE11,NODE12,NODE13,NODE14,NODE15,NODE16,TOOL
 SG_ payload_b2 : 16|8@1+ (1,0) [0|255] "raw"  MASTER,NODE1,NODE2,NODE3,NODE4,NODE5,NODE6,NODE7,NODE8,NODE9,NODE10,NODE11,NODE12,NODE13,NODE14,NODE15,NODE16,TOOL
 SG_ payload_b3 : 24|8@1+ (1,0) [0|255] "raw"  MASTER,NODE1,NODE2,NODE3,NODE4,NODE5,NODE6,NODE7,NODE8,NODE9,NODE10,NODE11,NODE12,NODE13,NODE14,NODE15,NODE16,TOOL
 SG_ payload_b4 : 32|8@1+ (1,0) [0|255] "raw"  MASTER,NODE1,NODE2,NODE3,NODE4,NODE5,NODE6,NODE7,NODE8,NODE9,NODE10,NODE11,NODE12,NODE13,NODE14,NODE15,NODE16,TOOL
 SG_ payload_b5 : 40|8@1+ (1,0) [0|255] "raw"  MASTER,NODE1,NODE2,NODE3,NODE4,NODE5,NODE6,NODE7,NODE8,NODE9,NODE10,NODE11,NODE12,NODE13,NODE14,NODE15,NODE16,TOOL
 SG_ payload_b6 : 48|8@1+ (1,0) [0|255] "raw"  MASTER,NODE1,NODE2,NODE3,NODE4,NODE5,NODE6,NODE7,NODE8,NODE9,NODE10,NODE11,NODE12,NODE13,NODE14,NODE15,NODE16,TOOL
 SG_ payload_b7 : 56|8@1+ (1,0) [0|255] "raw"  MASTER,NODE1,NODE2,NODE3,NODE4,NODE5,NODE6,NODE7,NODE8,NODE9,NODE10,NODE11,NODE12,NODE13,NODE14,NODE15,NODE16,TOOL

BO_ 400 S0_NODE_STATUS_FAST_16: 8 NODE16
 SG_ status_flags : 0|8@1+ (1,0) [0|255] "bitfield"  MASTER,NODE1,NODE2,NODE3,NODE4,NODE5,NODE6,NODE7,NODE8,NODE9,NODE10,NODE11,NODE12,NODE13,NODE14,NODE15,NODE16,TOOL
 SG_ error_code : 8|8@1+ (1,0) [0|255] ""  MASTER,NODE1,NODE2,NODE3,NODE4,NODE5,NODE6,NODE7,NODE8,NODE9,NODE10,NODE11,NODE12,NODE13,NODE14,NODE15,NODE16,TOOL
 SG_ actual_rpm : 16|16@1- (0.1,0) [-3276.8|3276.7] "rpm"  MASTER,NODE1,NODE2,NODE3,NODE4,NODE5,NODE6,NODE7,NODE8,NODE9,NODE10,NODE11,NODE12,NODE13,NODE14,NODE15,NODE16,TOOL
 SG_ actual_pos : 32|16@1+ (1.52587890625e-05,0) [0|0.9999847412109375] "rev"  MASTER,NODE1,NODE2,NODE3,NODE4,NODE5,NODE6,NODE7,NODE8,NODE9,NODE10,NODE11,NODE12,NODE13,NODE14,NODE15,NODE16,TOOL
 SG_ alive_counter : 48|8@1+ (1,0) [0|255] ""  MASTER,NODE1,NODE2,NODE3,NODE4,NODE5,NODE6,NODE7,NODE8,NODE9,NODE10,NODE11,NODE12,NODE13,NODE14,NODE15,NODE16,TOOL
 SG_ sync_error : 56|8@1- (0.00390625,0) [-0.5|0.49609375] "rev"  MASTER,NODE1,NODE2,NODE3,NODE4,NODE5,NODE6,NODE7,NODE8,NODE9,NODE10,NODE11,NODE12,NODE13,NODE14,NODE15,NODE16,TOOL

BO_ 464 S0_NODE_DIAG_16: 8 NODE16
 SG_ bus_voltage : 0|16@1+ (0.1,0) [0|6553.5] "V"  MASTER,NODE1,NODE2,NODE3,NODE4,NODE5,NODE6,NODE7,NODE8,NODE9,NODE10,NODE11,NODE12,NODE13,NODE14,NODE15,NODE16,TOOL
 SG_ motor_current : 16|16@1- (0.1,0) [-3276.8|3276.7] "A"  MASTER,NODE1,NODE2,NODE3,NODE4,NODE5,NODE6,NODE7,NODE8,NODE9,NODE10,NODE11,NODE12,NODE13,NODE14,NODE15,NODE16,TOOL
 SG_ controller_temp : 32|8@1- (1,0) [-128|127] "degC"  MASTER,NODE1,NODE2,NODE3,NODE4,NODE5,NODE6,NODE7,NODE8,NODE9,NODE10,NODE11,NODE12,NODE13,NODE14,NODE15,NODE16,TOOL
 SG_ motor_temp : 40|8@1- (1,0) [-128|127] "degC"  MASTER,NODE1,NODE2,NODE3,NODE4,NODE5,NODE6,NODE7,NODE8,NODE9,NODE10,NODE11,NODE12,NODE13,NODE14,NODE15,NODE16,TOOL
 SG_ fault_flags : 48|8@1+ (1,0) [0|255] "bitfield"  MASTER,NODE1,NODE2,NODE3,NODE4,NODE5,NODE6,NODE7,NODE8,NODE9,NODE10,NODE11,NODE12,NODE13,NODE14,NODE15,NODE16,TOOL
 SG_ warning_flags : 56|8@1+ (1,0) [0|255] "bitfield"  MASTER,NODE1,NODE2,NODE3,NODE4,NODE5,NODE6,NODE7,NODE8,NODE9,NODE10,NODE11,NODE12,NODE13,NODE14,NODE15,NODE16,TOOL

BO_ 512 S1_GLOBAL_CONTROL: 8 MASTER
 SG_ system_mode : 0|8@1+ (1,0) [0|255] ""  MASTER,NODE1,NODE2,NODE3,NODE4,NODE5,NODE6,NODE7,NODE8,NODE9,NODE10,NODE11,NODE12,NODE13,NODE14,NODE15,NODE16,TOOL
 SG_ control_flags : 8|8@1+ (1,0) [0|255] "bitfield"  MASTER,NODE1,NODE2,NODE3,NODE4,NODE5,NODE6,NODE7,NODE8,NODE9,NODE10,NODE11,NODE12,NODE13,NODE14,NODE15,NODE16,TOOL
 SG_ base_rpm : 16|16@1- (0.1,0) [-3276.8|3276.7] "rpm"  MASTER,NODE1,NODE2,NODE3,NODE4,NODE5,NODE6,NODE7,NODE8,NODE9,NODE10,NODE11,NODE12,NODE13,NODE14,NODE15,NODE16,TOOL
 SG_ sync_pos : 32|16@1+ (1.52587890625e-05,0) [0|0.9999847412109375] "rev"  MASTER,NODE1,NODE2,NODE3,NODE4,NODE5,NODE6,NODE7,NODE8,NODE9,NODE10,NODE11,NODE12,NODE13,NODE14,NODE15,NODE16,TOOL
 SG_ sequence : 48|8@1+ (1,0) [0|255] ""  MASTER,NODE1,NODE2,NODE3,NODE4,NODE5,NODE6,NODE7,NODE8,NODE9,NODE10,NODE11,NODE12,NODE13,NODE14,NODE15,NODE16,TOOL
 SG_ reserved : 56|8@1+ (1,0) [0|255] ""  MASTER,NODE1,NODE2,NODE3,NODE4,NODE5,NODE6,NODE7,NODE8,NODE9,NODE10,NODE11,NODE12,NODE13,NODE14,NODE15,NODE16,TOOL

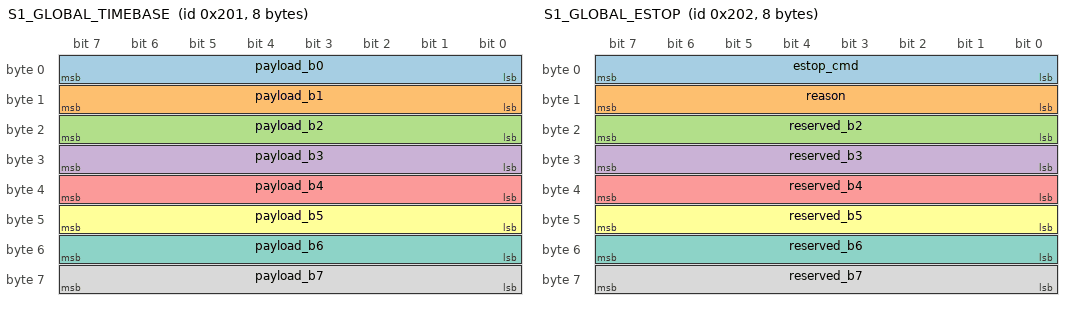
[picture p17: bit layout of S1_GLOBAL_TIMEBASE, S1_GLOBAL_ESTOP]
BO_ 513 S1_GLOBAL_TIMEBASE: 8 MASTER
 SG_ payload_b0 : 0|8@1+ (1,0) [0|255] "raw"  MASTER,NODE1,NODE2,NODE3,NODE4,NODE5,NODE6,NODE7,NODE8,NODE9,NODE10,NODE11,NODE12,NODE13,NODE14,NODE15,NODE16,TOOL
 SG_ payload_b1 : 8|8@1+ (1,0) [0|255] "raw"  MASTER,NODE1,NODE2,NODE3,NODE4,NODE5,NODE6,NODE7,NODE8,NODE9,NODE10,NODE11,NODE12,NODE13,NODE14,NODE15,NODE16,TOOL
 SG_ payload_b2 : 16|8@1+ (1,0) [0|255] "raw"  MASTER,NODE1,NODE2,NODE3,NODE4,NODE5,NODE6,NODE7,NODE8,NODE9,NODE10,NODE11,NODE12,NODE13,NODE14,NODE15,NODE16,TOOL
 SG_ payload_b3 : 24|8@1+ (1,0) [0|255] "raw"  MASTER,NODE1,NODE2,NODE3,NODE4,NODE5,NODE6,NODE7,NODE8,NODE9,NODE10,NODE11,NODE12,NODE13,NODE14,NODE15,NODE16,TOOL
 SG_ payload_b4 : 32|8@1+ (1,0) [0|255] "raw"  MASTER,NODE1,NODE2,NODE3,NODE4,NODE5,NODE6,NODE7,NODE8,NODE9,NODE10,NODE11,NODE12,NODE13,NODE14,NODE15,NODE16,TOOL
 SG_ payload_b5 : 40|8@1+ (1,0) [0|255] "raw"  MASTER,NODE1,NODE2,NODE3,NODE4,NODE5,NODE6,NODE7,NODE8,NODE9,NODE10,NODE11,NODE12,NODE13,NODE14,NODE15,NODE16,TOOL
 SG_ payload_b6 : 48|8@1+ (1,0) [0|255] "raw"  MASTER,NODE1,NODE2,NODE3,NODE4,NODE5,NODE6,NODE7,NODE8,NODE9,NODE10,NODE11,NODE12,NODE13,NODE14,NODE15,NODE16,TOOL
 SG_ payload_b7 : 56|8@1+ (1,0) [0|255] "raw"  MASTER,NODE1,NODE2,NODE3,NODE4,NODE5,NODE6,NODE7,NODE8,NODE9,NODE10,NODE11,NODE12,NODE13,NODE14,NODE15,NODE16,TOOL

BO_ 514 S1_GLOBAL_ESTOP: 8 MASTER
 SG_ estop_cmd : 0|8@1+ (1,0) [0|255] ""  MASTER,NODE1,NODE2,NODE3,NODE4,NODE5,NODE6,NODE7,NODE8,NODE9,NODE10,NODE11,NODE12,NODE13,NODE14,NODE15,NODE16,TOOL
 SG_ reason : 8|8@1+ (1,0) [0|255] ""  MASTER,NODE1,NODE2,NODE3,NODE4,NODE5,NODE6,NODE7,NODE8,NODE9,NODE10,NODE11,NODE12,NODE13,NODE14,NODE15,NODE16,TOOL
 SG_ reserved_b2 : 16|8@1+ (1,0) [0|255] ""  MASTER,NODE1,NODE2,NODE3,NODE4,NODE5,NODE6,NODE7,NODE8,NODE9,NODE10,NODE11,NODE12,NODE13,NODE14,NODE15,NODE16,TOOL
 SG_ reserved_b3 : 24|8@1+ (1,0) [0|255] ""  MASTER,NODE1,NODE2,NODE3,NODE4,NODE5,NODE6,NODE7,NODE8,NODE9,NODE10,NODE11,NODE12,NODE13,NODE14,NODE15,NODE16,TOOL
 SG_ reserved_b4 : 32|8@1+ (1,0) [0|255] ""  MASTER,NODE1,NODE2,NODE3,NODE4,NODE5,NODE6,NODE7,NODE8,NODE9,NODE10,NODE11,NODE12,NODE13,NODE14,NODE15,NODE16,TOOL
 SG_ reserved_b5 : 40|8@1+ (1,0) [0|255] ""  MASTER,NODE1,NODE2,NODE3,NODE4,NODE5,NODE6,NODE7,NODE8,NODE9,NODE10,NODE11,NODE12,NODE13,NODE14,NODE15,NODE16,TOOL
 SG_ reserved_b6 : 48|8@1+ (1,0) [0|255] ""  MASTER,NODE1,NODE2,NODE3,NODE4,NODE5,NODE6,NODE7,NODE8,NODE9,NODE10,NODE11,NODE12,NODE13,NODE14,NODE15,NODE16,TOOL
 SG_ reserved_b7 : 56|8@1+ (1,0) [0|255] ""  MASTER,NODE1,NODE2,NODE3,NODE4,NODE5,NODE6,NODE7,NODE8,NODE9,NODE10,NODE11,NODE12,NODE13,NODE14,NODE15,NODE16,TOOL

BO_ 529 S1_NODE_CMD_1: 8 MASTER
 SG_ node_command : 0|8@1+ (1,0) [0|255] ""  MASTER,NODE1,NODE2,NODE3,NODE4,NODE5,NODE6,NODE7,NODE8,NODE9,NODE10,NODE11,NODE12,NODE13,NODE14,NODE15,NODE16,TOOL
 SG_ node_flags : 8|8@1+ (1,0) [0|255] "bitfield"  MASTER,NODE1,NODE2,NODE3,NODE4,NODE5,NODE6,NODE7,NODE8,NODE9,NODE10,NODE11,NODE12,NODE13,NODE14,NODE15,NODE16,TOOL
 SG_ trim_rpm : 16|16@1- (0.1,0) [-3276.8|3276.7] "rpm"  MASTER,NODE1,NODE2,NODE3,NODE4,NODE5,NODE6,NODE7,NODE8,NODE9,NODE10,NODE11,NODE12,NODE13,NODE14,NODE15,NODE16,TOOL
 SG_ section_mask : 32|16@1+ (1,0) [0|65535] "bitmask"  MASTER,NODE1,NODE2,NODE3,NODE4,NODE5,NODE6,NODE7,NODE8,NODE9,NODE10,NODE11,NODE12,NODE13,NODE14,NODE15,NODE16,TOOL
 SG_ seq : 48|8@1+ (1,0) [0|255] ""  MASTER,NODE1,NODE2,NODE3,NODE4,NODE5,NODE6,NODE7,NODE8,NODE9,NODE10,NODE11,NODE12,NODE13,NODE14,NODE15,NODE16,TOOL
 SG_ reserved : 56|8@1+ (1,0) [0|255] ""  MASTER,NODE1,NODE2,NODE3,NODE4,NODE5,NODE6,NODE7,NODE8,NODE9,NODE10,NODE11,NODE12,NODE13,NODE14,NODE15,NODE16,TOOL

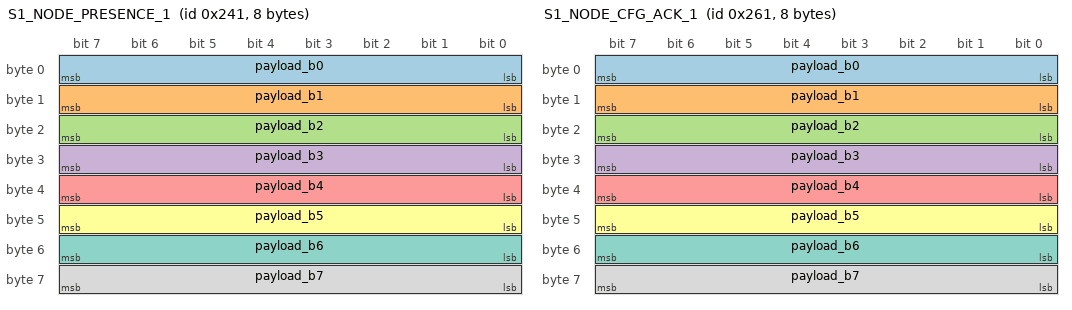
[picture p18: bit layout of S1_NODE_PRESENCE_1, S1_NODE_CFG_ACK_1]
BO_ 577 S1_NODE_PRESENCE_1: 8 NODE1
 SG_ payload_b0 : 0|8@1+ (1,0) [0|255] "raw"  MASTER,NODE1,NODE2,NODE3,NODE4,NODE5,NODE6,NODE7,NODE8,NODE9,NODE10,NODE11,NODE12,NODE13,NODE14,NODE15,NODE16,TOOL
 SG_ payload_b1 : 8|8@1+ (1,0) [0|255] "raw"  MASTER,NODE1,NODE2,NODE3,NODE4,NODE5,NODE6,NODE7,NODE8,NODE9,NODE10,NODE11,NODE12,NODE13,NODE14,NODE15,NODE16,TOOL
 SG_ payload_b2 : 16|8@1+ (1,0) [0|255] "raw"  MASTER,NODE1,NODE2,NODE3,NODE4,NODE5,NODE6,NODE7,NODE8,NODE9,NODE10,NODE11,NODE12,NODE13,NODE14,NODE15,NODE16,TOOL
 SG_ payload_b3 : 24|8@1+ (1,0) [0|255] "raw"  MASTER,NODE1,NODE2,NODE3,NODE4,NODE5,NODE6,NODE7,NODE8,NODE9,NODE10,NODE11,NODE12,NODE13,NODE14,NODE15,NODE16,TOOL
 SG_ payload_b4 : 32|8@1+ (1,0) [0|255] "raw"  MASTER,NODE1,NODE2,NODE3,NODE4,NODE5,NODE6,NODE7,NODE8,NODE9,NODE10,NODE11,NODE12,NODE13,NODE14,NODE15,NODE16,TOOL
 SG_ payload_b5 : 40|8@1+ (1,0) [0|255] "raw"  MASTER,NODE1,NODE2,NODE3,NODE4,NODE5,NODE6,NODE7,NODE8,NODE9,NODE10,NODE11,NODE12,NODE13,NODE14,NODE15,NODE16,TOOL
 SG_ payload_b6 : 48|8@1+ (1,0) [0|255] "raw"  MASTER,NODE1,NODE2,NODE3,NODE4,NODE5,NODE6,NODE7,NODE8,NODE9,NODE10,NODE11,NODE12,NODE13,NODE14,NODE15,NODE16,TOOL
 SG_ payload_b7 : 56|8@1+ (1,0) [0|255] "raw"  MASTER,NODE1,NODE2,NODE3,NODE4,NODE5,NODE6,NODE7,NODE8,NODE9,NODE10,NODE11,NODE12,NODE13,NODE14,NODE15,NODE16,TOOL

BO_ 609 S1_NODE_CFG_ACK_1: 8 NODE1
 SG_ payload_b0 : 0|8@1+ (1,0) [0|255] "raw"  MASTER,NODE1,NODE2,NODE3,NODE4,NODE5,NODE6,NODE7,NODE8,NODE9,NODE10,NODE11,NODE12,NODE13,NODE14,NODE15,NODE16,TOOL
 SG_ payload_b1 : 8|8@1+ (1,0) [0|255] "raw"  MASTER,NODE1,NODE2,NODE3,NODE4,NODE5,NODE6,NODE7,NODE8,NODE9,NODE10,NODE11,NODE12,NODE13,NODE14,NODE15,NODE16,TOOL
 SG_ payload_b2 : 16|8@1+ (1,0) [0|255] "raw"  MASTER,NODE1,NODE2,NODE3,NODE4,NODE5,NODE6,NODE7,NODE8,NODE9,NODE10,NODE11,NODE12,NODE13,NODE14,NODE15,NODE16,TOOL
 SG_ payload_b3 : 24|8@1+ (1,0) [0|255] "raw"  MASTER,NODE1,NODE2,NODE3,NODE4,NODE5,NODE6,NODE7,NODE8,NODE9,NODE10,NODE11,NODE12,NODE13,NODE14,NODE15,NODE16,TOOL
 SG_ payload_b4 : 32|8@1+ (1,0) [0|255] "raw"  MASTER,NODE1,NODE2,NODE3,NODE4,NODE5,NODE6,NODE7,NODE8,NODE9,NODE10,NODE11,NODE12,NODE13,NODE14,NODE15,NODE16,TOOL
 SG_ payload_b5 : 40|8@1+ (1,0) [0|255] "raw"  MASTER,NODE1,NODE2,NODE3,NODE4,NODE5,NODE6,NODE7,NODE8,NODE9,NODE10,NODE11,NODE12,NODE13,NODE14,NODE15,NODE16,TOOL
 SG_ payload_b6 : 48|8@1+ (1,0) [0|255] "raw"  MASTER,NODE1,NODE2,NODE3,NODE4,NODE5,NODE6,NODE7,NODE8,NODE9,NODE10,NODE11,NODE12,NODE13,NODE14,NODE15,NODE16,TOOL
 SG_ payload_b7 : 56|8@1+ (1,0) [0|255] "raw"  MASTER,NODE1,NODE2,NODE3,NODE4,NODE5,NODE6,NODE7,NODE8,NODE9,NODE10,NODE11,NODE12,NODE13,NODE14,NODE15,NODE16,TOOL

BO_ 641 S1_NODE_STATUS_FAST_1: 8 NODE1
 SG_ status_flags : 0|8@1+ (1,0) [0|255] "bitfield"  MASTER,NODE1,NODE2,NODE3,NODE4,NODE5,NODE6,NODE7,NODE8,NODE9,NODE10,NODE11,NODE12,NODE13,NODE14,NODE15,NODE16,TOOL
 SG_ error_code : 8|8@1+ (1,0) [0|255] ""  MASTER,NODE1,NODE2,NODE3,NODE4,NODE5,NODE6,NODE7,NODE8,NODE9,NODE10,NODE11,NODE12,NODE13,NODE14,NODE15,NODE16,TOOL
 SG_ actual_rpm : 16|16@1- (0.1,0) [-3276.8|3276.7] "rpm"  MASTER,NODE1,NODE2,NODE3,NODE4,NODE5,NODE6,NODE7,NODE8,NODE9,NODE10,NODE11,NODE12,NODE13,NODE14,NODE15,NODE16,TOOL
 SG_ actual_pos : 32|16@1+ (1.52587890625e-05,0) [0|0.9999847412109375] "rev"  MASTER,NODE1,NODE2,NODE3,NODE4,NODE5,NODE6,NODE7,NODE8,NODE9,NODE10,NODE11,NODE12,NODE13,NODE14,NODE15,NODE16,TOOL
 SG_ alive_counter : 48|8@1+ (1,0) [0|255] ""  MASTER,NODE1,NODE2,NODE3,NODE4,NODE5,NODE6,NODE7,NODE8,NODE9,NODE10,NODE11,NODE12,NODE13,NODE14,NODE15,NODE16,TOOL
 SG_ sync_error : 56|8@1- (0.00390625,0) [-0.5|0.49609375] "rev"  MASTER,NODE1,NODE2,NODE3,NODE4,NODE5,NODE6,NODE7,NODE8,NODE9,NODE10,NODE11,NODE12,NODE13,NODE14,NODE15,NODE16,TOOL

BO_ 705 S1_NODE_DIAG_1: 8 NODE1
 SG_ bus_voltage : 0|16@1+ (0.1,0) [0|6553.5] "V"  MASTER,NODE1,NODE2,NODE3,NODE4,NODE5,NODE6,NODE7,NODE8,NODE9,NODE10,NODE11,NODE12,NODE13,NODE14,NODE15,NODE16,TOOL
 SG_ motor_current : 16|16@1- (0.1,0) [-3276.8|3276.7] "A"  MASTER,NODE1,NODE2,NODE3,NODE4,NODE5,NODE6,NODE7,NODE8,NODE9,NODE10,NODE11,NODE12,NODE13,NODE14,NODE15,NODE16,TOOL
 SG_ controller_temp : 32|8@1- (1,0) [-128|127] "degC"  MASTER,NODE1,NODE2,NODE3,NODE4,NODE5,NODE6,NODE7,NODE8,NODE9,NODE10,NODE11,NODE12,NODE13,NODE14,NODE15,NODE16,TOOL
 SG_ motor_temp : 40|8@1- (1,0) [-128|127] "degC"  MASTER,NODE1,NODE2,NODE3,NODE4,NODE5,NODE6,NODE7,NODE8,NODE9,NODE10,NODE11,NODE12,NODE13,NODE14,NODE15,NODE16,TOOL
 SG_ fault_flags : 48|8@1+ (1,0) [0|255] "bitfield"  MASTER,NODE1,NODE2,NODE3,NODE4,NODE5,NODE6,NODE7,NODE8,NODE9,NODE10,NODE11,NODE12,NODE13,NODE14,NODE15,NODE16,TOOL
 SG_ warning_flags : 56|8@1+ (1,0) [0|255] "bitfield"  MASTER,NODE1,NODE2,NODE3,NODE4,NODE5,NODE6,NODE7,NODE8,NODE9,NODE10,NODE11,NODE12,NODE13,NODE14,NODE15,NODE16,TOOL

BO_ 530 S1_NODE_CMD_2: 8 MASTER
 SG_ node_command : 0|8@1+ (1,0) [0|255] ""  MASTER,NODE1,NODE2,NODE3,NODE4,NODE5,NODE6,NODE7,NODE8,NODE9,NODE10,NODE11,NODE12,NODE13,NODE14,NODE15,NODE16,TOOL
 SG_ node_flags : 8|8@1+ (1,0) [0|255] "bitfield"  MASTER,NODE1,NODE2,NODE3,NODE4,NODE5,NODE6,NODE7,NODE8,NODE9,NODE10,NODE11,NODE12,NODE13,NODE14,NODE15,NODE16,TOOL
 SG_ trim_rpm : 16|16@1- (0.1,0) [-3276.8|3276.7] "rpm"  MASTER,NODE1,NODE2,NODE3,NODE4,NODE5,NODE6,NODE7,NODE8,NODE9,NODE10,NODE11,NODE12,NODE13,NODE14,NODE15,NODE16,TOOL
 SG_ section_mask : 32|16@1+ (1,0) [0|65535] "bitmask"  MASTER,NODE1,NODE2,NODE3,NODE4,NODE5,NODE6,NODE7,NODE8,NODE9,NODE10,NODE11,NODE12,NODE13,NODE14,NODE15,NODE16,TOOL
 SG_ seq : 48|8@1+ (1,0) [0|255] ""  MASTER,NODE1,NODE2,NODE3,NODE4,NODE5,NODE6,NODE7,NODE8,NODE9,NODE10,NODE11,NODE12,NODE13,NODE14,NODE15,NODE16,TOOL
 SG_ reserved : 56|8@1+ (1,0) [0|255] ""  MASTER,NODE1,NODE2,NODE3,NODE4,NODE5,NODE6,NODE7,NODE8,NODE9,NODE10,NODE11,NODE12,NODE13,NODE14,NODE15,NODE16,TOOL

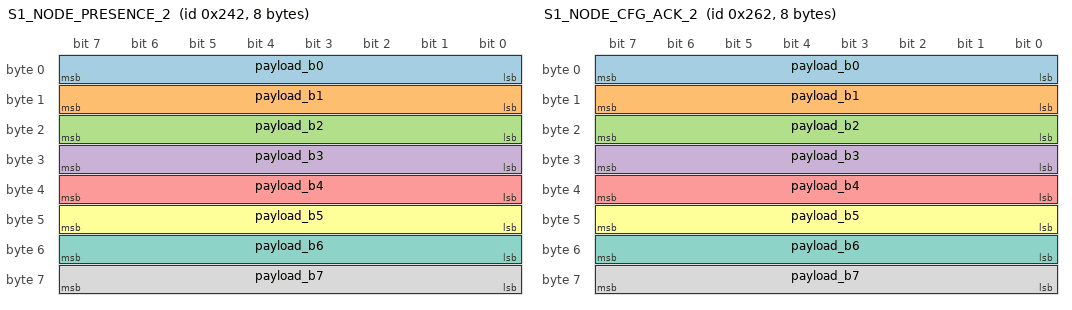
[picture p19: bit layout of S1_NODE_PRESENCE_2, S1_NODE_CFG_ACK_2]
BO_ 578 S1_NODE_PRESENCE_2: 8 NODE2
 SG_ payload_b0 : 0|8@1+ (1,0) [0|255] "raw"  MASTER,NODE1,NODE2,NODE3,NODE4,NODE5,NODE6,NODE7,NODE8,NODE9,NODE10,NODE11,NODE12,NODE13,NODE14,NODE15,NODE16,TOOL
 SG_ payload_b1 : 8|8@1+ (1,0) [0|255] "raw"  MASTER,NODE1,NODE2,NODE3,NODE4,NODE5,NODE6,NODE7,NODE8,NODE9,NODE10,NODE11,NODE12,NODE13,NODE14,NODE15,NODE16,TOOL
 SG_ payload_b2 : 16|8@1+ (1,0) [0|255] "raw"  MASTER,NODE1,NODE2,NODE3,NODE4,NODE5,NODE6,NODE7,NODE8,NODE9,NODE10,NODE11,NODE12,NODE13,NODE14,NODE15,NODE16,TOOL
 SG_ payload_b3 : 24|8@1+ (1,0) [0|255] "raw"  MASTER,NODE1,NODE2,NODE3,NODE4,NODE5,NODE6,NODE7,NODE8,NODE9,NODE10,NODE11,NODE12,NODE13,NODE14,NODE15,NODE16,TOOL
 SG_ payload_b4 : 32|8@1+ (1,0) [0|255] "raw"  MASTER,NODE1,NODE2,NODE3,NODE4,NODE5,NODE6,NODE7,NODE8,NODE9,NODE10,NODE11,NODE12,NODE13,NODE14,NODE15,NODE16,TOOL
 SG_ payload_b5 : 40|8@1+ (1,0) [0|255] "raw"  MASTER,NODE1,NODE2,NODE3,NODE4,NODE5,NODE6,NODE7,NODE8,NODE9,NODE10,NODE11,NODE12,NODE13,NODE14,NODE15,NODE16,TOOL
 SG_ payload_b6 : 48|8@1+ (1,0) [0|255] "raw"  MASTER,NODE1,NODE2,NODE3,NODE4,NODE5,NODE6,NODE7,NODE8,NODE9,NODE10,NODE11,NODE12,NODE13,NODE14,NODE15,NODE16,TOOL
 SG_ payload_b7 : 56|8@1+ (1,0) [0|255] "raw"  MASTER,NODE1,NODE2,NODE3,NODE4,NODE5,NODE6,NODE7,NODE8,NODE9,NODE10,NODE11,NODE12,NODE13,NODE14,NODE15,NODE16,TOOL

BO_ 610 S1_NODE_CFG_ACK_2: 8 NODE2
 SG_ payload_b0 : 0|8@1+ (1,0) [0|255] "raw"  MASTER,NODE1,NODE2,NODE3,NODE4,NODE5,NODE6,NODE7,NODE8,NODE9,NODE10,NODE11,NODE12,NODE13,NODE14,NODE15,NODE16,TOOL
 SG_ payload_b1 : 8|8@1+ (1,0) [0|255] "raw"  MASTER,NODE1,NODE2,NODE3,NODE4,NODE5,NODE6,NODE7,NODE8,NODE9,NODE10,NODE11,NODE12,NODE13,NODE14,NODE15,NODE16,TOOL
 SG_ payload_b2 : 16|8@1+ (1,0) [0|255] "raw"  MASTER,NODE1,NODE2,NODE3,NODE4,NODE5,NODE6,NODE7,NODE8,NODE9,NODE10,NODE11,NODE12,NODE13,NODE14,NODE15,NODE16,TOOL
 SG_ payload_b3 : 24|8@1+ (1,0) [0|255] "raw"  MASTER,NODE1,NODE2,NODE3,NODE4,NODE5,NODE6,NODE7,NODE8,NODE9,NODE10,NODE11,NODE12,NODE13,NODE14,NODE15,NODE16,TOOL
 SG_ payload_b4 : 32|8@1+ (1,0) [0|255] "raw"  MASTER,NODE1,NODE2,NODE3,NODE4,NODE5,NODE6,NODE7,NODE8,NODE9,NODE10,NODE11,NODE12,NODE13,NODE14,NODE15,NODE16,TOOL
 SG_ payload_b5 : 40|8@1+ (1,0) [0|255] "raw"  MASTER,NODE1,NODE2,NODE3,NODE4,NODE5,NODE6,NODE7,NODE8,NODE9,NODE10,NODE11,NODE12,NODE13,NODE14,NODE15,NODE16,TOOL
 SG_ payload_b6 : 48|8@1+ (1,0) [0|255] "raw"  MASTER,NODE1,NODE2,NODE3,NODE4,NODE5,NODE6,NODE7,NODE8,NODE9,NODE10,NODE11,NODE12,NODE13,NODE14,NODE15,NODE16,TOOL
 SG_ payload_b7 : 56|8@1+ (1,0) [0|255] "raw"  MASTER,NODE1,NODE2,NODE3,NODE4,NODE5,NODE6,NODE7,NODE8,NODE9,NODE10,NODE11,NODE12,NODE13,NODE14,NODE15,NODE16,TOOL

BO_ 642 S1_NODE_STATUS_FAST_2: 8 NODE2
 SG_ status_flags : 0|8@1+ (1,0) [0|255] "bitfield"  MASTER,NODE1,NODE2,NODE3,NODE4,NODE5,NODE6,NODE7,NODE8,NODE9,NODE10,NODE11,NODE12,NODE13,NODE14,NODE15,NODE16,TOOL
 SG_ error_code : 8|8@1+ (1,0) [0|255] ""  MASTER,NODE1,NODE2,NODE3,NODE4,NODE5,NODE6,NODE7,NODE8,NODE9,NODE10,NODE11,NODE12,NODE13,NODE14,NODE15,NODE16,TOOL
 SG_ actual_rpm : 16|16@1- (0.1,0) [-3276.8|3276.7] "rpm"  MASTER,NODE1,NODE2,NODE3,NODE4,NODE5,NODE6,NODE7,NODE8,NODE9,NODE10,NODE11,NODE12,NODE13,NODE14,NODE15,NODE16,TOOL
 SG_ actual_pos : 32|16@1+ (1.52587890625e-05,0) [0|0.9999847412109375] "rev"  MASTER,NODE1,NODE2,NODE3,NODE4,NODE5,NODE6,NODE7,NODE8,NODE9,NODE10,NODE11,NODE12,NODE13,NODE14,NODE15,NODE16,TOOL
 SG_ alive_counter : 48|8@1+ (1,0) [0|255] ""  MASTER,NODE1,NODE2,NODE3,NODE4,NODE5,NODE6,NODE7,NODE8,NODE9,NODE10,NODE11,NODE12,NODE13,NODE14,NODE15,NODE16,TOOL
 SG_ sync_error : 56|8@1- (0.00390625,0) [-0.5|0.49609375] "rev"  MASTER,NODE1,NODE2,NODE3,NODE4,NODE5,NODE6,NODE7,NODE8,NODE9,NODE10,NODE11,NODE12,NODE13,NODE14,NODE15,NODE16,TOOL

BO_ 706 S1_NODE_DIAG_2: 8 NODE2
 SG_ bus_voltage : 0|16@1+ (0.1,0) [0|6553.5] "V"  MASTER,NODE1,NODE2,NODE3,NODE4,NODE5,NODE6,NODE7,NODE8,NODE9,NODE10,NODE11,NODE12,NODE13,NODE14,NODE15,NODE16,TOOL
 SG_ motor_current : 16|16@1- (0.1,0) [-3276.8|3276.7] "A"  MASTER,NODE1,NODE2,NODE3,NODE4,NODE5,NODE6,NODE7,NODE8,NODE9,NODE10,NODE11,NODE12,NODE13,NODE14,NODE15,NODE16,TOOL
 SG_ controller_temp : 32|8@1- (1,0) [-128|127] "degC"  MASTER,NODE1,NODE2,NODE3,NODE4,NODE5,NODE6,NODE7,NODE8,NODE9,NODE10,NODE11,NODE12,NODE13,NODE14,NODE15,NODE16,TOOL
 SG_ motor_temp : 40|8@1- (1,0) [-128|127] "degC"  MASTER,NODE1,NODE2,NODE3,NODE4,NODE5,NODE6,NODE7,NODE8,NODE9,NODE10,NODE11,NODE12,NODE13,NODE14,NODE15,NODE16,TOOL
 SG_ fault_flags : 48|8@1+ (1,0) [0|255] "bitfield"  MASTER,NODE1,NODE2,NODE3,NODE4,NODE5,NODE6,NODE7,NODE8,NODE9,NODE10,NODE11,NODE12,NODE13,NODE14,NODE15,NODE16,TOOL
 SG_ warning_flags : 56|8@1+ (1,0) [0|255] "bitfield"  MASTER,NODE1,NODE2,NODE3,NODE4,NODE5,NODE6,NODE7,NODE8,NODE9,NODE10,NODE11,NODE12,NODE13,NODE14,NODE15,NODE16,TOOL

BO_ 531 S1_NODE_CMD_3: 8 MASTER
 SG_ node_command : 0|8@1+ (1,0) [0|255] ""  MASTER,NODE1,NODE2,NODE3,NODE4,NODE5,NODE6,NODE7,NODE8,NODE9,NODE10,NODE11,NODE12,NODE13,NODE14,NODE15,NODE16,TOOL
 SG_ node_flags : 8|8@1+ (1,0) [0|255] "bitfield"  MASTER,NODE1,NODE2,NODE3,NODE4,NODE5,NODE6,NODE7,NODE8,NODE9,NODE10,NODE11,NODE12,NODE13,NODE14,NODE15,NODE16,TOOL
 SG_ trim_rpm : 16|16@1- (0.1,0) [-3276.8|3276.7] "rpm"  MASTER,NODE1,NODE2,NODE3,NODE4,NODE5,NODE6,NODE7,NODE8,NODE9,NODE10,NODE11,NODE12,NODE13,NODE14,NODE15,NODE16,TOOL
 SG_ section_mask : 32|16@1+ (1,0) [0|65535] "bitmask"  MASTER,NODE1,NODE2,NODE3,NODE4,NODE5,NODE6,NODE7,NODE8,NODE9,NODE10,NODE11,NODE12,NODE13,NODE14,NODE15,NODE16,TOOL
 SG_ seq : 48|8@1+ (1,0) [0|255] ""  MASTER,NODE1,NODE2,NODE3,NODE4,NODE5,NODE6,NODE7,NODE8,NODE9,NODE10,NODE11,NODE12,NODE13,NODE14,NODE15,NODE16,TOOL
 SG_ reserved : 56|8@1+ (1,0) [0|255] ""  MASTER,NODE1,NODE2,NODE3,NODE4,NODE5,NODE6,NODE7,NODE8,NODE9,NODE10,NODE11,NODE12,NODE13,NODE14,NODE15,NODE16,TOOL

BO_ 579 S1_NODE_PRESENCE_3: 8 NODE3
 SG_ payload_b0 : 0|8@1+ (1,0) [0|255] "raw"  MASTER,NODE1,NODE2,NODE3,NODE4,NODE5,NODE6,NODE7,NODE8,NODE9,NODE10,NODE11,NODE12,NODE13,NODE14,NODE15,NODE16,TOOL
 SG_ payload_b1 : 8|8@1+ (1,0) [0|255] "raw"  MASTER,NODE1,NODE2,NODE3,NODE4,NODE5,NODE6,NODE7,NODE8,NODE9,NODE10,NODE11,NODE12,NODE13,NODE14,NODE15,NODE16,TOOL
 SG_ payload_b2 : 16|8@1+ (1,0) [0|255] "raw"  MASTER,NODE1,NODE2,NODE3,NODE4,NODE5,NODE6,NODE7,NODE8,NODE9,NODE10,NODE11,NODE12,NODE13,NODE14,NODE15,NODE16,TOOL
 SG_ payload_b3 : 24|8@1+ (1,0) [0|255] "raw"  MASTER,NODE1,NODE2,NODE3,NODE4,NODE5,NODE6,NODE7,NODE8,NODE9,NODE10,NODE11,NODE12,NODE13,NODE14,NODE15,NODE16,TOOL
 SG_ payload_b4 : 32|8@1+ (1,0) [0|255] "raw"  MASTER,NODE1,NODE2,NODE3,NODE4,NODE5,NODE6,NODE7,NODE8,NODE9,NODE10,NODE11,NODE12,NODE13,NODE14,NODE15,NODE16,TOOL
 SG_ payload_b5 : 40|8@1+ (1,0) [0|255] "raw"  MASTER,NODE1,NODE2,NODE3,NODE4,NODE5,NODE6,NODE7,NODE8,NODE9,NODE10,NODE11,NODE12,NODE13,NODE14,NODE15,NODE16,TOOL
 SG_ payload_b6 : 48|8@1+ (1,0) [0|255] "raw"  MASTER,NODE1,NODE2,NODE3,NODE4,NODE5,NODE6,NODE7,NODE8,NODE9,NODE10,NODE11,NODE12,NODE13,NODE14,NODE15,NODE16,TOOL
 SG_ payload_b7 : 56|8@1+ (1,0) [0|255] "raw"  MASTER,NODE1,NODE2,NODE3,NODE4,NODE5,NODE6,NODE7,NODE8,NODE9,NODE10,NODE11,NODE12,NODE13,NODE14,NODE15,NODE16,TOOL

BO_ 611 S1_NODE_CFG_ACK_3: 8 NODE3
 SG_ payload_b0 : 0|8@1+ (1,0) [0|255] "raw"  MASTER,NODE1,NODE2,NODE3,NODE4,NODE5,NODE6,NODE7,NODE8,NODE9,NODE10,NODE11,NODE12,NODE13,NODE14,NODE15,NODE16,TOOL
 SG_ payload_b1 : 8|8@1+ (1,0) [0|255] "raw"  MASTER,NODE1,NODE2,NODE3,NODE4,NODE5,NODE6,NODE7,NODE8,NODE9,NODE10,NODE11,NODE12,NODE13,NODE14,NODE15,NODE16,TOOL
 SG_ payload_b2 : 16|8@1+ (1,0) [0|255] "raw"  MASTER,NODE1,NODE2,NODE3,NODE4,NODE5,NODE6,NODE7,NODE8,NODE9,NODE10,NODE11,NODE12,NODE13,NODE14,NODE15,NODE16,TOOL
 SG_ payload_b3 : 24|8@1+ (1,0) [0|255] "raw"  MASTER,NODE1,NODE2,NODE3,NODE4,NODE5,NODE6,NODE7,NODE8,NODE9,NODE10,NODE11,NODE12,NODE13,NODE14,NODE15,NODE16,TOOL
 SG_ payload_b4 : 32|8@1+ (1,0) [0|255] "raw"  MASTER,NODE1,NODE2,NODE3,NODE4,NODE5,NODE6,NODE7,NODE8,NODE9,NODE10,NODE11,NODE12,NODE13,NODE14,NODE15,NODE16,TOOL
 SG_ payload_b5 : 40|8@1+ (1,0) [0|255] "raw"  MASTER,NODE1,NODE2,NODE3,NODE4,NODE5,NODE6,NODE7,NODE8,NODE9,NODE10,NODE11,NODE12,NODE13,NODE14,NODE15,NODE16,TOOL
 SG_ payload_b6 : 48|8@1+ (1,0) [0|255] "raw"  MASTER,NODE1,NODE2,NODE3,NODE4,NODE5,NODE6,NODE7,NODE8,NODE9,NODE10,NODE11,NODE12,NODE13,NODE14,NODE15,NODE16,TOOL
 SG_ payload_b7 : 56|8@1+ (1,0) [0|255] "raw"  MASTER,NODE1,NODE2,NODE3,NODE4,NODE5,NODE6,NODE7,NODE8,NODE9,NODE10,NODE11,NODE12,NODE13,NODE14,NODE15,NODE16,TOOL

BO_ 643 S1_NODE_STATUS_FAST_3: 8 NODE3
 SG_ status_flags : 0|8@1+ (1,0) [0|255] "bitfield"  MASTER,NODE1,NODE2,NODE3,NODE4,NODE5,NODE6,NODE7,NODE8,NODE9,NODE10,NODE11,NODE12,NODE13,NODE14,NODE15,NODE16,TOOL
 SG_ error_code : 8|8@1+ (1,0) [0|255] ""  MASTER,NODE1,NODE2,NODE3,NODE4,NODE5,NODE6,NODE7,NODE8,NODE9,NODE10,NODE11,NODE12,NODE13,NODE14,NODE15,NODE16,TOOL
 SG_ actual_rpm : 16|16@1- (0.1,0) [-3276.8|3276.7] "rpm"  MASTER,NODE1,NODE2,NODE3,NODE4,NODE5,NODE6,NODE7,NODE8,NODE9,NODE10,NODE11,NODE12,NODE13,NODE14,NODE15,NODE16,TOOL
 SG_ actual_pos : 32|16@1+ (1.52587890625e-05,0) [0|0.9999847412109375] "rev"  MASTER,NODE1,NODE2,NODE3,NODE4,NODE5,NODE6,NODE7,NODE8,NODE9,NODE10,NODE11,NODE12,NODE13,NODE14,NODE15,NODE16,TOOL
 SG_ alive_counter : 48|8@1+ (1,0) [0|255] ""  MASTER,NODE1,NODE2,NODE3,NODE4,NODE5,NODE6,NODE7,NODE8,NODE9,NODE10,NODE11,NODE12,NODE13,NODE14,NODE15,NODE16,TOOL
 SG_ sync_error : 56|8@1- (0.00390625,0) [-0.5|0.49609375] "rev"  MASTER,NODE1,NODE2,NODE3,NODE4,NODE5,NODE6,NODE7,NODE8,NODE9,NODE10,NODE11,NODE12,NODE13,NODE14,NODE15,NODE16,TOOL

BO_ 707 S1_NODE_DIAG_3: 8 NODE3
 SG_ bus_voltage : 0|16@1+ (0.1,0) [0|6553.5] "V"  MASTER,NODE1,NODE2,NODE3,NODE4,NODE5,NODE6,NODE7,NODE8,NODE9,NODE10,NODE11,NODE12,NODE13,NODE14,NODE15,NODE16,TOOL
 SG_ motor_current : 16|16@1- (0.1,0) [-3276.8|3276.7] "A"  MASTER,NODE1,NODE2,NODE3,NODE4,NODE5,NODE6,NODE7,NODE8,NODE9,NODE10,NODE11,NODE12,NODE13,NODE14,NODE15,NODE16,TOOL
 SG_ controller_temp : 32|8@1- (1,0) [-128|127] "degC"  MASTER,NODE1,NODE2,NODE3,NODE4,NODE5,NODE6,NODE7,NODE8,NODE9,NODE10,NODE11,NODE12,NODE13,NODE14,NODE15,NODE16,TOOL
 SG_ motor_temp : 40|8@1- (1,0) [-128|127] "degC"  MASTER,NODE1,NODE2,NODE3,NODE4,NODE5,NODE6,NODE7,NODE8,NODE9,NODE10,NODE11,NODE12,NODE13,NODE14,NODE15,NODE16,TOOL
 SG_ fault_flags : 48|8@1+ (1,0) [0|255] "bitfield"  MASTER,NODE1,NODE2,NODE3,NODE4,NODE5,NODE6,NODE7,NODE8,NODE9,NODE10,NODE11,NODE12,NODE13,NODE14,NODE15,NODE16,TOOL
 SG_ warning_flags : 56|8@1+ (1,0) [0|255] "bitfield"  MASTER,NODE1,NODE2,NODE3,NODE4,NODE5,NODE6,NODE7,NODE8,NODE9,NODE10,NODE11,NODE12,NODE13,NODE14,NODE15,NODE16,TOOL

BO_ 532 S1_NODE_CMD_4: 8 MASTER
 SG_ node_command : 0|8@1+ (1,0) [0|255] ""  MASTER,NODE1,NODE2,NODE3,NODE4,NODE5,NODE6,NODE7,NODE8,NODE9,NODE10,NODE11,NODE12,NODE13,NODE14,NODE15,NODE16,TOOL
 SG_ node_flags : 8|8@1+ (1,0) [0|255] "bitfield"  MASTER,NODE1,NODE2,NODE3,NODE4,NODE5,NODE6,NODE7,NODE8,NODE9,NODE10,NODE11,NODE12,NODE13,NODE14,NODE15,NODE16,TOOL
 SG_ trim_rpm : 16|16@1- (0.1,0) [-3276.8|3276.7] "rpm"  MASTER,NODE1,NODE2,NODE3,NODE4,NODE5,NODE6,NODE7,NODE8,NODE9,NODE10,NODE11,NODE12,NODE13,NODE14,NODE15,NODE16,TOOL
 SG_ section_mask : 32|16@1+ (1,0) [0|65535] "bitmask"  MASTER,NODE1,NODE2,NODE3,NODE4,NODE5,NODE6,NODE7,NODE8,NODE9,NODE10,NODE11,NODE12,NODE13,NODE14,NODE15,NODE16,TOOL
 SG_ seq : 48|8@1+ (1,0) [0|255] ""  MASTER,NODE1,NODE2,NODE3,NODE4,NODE5,NODE6,NODE7,NODE8,NODE9,NODE10,NODE11,NODE12,NODE13,NODE14,NODE15,NODE16,TOOL
 SG_ reserved : 56|8@1+ (1,0) [0|255] ""  MASTER,NODE1,NODE2,NODE3,NODE4,NODE5,NODE6,NODE7,NODE8,NODE9,NODE10,NODE11,NODE12,NODE13,NODE14,NODE15,NODE16,TOOL

BO_ 580 S1_NODE_PRESENCE_4: 8 NODE4
 SG_ payload_b0 : 0|8@1+ (1,0) [0|255] "raw"  MASTER,NODE1,NODE2,NODE3,NODE4,NODE5,NODE6,NODE7,NODE8,NODE9,NODE10,NODE11,NODE12,NODE13,NODE14,NODE15,NODE16,TOOL
 SG_ payload_b1 : 8|8@1+ (1,0) [0|255] "raw"  MASTER,NODE1,NODE2,NODE3,NODE4,NODE5,NODE6,NODE7,NODE8,NODE9,NODE10,NODE11,NODE12,NODE13,NODE14,NODE15,NODE16,TOOL
 SG_ payload_b2 : 16|8@1+ (1,0) [0|255] "raw"  MASTER,NODE1,NODE2,NODE3,NODE4,NODE5,NODE6,NODE7,NODE8,NODE9,NODE10,NODE11,NODE12,NODE13,NODE14,NODE15,NODE16,TOOL
 SG_ payload_b3 : 24|8@1+ (1,0) [0|255] "raw"  MASTER,NODE1,NODE2,NODE3,NODE4,NODE5,NODE6,NODE7,NODE8,NODE9,NODE10,NODE11,NODE12,NODE13,NODE14,NODE15,NODE16,TOOL
 SG_ payload_b4 : 32|8@1+ (1,0) [0|255] "raw"  MASTER,NODE1,NODE2,NODE3,NODE4,NODE5,NODE6,NODE7,NODE8,NODE9,NODE10,NODE11,NODE12,NODE13,NODE14,NODE15,NODE16,TOOL
 SG_ payload_b5 : 40|8@1+ (1,0) [0|255] "raw"  MASTER,NODE1,NODE2,NODE3,NODE4,NODE5,NODE6,NODE7,NODE8,NODE9,NODE10,NODE11,NODE12,NODE13,NODE14,NODE15,NODE16,TOOL
 SG_ payload_b6 : 48|8@1+ (1,0) [0|255] "raw"  MASTER,NODE1,NODE2,NODE3,NODE4,NODE5,NODE6,NODE7,NODE8,NODE9,NODE10,NODE11,NODE12,NODE13,NODE14,NODE15,NODE16,TOOL
 SG_ payload_b7 : 56|8@1+ (1,0) [0|255] "raw"  MASTER,NODE1,NODE2,NODE3,NODE4,NODE5,NODE6,NODE7,NODE8,NODE9,NODE10,NODE11,NODE12,NODE13,NODE14,NODE15,NODE16,TOOL

BO_ 612 S1_NODE_CFG_ACK_4: 8 NODE4
 SG_ payload_b0 : 0|8@1+ (1,0) [0|255] "raw"  MASTER,NODE1,NODE2,NODE3,NODE4,NODE5,NODE6,NODE7,NODE8,NODE9,NODE10,NODE11,NODE12,NODE13,NODE14,NODE15,NODE16,TOOL
 SG_ payload_b1 : 8|8@1+ (1,0) [0|255] "raw"  MASTER,NODE1,NODE2,NODE3,NODE4,NODE5,NODE6,NODE7,NODE8,NODE9,NODE10,NODE11,NODE12,NODE13,NODE14,NODE15,NODE16,TOOL
 SG_ payload_b2 : 16|8@1+ (1,0) [0|255] "raw"  MASTER,NODE1,NODE2,NODE3,NODE4,NODE5,NODE6,NODE7,NODE8,NODE9,NODE10,NODE11,NODE12,NODE13,NODE14,NODE15,NODE16,TOOL
 SG_ payload_b3 : 24|8@1+ (1,0) [0|255] "raw"  MASTER,NODE1,NODE2,NODE3,NODE4,NODE5,NODE6,NODE7,NODE8,NODE9,NODE10,NODE11,NODE12,NODE13,NODE14,NODE15,NODE16,TOOL
 SG_ payload_b4 : 32|8@1+ (1,0) [0|255] "raw"  MASTER,NODE1,NODE2,NODE3,NODE4,NODE5,NODE6,NODE7,NODE8,NODE9,NODE10,NODE11,NODE12,NODE13,NODE14,NODE15,NODE16,TOOL
 SG_ payload_b5 : 40|8@1+ (1,0) [0|255] "raw"  MASTER,NODE1,NODE2,NODE3,NODE4,NODE5,NODE6,NODE7,NODE8,NODE9,NODE10,NODE11,NODE12,NODE13,NODE14,NODE15,NODE16,TOOL
 SG_ payload_b6 : 48|8@1+ (1,0) [0|255] "raw"  MASTER,NODE1,NODE2,NODE3,NODE4,NODE5,NODE6,NODE7,NODE8,NODE9,NODE10,NODE11,NODE12,NODE13,NODE14,NODE15,NODE16,TOOL
 SG_ payload_b7 : 56|8@1+ (1,0) [0|255] "raw"  MASTER,NODE1,NODE2,NODE3,NODE4,NODE5,NODE6,NODE7,NODE8,NODE9,NODE10,NODE11,NODE12,NODE13,NODE14,NODE15,NODE16,TOOL

BO_ 644 S1_NODE_STATUS_FAST_4: 8 NODE4
 SG_ status_flags : 0|8@1+ (1,0) [0|255] "bitfield"  MASTER,NODE1,NODE2,NODE3,NODE4,NODE5,NODE6,NODE7,NODE8,NODE9,NODE10,NODE11,NODE12,NODE13,NODE14,NODE15,NODE16,TOOL
 SG_ error_code : 8|8@1+ (1,0) [0|255] ""  MASTER,NODE1,NODE2,NODE3,NODE4,NODE5,NODE6,NODE7,NODE8,NODE9,NODE10,NODE11,NODE12,NODE13,NODE14,NODE15,NODE16,TOOL
 SG_ actual_rpm : 16|16@1- (0.1,0) [-3276.8|3276.7] "rpm"  MASTER,NODE1,NODE2,NODE3,NODE4,NODE5,NODE6,NODE7,NODE8,NODE9,NODE10,NODE11,NODE12,NODE13,NODE14,NODE15,NODE16,TOOL
 SG_ actual_pos : 32|16@1+ (1.52587890625e-05,0) [0|0.9999847412109375] "rev"  MASTER,NODE1,NODE2,NODE3,NODE4,NODE5,NODE6,NODE7,NODE8,NODE9,NODE10,NODE11,NODE12,NODE13,NODE14,NODE15,NODE16,TOOL
 SG_ alive_counter : 48|8@1+ (1,0) [0|255] ""  MASTER,NODE1,NODE2,NODE3,NODE4,NODE5,NODE6,NODE7,NODE8,NODE9,NODE10,NODE11,NODE12,NODE13,NODE14,NODE15,NODE16,TOOL
 SG_ sync_error : 56|8@1- (0.00390625,0) [-0.5|0.49609375] "rev"  MASTER,NODE1,NODE2,NODE3,NODE4,NODE5,NODE6,NODE7,NODE8,NODE9,NODE10,NODE11,NODE12,NODE13,NODE14,NODE15,NODE16,TOOL

BO_ 708 S1_NODE_DIAG_4: 8 NODE4
 SG_ bus_voltage : 0|16@1+ (0.1,0) [0|6553.5] "V"  MASTER,NODE1,NODE2,NODE3,NODE4,NODE5,NODE6,NODE7,NODE8,NODE9,NODE10,NODE11,NODE12,NODE13,NODE14,NODE15,NODE16,TOOL
 SG_ motor_current : 16|16@1- (0.1,0) [-3276.8|3276.7] "A"  MASTER,NODE1,NODE2,NODE3,NODE4,NODE5,NODE6,NODE7,NODE8,NODE9,NODE10,NODE11,NODE12,NODE13,NODE14,NODE15,NODE16,TOOL
 SG_ controller_temp : 32|8@1- (1,0) [-128|127] "degC"  MASTER,NODE1,NODE2,NODE3,NODE4,NODE5,NODE6,NODE7,NODE8,NODE9,NODE10,NODE11,NODE12,NODE13,NODE14,NODE15,NODE16,TOOL
 SG_ motor_temp : 40|8@1- (1,0) [-128|127] "degC"  MASTER,NODE1,NODE2,NODE3,NODE4,NODE5,NODE6,NODE7,NODE8,NODE9,NODE10,NODE11,NODE12,NODE13,NODE14,NODE15,NODE16,TOOL
 SG_ fault_flags : 48|8@1+ (1,0) [0|255] "bitfield"  MASTER,NODE1,NODE2,NODE3,NODE4,NODE5,NODE6,NODE7,NODE8,NODE9,NODE10,NODE11,NODE12,NODE13,NODE14,NODE15,NODE16,TOOL
 SG_ warning_flags : 56|8@1+ (1,0) [0|255] "bitfield"  MASTER,NODE1,NODE2,NODE3,NODE4,NODE5,NODE6,NODE7,NODE8,NODE9,NODE10,NODE11,NODE12,NODE13,NODE14,NODE15,NODE16,TOOL

BO_ 533 S1_NODE_CMD_5: 8 MASTER
 SG_ node_command : 0|8@1+ (1,0) [0|255] ""  MASTER,NODE1,NODE2,NODE3,NODE4,NODE5,NODE6,NODE7,NODE8,NODE9,NODE10,NODE11,NODE12,NODE13,NODE14,NODE15,NODE16,TOOL
 SG_ node_flags : 8|8@1+ (1,0) [0|255] "bitfield"  MASTER,NODE1,NODE2,NODE3,NODE4,NODE5,NODE6,NODE7,NODE8,NODE9,NODE10,NODE11,NODE12,NODE13,NODE14,NODE15,NODE16,TOOL
 SG_ trim_rpm : 16|16@1- (0.1,0) [-3276.8|3276.7] "rpm"  MASTER,NODE1,NODE2,NODE3,NODE4,NODE5,NODE6,NODE7,NODE8,NODE9,NODE10,NODE11,NODE12,NODE13,NODE14,NODE15,NODE16,TOOL
 SG_ section_mask : 32|16@1+ (1,0) [0|65535] "bitmask"  MASTER,NODE1,NODE2,NODE3,NODE4,NODE5,NODE6,NODE7,NODE8,NODE9,NODE10,NODE11,NODE12,NODE13,NODE14,NODE15,NODE16,TOOL
 SG_ seq : 48|8@1+ (1,0) [0|255] ""  MASTER,NODE1,NODE2,NODE3,NODE4,NODE5,NODE6,NODE7,NODE8,NODE9,NODE10,NODE11,NODE12,NODE13,NODE14,NODE15,NODE16,TOOL
 SG_ reserved : 56|8@1+ (1,0) [0|255] ""  MASTER,NODE1,NODE2,NODE3,NODE4,NODE5,NODE6,NODE7,NODE8,NODE9,NODE10,NODE11,NODE12,NODE13,NODE14,NODE15,NODE16,TOOL

BO_ 581 S1_NODE_PRESENCE_5: 8 NODE5
 SG_ payload_b0 : 0|8@1+ (1,0) [0|255] "raw"  MASTER,NODE1,NODE2,NODE3,NODE4,NODE5,NODE6,NODE7,NODE8,NODE9,NODE10,NODE11,NODE12,NODE13,NODE14,NODE15,NODE16,TOOL
 SG_ payload_b1 : 8|8@1+ (1,0) [0|255] "raw"  MASTER,NODE1,NODE2,NODE3,NODE4,NODE5,NODE6,NODE7,NODE8,NODE9,NODE10,NODE11,NODE12,NODE13,NODE14,NODE15,NODE16,TOOL
 SG_ payload_b2 : 16|8@1+ (1,0) [0|255] "raw"  MASTER,NODE1,NODE2,NODE3,NODE4,NODE5,NODE6,NODE7,NODE8,NODE9,NODE10,NODE11,NODE12,NODE13,NODE14,NODE15,NODE16,TOOL
 SG_ payload_b3 : 24|8@1+ (1,0) [0|255] "raw"  MASTER,NODE1,NODE2,NODE3,NODE4,NODE5,NODE6,NODE7,NODE8,NODE9,NODE10,NODE11,NODE12,NODE13,NODE14,NODE15,NODE16,TOOL
 SG_ payload_b4 : 32|8@1+ (1,0) [0|255] "raw"  MASTER,NODE1,NODE2,NODE3,NODE4,NODE5,NODE6,NODE7,NODE8,NODE9,NODE10,NODE11,NODE12,NODE13,NODE14,NODE15,NODE16,TOOL
 SG_ payload_b5 : 40|8@1+ (1,0) [0|255] "raw"  MASTER,NODE1,NODE2,NODE3,NODE4,NODE5,NODE6,NODE7,NODE8,NODE9,NODE10,NODE11,NODE12,NODE13,NODE14,NODE15,NODE16,TOOL
 SG_ payload_b6 : 48|8@1+ (1,0) [0|255] "raw"  MASTER,NODE1,NODE2,NODE3,NODE4,NODE5,NODE6,NODE7,NODE8,NODE9,NODE10,NODE11,NODE12,NODE13,NODE14,NODE15,NODE16,TOOL
 SG_ payload_b7 : 56|8@1+ (1,0) [0|255] "raw"  MASTER,NODE1,NODE2,NODE3,NODE4,NODE5,NODE6,NODE7,NODE8,NODE9,NODE10,NODE11,NODE12,NODE13,NODE14,NODE15,NODE16,TOOL

BO_ 613 S1_NODE_CFG_ACK_5: 8 NODE5
 SG_ payload_b0 : 0|8@1+ (1,0) [0|255] "raw"  MASTER,NODE1,NODE2,NODE3,NODE4,NODE5,NODE6,NODE7,NODE8,NODE9,NODE10,NODE11,NODE12,NODE13,NODE14,NODE15,NODE16,TOOL
 SG_ payload_b1 : 8|8@1+ (1,0) [0|255] "raw"  MASTER,NODE1,NODE2,NODE3,NODE4,NODE5,NODE6,NODE7,NODE8,NODE9,NODE10,NODE11,NODE12,NODE13,NODE14,NODE15,NODE16,TOOL
 SG_ payload_b2 : 16|8@1+ (1,0) [0|255] "raw"  MASTER,NODE1,NODE2,NODE3,NODE4,NODE5,NODE6,NODE7,NODE8,NODE9,NODE10,NODE11,NODE12,NODE13,NODE14,NODE15,NODE16,TOOL
 SG_ payload_b3 : 24|8@1+ (1,0) [0|255] "raw"  MASTER,NODE1,NODE2,NODE3,NODE4,NODE5,NODE6,NODE7,NODE8,NODE9,NODE10,NODE11,NODE12,NODE13,NODE14,NODE15,NODE16,TOOL
 SG_ payload_b4 : 32|8@1+ (1,0) [0|255] "raw"  MASTER,NODE1,NODE2,NODE3,NODE4,NODE5,NODE6,NODE7,NODE8,NODE9,NODE10,NODE11,NODE12,NODE13,NODE14,NODE15,NODE16,TOOL
 SG_ payload_b5 : 40|8@1+ (1,0) [0|255] "raw"  MASTER,NODE1,NODE2,NODE3,NODE4,NODE5,NODE6,NODE7,NODE8,NODE9,NODE10,NODE11,NODE12,NODE13,NODE14,NODE15,NODE16,TOOL
 SG_ payload_b6 : 48|8@1+ (1,0) [0|255] "raw"  MASTER,NODE1,NODE2,NODE3,NODE4,NODE5,NODE6,NODE7,NODE8,NODE9,NODE10,NODE11,NODE12,NODE13,NODE14,NODE15,NODE16,TOOL
 SG_ payload_b7 : 56|8@1+ (1,0) [0|255] "raw"  MASTER,NODE1,NODE2,NODE3,NODE4,NODE5,NODE6,NODE7,NODE8,NODE9,NODE10,NODE11,NODE12,NODE13,NODE14,NODE15,NODE16,TOOL

BO_ 645 S1_NODE_STATUS_FAST_5: 8 NODE5
 SG_ status_flags : 0|8@1+ (1,0) [0|255] "bitfield"  MASTER,NODE1,NODE2,NODE3,NODE4,NODE5,NODE6,NODE7,NODE8,NODE9,NODE10,NODE11,NODE12,NODE13,NODE14,NODE15,NODE16,TOOL
 SG_ error_code : 8|8@1+ (1,0) [0|255] ""  MASTER,NODE1,NODE2,NODE3,NODE4,NODE5,NODE6,NODE7,NODE8,NODE9,NODE10,NODE11,NODE12,NODE13,NODE14,NODE15,NODE16,TOOL
 SG_ actual_rpm : 16|16@1- (0.1,0) [-3276.8|3276.7] "rpm"  MASTER,NODE1,NODE2,NODE3,NODE4,NODE5,NODE6,NODE7,NODE8,NODE9,NODE10,NODE11,NODE12,NODE13,NODE14,NODE15,NODE16,TOOL
 SG_ actual_pos : 32|16@1+ (1.52587890625e-05,0) [0|0.9999847412109375] "rev"  MASTER,NODE1,NODE2,NODE3,NODE4,NODE5,NODE6,NODE7,NODE8,NODE9,NODE10,NODE11,NODE12,NODE13,NODE14,NODE15,NODE16,TOOL
 SG_ alive_counter : 48|8@1+ (1,0) [0|255] ""  MASTER,NODE1,NODE2,NODE3,NODE4,NODE5,NODE6,NODE7,NODE8,NODE9,NODE10,NODE11,NODE12,NODE13,NODE14,NODE15,NODE16,TOOL
 SG_ sync_error : 56|8@1- (0.00390625,0) [-0.5|0.49609375] "rev"  MASTER,NODE1,NODE2,NODE3,NODE4,NODE5,NODE6,NODE7,NODE8,NODE9,NODE10,NODE11,NODE12,NODE13,NODE14,NODE15,NODE16,TOOL

BO_ 709 S1_NODE_DIAG_5: 8 NODE5
 SG_ bus_voltage : 0|16@1+ (0.1,0) [0|6553.5] "V"  MASTER,NODE1,NODE2,NODE3,NODE4,NODE5,NODE6,NODE7,NODE8,NODE9,NODE10,NODE11,NODE12,NODE13,NODE14,NODE15,NODE16,TOOL
 SG_ motor_current : 16|16@1- (0.1,0) [-3276.8|3276.7] "A"  MASTER,NODE1,NODE2,NODE3,NODE4,NODE5,NODE6,NODE7,NODE8,NODE9,NODE10,NODE11,NODE12,NODE13,NODE14,NODE15,NODE16,TOOL
 SG_ controller_temp : 32|8@1- (1,0) [-128|127] "degC"  MASTER,NODE1,NODE2,NODE3,NODE4,NODE5,NODE6,NODE7,NODE8,NODE9,NODE10,NODE11,NODE12,NODE13,NODE14,NODE15,NODE16,TOOL
 SG_ motor_temp : 40|8@1- (1,0) [-128|127] "degC"  MASTER,NODE1,NODE2,NODE3,NODE4,NODE5,NODE6,NODE7,NODE8,NODE9,NODE10,NODE11,NODE12,NODE13,NODE14,NODE15,NODE16,TOOL
 SG_ fault_flags : 48|8@1+ (1,0) [0|255] "bitfield"  MASTER,NODE1,NODE2,NODE3,NODE4,NODE5,NODE6,NODE7,NODE8,NODE9,NODE10,NODE11,NODE12,NODE13,NODE14,NODE15,NODE16,TOOL
 SG_ warning_flags : 56|8@1+ (1,0) [0|255] "bitfield"  MASTER,NODE1,NODE2,NODE3,NODE4,NODE5,NODE6,NODE7,NODE8,NODE9,NODE10,NODE11,NODE12,NODE13,NODE14,NODE15,NODE16,TOOL

BO_ 534 S1_NODE_CMD_6: 8 MASTER
 SG_ node_command : 0|8@1+ (1,0) [0|255] ""  MASTER,NODE1,NODE2,NODE3,NODE4,NODE5,NODE6,NODE7,NODE8,NODE9,NODE10,NODE11,NODE12,NODE13,NODE14,NODE15,NODE16,TOOL
 SG_ node_flags : 8|8@1+ (1,0) [0|255] "bitfield"  MASTER,NODE1,NODE2,NODE3,NODE4,NODE5,NODE6,NODE7,NODE8,NODE9,NODE10,NODE11,NODE12,NODE13,NODE14,NODE15,NODE16,TOOL
 SG_ trim_rpm : 16|16@1- (0.1,0) [-3276.8|3276.7] "rpm"  MASTER,NODE1,NODE2,NODE3,NODE4,NODE5,NODE6,NODE7,NODE8,NODE9,NODE10,NODE11,NODE12,NODE13,NODE14,NODE15,NODE16,TOOL
 SG_ section_mask : 32|16@1+ (1,0) [0|65535] "bitmask"  MASTER,NODE1,NODE2,NODE3,NODE4,NODE5,NODE6,NODE7,NODE8,NODE9,NODE10,NODE11,NODE12,NODE13,NODE14,NODE15,NODE16,TOOL
 SG_ seq : 48|8@1+ (1,0) [0|255] ""  MASTER,NODE1,NODE2,NODE3,NODE4,NODE5,NODE6,NODE7,NODE8,NODE9,NODE10,NODE11,NODE12,NODE13,NODE14,NODE15,NODE16,TOOL
 SG_ reserved : 56|8@1+ (1,0) [0|255] ""  MASTER,NODE1,NODE2,NODE3,NODE4,NODE5,NODE6,NODE7,NODE8,NODE9,NODE10,NODE11,NODE12,NODE13,NODE14,NODE15,NODE16,TOOL

BO_ 582 S1_NODE_PRESENCE_6: 8 NODE6
 SG_ payload_b0 : 0|8@1+ (1,0) [0|255] "raw"  MASTER,NODE1,NODE2,NODE3,NODE4,NODE5,NODE6,NODE7,NODE8,NODE9,NODE10,NODE11,NODE12,NODE13,NODE14,NODE15,NODE16,TOOL
 SG_ payload_b1 : 8|8@1+ (1,0) [0|255] "raw"  MASTER,NODE1,NODE2,NODE3,NODE4,NODE5,NODE6,NODE7,NODE8,NODE9,NODE10,NODE11,NODE12,NODE13,NODE14,NODE15,NODE16,TOOL
 SG_ payload_b2 : 16|8@1+ (1,0) [0|255] "raw"  MASTER,NODE1,NODE2,NODE3,NODE4,NODE5,NODE6,NODE7,NODE8,NODE9,NODE10,NODE11,NODE12,NODE13,NODE14,NODE15,NODE16,TOOL
 SG_ payload_b3 : 24|8@1+ (1,0) [0|255] "raw"  MASTER,NODE1,NODE2,NODE3,NODE4,NODE5,NODE6,NODE7,NODE8,NODE9,NODE10,NODE11,NODE12,NODE13,NODE14,NODE15,NODE16,TOOL
 SG_ payload_b4 : 32|8@1+ (1,0) [0|255] "raw"  MASTER,NODE1,NODE2,NODE3,NODE4,NODE5,NODE6,NODE7,NODE8,NODE9,NODE10,NODE11,NODE12,NODE13,NODE14,NODE15,NODE16,TOOL
 SG_ payload_b5 : 40|8@1+ (1,0) [0|255] "raw"  MASTER,NODE1,NODE2,NODE3,NODE4,NODE5,NODE6,NODE7,NODE8,NODE9,NODE10,NODE11,NODE12,NODE13,NODE14,NODE15,NODE16,TOOL
 SG_ payload_b6 : 48|8@1+ (1,0) [0|255] "raw"  MASTER,NODE1,NODE2,NODE3,NODE4,NODE5,NODE6,NODE7,NODE8,NODE9,NODE10,NODE11,NODE12,NODE13,NODE14,NODE15,NODE16,TOOL
 SG_ payload_b7 : 56|8@1+ (1,0) [0|255] "raw"  MASTER,NODE1,NODE2,NODE3,NODE4,NODE5,NODE6,NODE7,NODE8,NODE9,NODE10,NODE11,NODE12,NODE13,NODE14,NODE15,NODE16,TOOL

BO_ 614 S1_NODE_CFG_ACK_6: 8 NODE6
 SG_ payload_b0 : 0|8@1+ (1,0) [0|255] "raw"  MASTER,NODE1,NODE2,NODE3,NODE4,NODE5,NODE6,NODE7,NODE8,NODE9,NODE10,NODE11,NODE12,NODE13,NODE14,NODE15,NODE16,TOOL
 SG_ payload_b1 : 8|8@1+ (1,0) [0|255] "raw"  MASTER,NODE1,NODE2,NODE3,NODE4,NODE5,NODE6,NODE7,NODE8,NODE9,NODE10,NODE11,NODE12,NODE13,NODE14,NODE15,NODE16,TOOL
 SG_ payload_b2 : 16|8@1+ (1,0) [0|255] "raw"  MASTER,NODE1,NODE2,NODE3,NODE4,NODE5,NODE6,NODE7,NODE8,NODE9,NODE10,NODE11,NODE12,NODE13,NODE14,NODE15,NODE16,TOOL
 SG_ payload_b3 : 24|8@1+ (1,0) [0|255] "raw"  MASTER,NODE1,NODE2,NODE3,NODE4,NODE5,NODE6,NODE7,NODE8,NODE9,NODE10,NODE11,NODE12,NODE13,NODE14,NODE15,NODE16,TOOL
 SG_ payload_b4 : 32|8@1+ (1,0) [0|255] "raw"  MASTER,NODE1,NODE2,NODE3,NODE4,NODE5,NODE6,NODE7,NODE8,NODE9,NODE10,NODE11,NODE12,NODE13,NODE14,NODE15,NODE16,TOOL
 SG_ payload_b5 : 40|8@1+ (1,0) [0|255] "raw"  MASTER,NODE1,NODE2,NODE3,NODE4,NODE5,NODE6,NODE7,NODE8,NODE9,NODE10,NODE11,NODE12,NODE13,NODE14,NODE15,NODE16,TOOL
 SG_ payload_b6 : 48|8@1+ (1,0) [0|255] "raw"  MASTER,NODE1,NODE2,NODE3,NODE4,NODE5,NODE6,NODE7,NODE8,NODE9,NODE10,NODE11,NODE12,NODE13,NODE14,NODE15,NODE16,TOOL
 SG_ payload_b7 : 56|8@1+ (1,0) [0|255] "raw"  MASTER,NODE1,NODE2,NODE3,NODE4,NODE5,NODE6,NODE7,NODE8,NODE9,NODE10,NODE11,NODE12,NODE13,NODE14,NODE15,NODE16,TOOL

CM_ SG_ 128 control_flags "bit0=drive_enable, bit1=sync_enable, bit2=estop, bit3=diag_enable";
CM_ SG_ 512 control_flags "bit0=drive_enable, bit1=sync_enable, bit2=estop, bit3=diag_enable";
CM_ SG_ 257 section_mask "Bytes 4-5 carry the full 16-bit section mask, not a position offset.";
CM_ SG_ 529 section_mask "Bytes 4-5 carry the full 16-bit section mask, not a position offset.";
CM_ BO_ 128 "S0 runtime bank global control.";
CM_ SG_ 257 node_flags "bit0=allow_run, bit1=invert_dir, bit2=use_local_sensor";
CM_ SG_ 257 section_mask "NODE_CMD bytes 4-5 are used as section mask in current ECU firmware, not position offset.";
CM_ SG_ 385 status_flags "bit0=ready, bit1=enabled, bit2=running, bit3=sync_locked, bit4=warning_active, bit5=fault_active, bit6=position_valid, bit7=can_timeout";
CM_ SG_ 449 fault_flags "bit0=overcurrent, bit1=undervoltage, bit2=overvoltage, bit3=overtemperature, bit4=encoder_fault, bit5=hall_fault, bit6=motor_stall, bit7=driver_fault";
CM_ SG_ 449 warning_flags "bit0=rpm_deviation, bit1=sync_deviation, bit2=temp_high, bit3=current_high, bit4=communication_late";
CM_ SG_ 258 node_flags "bit0=allow_run, bit1=invert_dir, bit2=use_local_sensor";
CM_ SG_ 258 section_mask "NODE_CMD bytes 4-5 are used as section mask in current ECU firmware, not position offset.";
CM_ SG_ 386 status_flags "bit0=ready, bit1=enabled, bit2=running, bit3=sync_locked, bit4=warning_active, bit5=fault_active, bit6=position_valid, bit7=can_timeout";
CM_ SG_ 450 fault_flags "bit0=overcurrent, bit1=undervoltage, bit2=overvoltage, bit3=overtemperature, bit4=encoder_fault, bit5=hall_fault, bit6=motor_stall, bit7=driver_fault";
CM_ SG_ 450 warning_flags "bit0=rpm_deviation, bit1=sync_deviation, bit2=temp_high, bit3=current_high, bit4=communication_late";
CM_ SG_ 259 node_flags "bit0=allow_run, bit1=invert_dir, bit2=use_local_sensor";
CM_ SG_ 259 section_mask "NODE_CMD bytes 4-5 are used as section mask in current ECU firmware, not position offset.";
CM_ SG_ 387 status_flags "bit0=ready, bit1=enabled, bit2=running, bit3=sync_locked, bit4=warning_active, bit5=fault_active, bit6=position_valid, bit7=can_timeout";
CM_ SG_ 451 fault_flags "bit0=overcurrent, bit1=undervoltage, bit2=overvoltage, bit3=overtemperature, bit4=encoder_fault, bit5=hall_fault, bit6=motor_stall, bit7=driver_fault";
CM_ SG_ 451 warning_flags "bit0=rpm_deviation, bit1=sync_deviation, bit2=temp_high, bit3=current_high, bit4=communication_late";
CM_ SG_ 260 node_flags "bit0=allow_run, bit1=invert_dir, bit2=use_local_sensor";
CM_ SG_ 260 section_mask "NODE_CMD bytes 4-5 are used as section mask in current ECU firmware, not position offset.";
CM_ SG_ 388 status_flags "bit0=ready, bit1=enabled, bit2=running, bit3=sync_locked, bit4=warning_active, bit5=fault_active, bit6=position_valid, bit7=can_timeout";
CM_ SG_ 452 fault_flags "bit0=overcurrent, bit1=undervoltage, bit2=overvoltage, bit3=overtemperature, bit4=encoder_fault, bit5=hall_fault, bit6=motor_stall, bit7=driver_fault";
CM_ SG_ 452 warning_flags "bit0=rpm_deviation, bit1=sync_deviation, bit2=temp_high, bit3=current_high, bit4=communication_late";
CM_ SG_ 261 node_flags "bit0=allow_run, bit1=invert_dir, bit2=use_local_sensor";
CM_ SG_ 261 section_mask "NODE_CMD bytes 4-5 are used as section mask in current ECU firmware, not position offset.";
CM_ SG_ 389 status_flags "bit0=ready, bit1=enabled, bit2=running, bit3=sync_locked, bit4=warning_active, bit5=fault_active, bit6=position_valid, bit7=can_timeout";
CM_ SG_ 453 fault_flags "bit0=overcurrent, bit1=undervoltage, bit2=overvoltage, bit3=overtemperature, bit4=encoder_fault, bit5=hall_fault, bit6=motor_stall, bit7=driver_fault";
CM_ SG_ 453 warning_flags "bit0=rpm_deviation, bit1=sync_deviation, bit2=temp_high, bit3=current_high, bit4=communication_late";
CM_ SG_ 262 node_flags "bit0=allow_run, bit1=invert_dir, bit2=use_local_sensor";
CM_ SG_ 262 section_mask "NODE_CMD bytes 4-5 are used as section mask in current ECU firmware, not position offset.";
CM_ SG_ 390 status_flags "bit0=ready, bit1=enabled, bit2=running, bit3=sync_locked, bit4=warning_active, bit5=fault_active, bit6=position_valid, bit7=can_timeout";
CM_ SG_ 454 fault_flags "bit0=overcurrent, bit1=undervoltage, bit2=overvoltage, bit3=overtemperature, bit4=encoder_fault, bit5=hall_fault, bit6=motor_stall, bit7=driver_fault";
CM_ SG_ 454 warning_flags "bit0=rpm_deviation, bit1=sync_deviation, bit2=temp_high, bit3=current_high, bit4=communication_late";
CM_ SG_ 263 node_flags "bit0=allow_run, bit1=invert_dir, bit2=use_local_sensor";
CM_ SG_ 263 section_mask "NODE_CMD bytes 4-5 are used as section mask in current ECU firmware, not position offset.";
CM_ SG_ 391 status_flags "bit0=ready, bit1=enabled, bit2=running, bit3=sync_locked, bit4=warning_active, bit5=fault_active, bit6=position_valid, bit7=can_timeout";
CM_ SG_ 455 fault_flags "bit0=overcurrent, bit1=undervoltage, bit2=overvoltage, bit3=overtemperature, bit4=encoder_fault, bit5=hall_fault, bit6=motor_stall, bit7=driver_fault";
CM_ SG_ 455 warning_flags "bit0=rpm_deviation, bit1=sync_deviation, bit2=temp_high, bit3=current_high, bit4=communication_late";
CM_ SG_ 264 node_flags "bit0=allow_run, bit1=invert_dir, bit2=use_local_sensor";
CM_ SG_ 264 section_mask "NODE_CMD bytes 4-5 are used as section mask in current ECU firmware, not position offset.";
CM_ SG_ 392 status_flags "bit0=ready, bit1=enabled, bit2=running, bit3=sync_locked, bit4=warning_active, bit5=fault_active, bit6=position_valid, bit7=can_timeout";
CM_ SG_ 456 fault_flags "bit0=overcurrent, bit1=undervoltage, bit2=overvoltage, bit3=overtemperature, bit4=encoder_fault, bit5=hall_fault, bit6=motor_stall, bit7=driver_fault";
CM_ SG_ 456 warning_flags "bit0=rpm_deviation, bit1=sync_deviation, bit2=temp_high, bit3=current_high, bit4=communication_late";
CM_ SG_ 265 node_flags "bit0=allow_run, bit1=invert_dir, bit2=use_local_sensor";
CM_ SG_ 265 section_mask "NODE_CMD bytes 4-5 are used as section mask in current ECU firmware, not position offset.";
CM_ SG_ 393 status_flags "bit0=ready, bit1=enabled, bit2=running, bit3=sync_locked, bit4=warning_active, bit5=fault_active, bit6=position_valid, bit7=can_timeout";
CM_ SG_ 457 fault_flags "bit0=overcurrent, bit1=undervoltage, bit2=overvoltage, bit3=overtemperature, bit4=encoder_fault, bit5=hall_fault, bit6=motor_stall, bit7=driver_fault";
CM_ SG_ 457 warning_flags "bit0=rpm_deviation, bit1=sync_deviation, bit2=temp_high, bit3=current_high, bit4=communication_late";
CM_ SG_ 266 node_flags "bit0=allow_run, bit1=invert_dir, bit2=use_local_sensor";
CM_ SG_ 266 section_mask "NODE_CMD bytes 4-5 are used as section mask in current ECU firmware, not position offset.";
CM_ SG_ 394 status_flags "bit0=ready, bit1=enabled, bit2=running, bit3=sync_locked, bit4=warning_active, bit5=fault_active, bit6=position_valid, bit7=can_timeout";
CM_ SG_ 458 fault_flags "bit0=overcurrent, bit1=undervoltage, bit2=overvoltage, bit3=overtemperature, bit4=encoder_fault, bit5=hall_fault, bit6=motor_stall, bit7=driver_fault";
CM_ SG_ 458 warning_flags "bit0=rpm_deviation, bit1=sync_deviation, bit2=temp_high, bit3=current_high, bit4=communication_late";
CM_ SG_ 267 node_flags "bit0=allow_run, bit1=invert_dir, bit2=use_local_sensor";
CM_ SG_ 267 section_mask "NODE_CMD bytes 4-5 are used as section mask in current ECU firmware, not position offset.";
CM_ SG_ 395 status_flags "bit0=ready, bit1=enabled, bit2=running, bit3=sync_locked, bit4=warning_active, bit5=fault_active, bit6=position_valid, bit7=can_timeout";
CM_ SG_ 459 fault_flags "bit0=overcurrent, bit1=undervoltage, bit2=overvoltage, bit3=overtemperature, bit4=encoder_fault, bit5=hall_fault, bit6=motor_stall, bit7=driver_fault";
CM_ SG_ 459 warning_flags "bit0=rpm_deviation, bit1=sync_deviation, bit2=temp_high, bit3=current_high, bit4=communication_late";
CM_ SG_ 268 node_flags "bit0=allow_run, bit1=invert_dir, bit2=use_local_sensor";
CM_ SG_ 268 section_mask "NODE_CMD bytes 4-5 are used as section mask in current ECU firmware, not position offset.";
CM_ SG_ 396 status_flags "bit0=ready, bit1=enabled, bit2=running, bit3=sync_locked, bit4=warning_active, bit5=fault_active, bit6=position_valid, bit7=can_timeout";
CM_ SG_ 460 fault_flags "bit0=overcurrent, bit1=undervoltage, bit2=overvoltage, bit3=overtemperature, bit4=encoder_fault, bit5=hall_fault, bit6=motor_stall, bit7=driver_fault";
CM_ SG_ 460 warning_flags "bit0=rpm_deviation, bit1=sync_deviation, bit2=temp_high, bit3=current_high, bit4=communication_late";
CM_ SG_ 269 node_flags "bit0=allow_run, bit1=invert_dir, bit2=use_local_sensor";
CM_ SG_ 269 section_mask "NODE_CMD bytes 4-5 are used as section mask in current ECU firmware, not position offset.";
CM_ SG_ 397 status_flags "bit0=ready, bit1=enabled, bit2=running, bit3=sync_locked, bit4=warning_active, bit5=fault_active, bit6=position_valid, bit7=can_timeout";
CM_ SG_ 461 fault_flags "bit0=overcurrent, bit1=undervoltage, bit2=overvoltage, bit3=overtemperature, bit4=encoder_fault, bit5=hall_fault, bit6=motor_stall, bit7=driver_fault";
CM_ SG_ 461 warning_flags "bit0=rpm_deviation, bit1=sync_deviation, bit2=temp_high, bit3=current_high, bit4=communication_late";
CM_ SG_ 270 node_flags "bit0=allow_run, bit1=invert_dir, bit2=use_local_sensor";
CM_ SG_ 270 section_mask "NODE_CMD bytes 4-5 are used as section mask in current ECU firmware, not position offset.";
CM_ SG_ 398 status_flags "bit0=ready, bit1=enabled, bit2=running, bit3=sync_locked, bit4=warning_active, bit5=fault_active, bit6=position_valid, bit7=can_timeout";
CM_ SG_ 462 fault_flags "bit0=overcurrent, bit1=undervoltage, bit2=overvoltage, bit3=overtemperature, bit4=encoder_fault, bit5=hall_fault, bit6=motor_stall, bit7=driver_fault";
CM_ SG_ 462 warning_flags "bit0=rpm_deviation, bit1=sync_deviation, bit2=temp_high, bit3=current_high, bit4=communication_late";
CM_ SG_ 271 node_flags "bit0=allow_run, bit1=invert_dir, bit2=use_local_sensor";
CM_ SG_ 271 section_mask "NODE_CMD bytes 4-5 are used as section mask in current ECU firmware, not position offset.";
CM_ SG_ 399 status_flags "bit0=ready, bit1=enabled, bit2=running, bit3=sync_locked, bit4=warning_active, bit5=fault_active, bit6=position_valid, bit7=can_timeout";
CM_ SG_ 463 fault_flags "bit0=overcurrent, bit1=undervoltage, bit2=overvoltage, bit3=overtemperature, bit4=encoder_fault, bit5=hall_fault, bit6=motor_stall, bit7=driver_fault";
CM_ SG_ 463 warning_flags "bit0=rpm_deviation, bit1=sync_deviation, bit2=temp_high, bit3=current_high, bit4=communication_late";
CM_ SG_ 272 node_flags "bit0=allow_run, bit1=invert_dir, bit2=use_local_sensor";
CM_ SG_ 272 section_mask "NODE_CMD bytes 4-5 are used as section mask in current ECU firmware, not position offset.";
CM_ SG_ 400 status_flags "bit0=ready, bit1=enabled, bit2=running, bit3=sync_locked, bit4=warning_active, bit5=fault_active, bit6=position_valid, bit7=can_timeout";
CM_ SG_ 464 fault_flags "bit0=overcurrent, bit1=undervoltage, bit2=overvoltage, bit3=overtemperature, bit4=encoder_fault, bit5=hall_fault, bit6=motor_stall, bit7=driver_fault";
CM_ SG_ 464 warning_flags "bit0=rpm_deviation, bit1=sync_deviation, bit2=temp_high, bit3=current_high, bit4=communication_late";
CM_ BO_ 512 "S1 runtime bank global control.";
CM_ SG_ 529 node_flags "bit0=allow_run, bit1=invert_dir, bit2=use_local_sensor";
CM_ SG_ 529 section_mask "NODE_CMD bytes 4-5 are used as section mask in current ECU firmware, not position offset.";
CM_ SG_ 641 status_flags "bit0=ready, bit1=enabled, bit2=running, bit3=sync_locked, bit4=warning_active, bit5=fault_active, bit6=position_valid, bit7=can_timeout";
CM_ SG_ 705 fault_flags "bit0=overcurrent, bit1=undervoltage, bit2=overvoltage, bit3=overtemperature, bit4=encoder_fault, bit5=hall_fault, bit6=motor_stall, bit7=driver_fault";
CM_ SG_ 705 warning_flags "bit0=rpm_deviation, bit1=sync_deviation, bit2=temp_high, bit3=current_high, bit4=communication_late";
CM_ SG_ 530 node_flags "bit0=allow_run, bit1=invert_dir, bit2=use_local_sensor";
CM_ SG_ 530 section_mask "NODE_CMD bytes 4-5 are used as section mask in current ECU firmware, not position offset.";
CM_ SG_ 642 status_flags "bit0=ready, bit1=enabled, bit2=running, bit3=sync_locked, bit4=warning_active, bit5=fault_active, bit6=position_valid, bit7=can_timeout";
CM_ SG_ 706 fault_flags "bit0=overcurrent, bit1=undervoltage, bit2=overvoltage, bit3=overtemperature, bit4=encoder_fault, bit5=hall_fault, bit6=motor_stall, bit7=driver_fault";
CM_ SG_ 706 warning_flags "bit0=rpm_deviation, bit1=sync_deviation, bit2=temp_high, bit3=current_high, bit4=communication_late";
CM_ SG_ 531 node_flags "bit0=allow_run, bit1=invert_dir, bit2=use_local_sensor";
CM_ SG_ 531 section_mask "NODE_CMD bytes 4-5 are used as section mask in current ECU firmware, not position offset.";
CM_ SG_ 643 status_flags "bit0=ready, bit1=enabled, bit2=running, bit3=sync_locked, bit4=warning_active, bit5=fault_active, bit6=position_valid, bit7=can_timeout";
CM_ SG_ 707 fault_flags "bit0=overcurrent, bit1=undervoltage, bit2=overvoltage, bit3=overtemperature, bit4=encoder_fault, bit5=hall_fault, bit6=motor_stall, bit7=driver_fault";
CM_ SG_ 707 warning_flags "bit0=rpm_deviation, bit1=sync_deviation, bit2=temp_high, bit3=current_high, bit4=communication_late";
CM_ SG_ 532 node_flags "bit0=allow_run, bit1=invert_dir, bit2=use_local_sensor";
CM_ SG_ 532 section_mask "NODE_CMD bytes 4-5 are used as section mask in current ECU firmware, not position offset.";
CM_ SG_ 644 status_flags "bit0=ready, bit1=enabled, bit2=running, bit3=sync_locked, bit4=warning_active, bit5=fault_active, bit6=position_valid, bit7=can_timeout";
CM_ SG_ 708 fault_flags "bit0=overcurrent, bit1=undervoltage, bit2=overvoltage, bit3=overtemperature, bit4=encoder_fault, bit5=hall_fault, bit6=motor_stall, bit7=driver_fault";
CM_ SG_ 708 warning_flags "bit0=rpm_deviation, bit1=sync_deviation, bit2=temp_high, bit3=current_high, bit4=communication_late";
CM_ SG_ 533 node_flags "bit0=allow_run, bit1=invert_dir, bit2=use_local_sensor";
CM_ SG_ 533 section_mask "NODE_CMD bytes 4-5 are used as section mask in current ECU firmware, not position offset.";
CM_ SG_ 645 status_flags "bit0=ready, bit1=enabled, bit2=running, bit3=sync_locked, bit4=warning_active, bit5=fault_active, bit6=position_valid, bit7=can_timeout";
CM_ SG_ 709 fault_flags "bit0=overcurrent, bit1=undervoltage, bit2=overvoltage, bit3=overtemperature, bit4=encoder_fault, bit5=hall_fault, bit6=motor_stall, bit7=driver_fault";
CM_ SG_ 709 warning_flags "bit0=rpm_deviation, bit1=sync_deviation, bit2=temp_high, bit3=current_high, bit4=communication_late";
CM_ SG_ 534 node_flags "bit0=allow_run, bit1=invert_dir, bit2=use_local_sensor";
CM_ SG_ 534 section_mask "NODE_CMD bytes 4-5 are used as section mask in current ECU firmware, not position offset.";

BA_DEF_ BO_  "GenMsgCycleTime" INT 0 65535;
BA_DEF_DEF_  "GenMsgCycleTime" 0;
BA_ "GenMsgCycleTime" BO_ 128 20;
BA_ "GenMsgCycleTime" BO_ 129 100;
BA_ "GenMsgCycleTime" BO_ 257 50;
BA_ "GenMsgCycleTime" BO_ 321 1000;
BA_ "GenMsgCycleTime" BO_ 385 20;
BA_ "GenMsgCycleTime" BO_ 449 100;
BA_ "GenMsgCycleTime" BO_ 258 50;
BA_ "GenMsgCycleTime" BO_ 322 1000;
BA_ "GenMsgCycleTime" BO_ 386 20;
BA_ "GenMsgCycleTime" BO_ 450 100;
BA_ "GenMsgCycleTime" BO_ 259 50;
BA_ "GenMsgCycleTime" BO_ 323 1000;
BA_ "GenMsgCycleTime" BO_ 387 20;
BA_ "GenMsgCycleTime" BO_ 451 100;
BA_ "GenMsgCycleTime" BO_ 260 50;
BA_ "GenMsgCycleTime" BO_ 324 1000;
BA_ "GenMsgCycleTime" BO_ 388 20;
BA_ "GenMsgCycleTime" BO_ 452 100;
BA_ "GenMsgCycleTime" BO_ 261 50;
BA_ "GenMsgCycleTime" BO_ 325 1000;
BA_ "GenMsgCycleTime" BO_ 389 20;
BA_ "GenMsgCycleTime" BO_ 453 100;
BA_ "GenMsgCycleTime" BO_ 262 50;
BA_ "GenMsgCycleTime" BO_ 326 1000;
BA_ "GenMsgCycleTime" BO_ 390 20;
BA_ "GenMsgCycleTime" BO_ 454 100;
BA_ "GenMsgCycleTime" BO_ 263 50;
BA_ "GenMsgCycleTime" BO_ 327 1000;
BA_ "GenMsgCycleTime" BO_ 391 20;
BA_ "GenMsgCycleTime" BO_ 455 100;
BA_ "GenMsgCycleTime" BO_ 264 50;
BA_ "GenMsgCycleTime" BO_ 328 1000;
BA_ "GenMsgCycleTime" BO_ 392 20;
BA_ "GenMsgCycleTime" BO_ 456 100;
BA_ "GenMsgCycleTime" BO_ 265 50;
BA_ "GenMsgCycleTime" BO_ 329 1000;
BA_ "GenMsgCycleTime" BO_ 393 20;
BA_ "GenMsgCycleTime" BO_ 457 100;
BA_ "GenMsgCycleTime" BO_ 266 50;
BA_ "GenMsgCycleTime" BO_ 330 1000;
BA_ "GenMsgCycleTime" BO_ 394 20;
BA_ "GenMsgCycleTime" BO_ 458 100;
BA_ "GenMsgCycleTime" BO_ 267 50;
BA_ "GenMsgCycleTime" BO_ 331 1000;
BA_ "GenMsgCycleTime" BO_ 395 20;
BA_ "GenMsgCycleTime" BO_ 459 100;
BA_ "GenMsgCycleTime" BO_ 268 50;
BA_ "GenMsgCycleTime" BO_ 332 1000;
BA_ "GenMsgCycleTime" BO_ 396 20;
BA_ "GenMsgCycleTime" BO_ 460 100;
BA_ "GenMsgCycleTime" BO_ 269 50;
BA_ "GenMsgCycleTime" BO_ 333 1000;
BA_ "GenMsgCycleTime" BO_ 397 20;
BA_ "GenMsgCycleTime" BO_ 461 100;
BA_ "GenMsgCycleTime" BO_ 270 50;
BA_ "GenMsgCycleTime" BO_ 334 1000;
BA_ "GenMsgCycleTime" BO_ 398 20;
BA_ "GenMsgCycleTime" BO_ 462 100;
BA_ "GenMsgCycleTime" BO_ 271 50;
BA_ "GenMsgCycleTime" BO_ 335 1000;
BA_ "GenMsgCycleTime" BO_ 399 20;
BA_ "GenMsgCycleTime" BO_ 463 100;
BA_ "GenMsgCycleTime" BO_ 272 50;
BA_ "GenMsgCycleTime" BO_ 336 1000;
BA_ "GenMsgCycleTime" BO_ 400 20;
BA_ "GenMsgCycleTime" BO_ 464 100;
BA_ "GenMsgCycleTime" BO_ 512 20;
BA_ "GenMsgCycleTime" BO_ 513 100;
BA_ "GenMsgCycleTime" BO_ 529 50;
BA_ "GenMsgCycleTime" BO_ 577 1000;
BA_ "GenMsgCycleTime" BO_ 641 20;
BA_ "GenMsgCycleTime" BO_ 705 100;
BA_ "GenMsgCycleTime" BO_ 530 50;
BA_ "GenMsgCycleTime" BO_ 578 1000;
BA_ "GenMsgCycleTime" BO_ 642 20;
BA_ "GenMsgCycleTime" BO_ 706 100;
BA_ "GenMsgCycleTime" BO_ 531 50;
BA_ "GenMsgCycleTime" BO_ 579 1000;
BA_ "GenMsgCycleTime" BO_ 643 20;
BA_ "GenMsgCycleTime" BO_ 707 100;
BA_ "GenMsgCycleTime" BO_ 532 50;
BA_ "GenMsgCycleTime" BO_ 580 1000;
BA_ "GenMsgCycleTime" BO_ 644 20;
BA_ "GenMsgCycleTime" BO_ 708 100;
BA_ "GenMsgCycleTime" BO_ 533 50;
BA_ "GenMsgCycleTime" BO_ 581 1000;
BA_ "GenMsgCycleTime" BO_ 645 20;
BA_ "GenMsgCycleTime" BO_ 709 100;
BA_ "GenMsgCycleTime" BO_ 534 50;
BA_ "GenMsgCycleTime" BO_ 582 1000;

VAL_ 128 system_mode 0 "OFF" 1 "MANUAL" 2 "AUTO" 3 "CALIBRATION" 4 "FAULT_HOLD";
VAL_ 130 estop_cmd 165 "EMERGENCY_STOP";
VAL_ 130 reason 0 "manual" 1 "comm_fault" 2 "master_fault";
VAL_ 257 node_command 0 "NOP" 1 "ENABLE" 2 "DISABLE" 3 "ZERO_POS" 4 "CLEAR_FAULT";
VAL_ 258 node_command 0 "NOP" 1 "ENABLE" 2 "DISABLE" 3 "ZERO_POS" 4 "CLEAR_FAULT";
VAL_ 259 node_command 0 "NOP" 1 "ENABLE" 2 "DISABLE" 3 "ZERO_POS" 4 "CLEAR_FAULT";
VAL_ 260 node_command 0 "NOP" 1 "ENABLE" 2 "DISABLE" 3 "ZERO_POS" 4 "CLEAR_FAULT";
VAL_ 261 node_command 0 "NOP" 1 "ENABLE" 2 "DISABLE" 3 "ZERO_POS" 4 "CLEAR_FAULT";
VAL_ 262 node_command 0 "NOP" 1 "ENABLE" 2 "DISABLE" 3 "ZERO_POS" 4 "CLEAR_FAULT";
VAL_ 263 node_command 0 "NOP" 1 "ENABLE" 2 "DISABLE" 3 "ZERO_POS" 4 "CLEAR_FAULT";
VAL_ 264 node_command 0 "NOP" 1 "ENABLE" 2 "DISABLE" 3 "ZERO_POS" 4 "CLEAR_FAULT";
VAL_ 265 node_command 0 "NOP" 1 "ENABLE" 2 "DISABLE" 3 "ZERO_POS" 4 "CLEAR_FAULT";
VAL_ 266 node_command 0 "NOP" 1 "ENABLE" 2 "DISABLE" 3 "ZERO_POS" 4 "CLEAR_FAULT";
VAL_ 267 node_command 0 "NOP" 1 "ENABLE" 2 "DISABLE" 3 "ZERO_POS" 4 "CLEAR_FAULT";
VAL_ 268 node_command 0 "NOP" 1 "ENABLE" 2 "DISABLE" 3 "ZERO_POS" 4 "CLEAR_FAULT";
VAL_ 269 node_command 0 "NOP" 1 "ENABLE" 2 "DISABLE" 3 "ZERO_POS" 4 "CLEAR_FAULT";
VAL_ 270 node_command 0 "NOP" 1 "ENABLE" 2 "DISABLE" 3 "ZERO_POS" 4 "CLEAR_FAULT";
VAL_ 271 node_command 0 "NOP" 1 "ENABLE" 2 "DISABLE" 3 "ZERO_POS" 4 "CLEAR_FAULT";
VAL_ 272 node_command 0 "NOP" 1 "ENABLE" 2 "DISABLE" 3 "ZERO_POS" 4 "CLEAR_FAULT";
VAL_ 512 system_mode 0 "OFF" 1 "MANUAL" 2 "AUTO" 3 "CALIBRATION" 4 "FAULT_HOLD";
VAL_ 514 estop_cmd 165 "EMERGENCY_STOP";
VAL_ 514 reason 0 "manual" 1 "comm_fault" 2 "master_fault";
VAL_ 529 node_command 0 "NOP" 1 "ENABLE" 2 "DISABLE" 3 "ZERO_POS" 4 "CLEAR_FAULT";
VAL_ 530 node_command 0 "NOP" 1 "ENABLE" 2 "DISABLE" 3 "ZERO_POS" 4 "CLEAR_FAULT";
VAL_ 531 node_command 0 "NOP" 1 "ENABLE" 2 "DISABLE" 3 "ZERO_POS" 4 "CLEAR_FAULT";
VAL_ 532 node_command 0 "NOP" 1 "ENABLE" 2 "DISABLE" 3 "ZERO_POS" 4 "CLEAR_FAULT";
VAL_ 533 node_command 0 "NOP" 1 "ENABLE" 2 "DISABLE" 3 "ZERO_POS" 4 "CLEAR_FAULT";
VAL_ 534 node_command 0 "NOP" 1 "ENABLE" 2 "DISABLE" 3 "ZERO_POS" 4 "CLEAR_FAULT";
